VERSION "HNNBNNNYNNNNNNNNNNNNNNNNNNNNNNNNNNNNNNNNNN/4/%%%/4/'%**4NNN///"

NS_ :

BS_:

BU_: Airbag BAP_Tester ICAS1_Gateway ICAS1_KommunikationsServer LE1 LE2 Motor_BEV Schaltbetaetigung

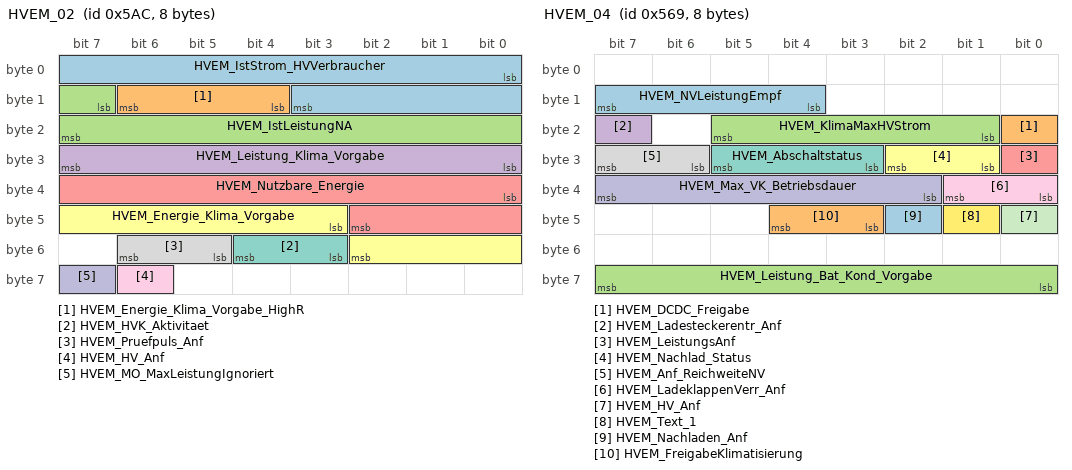
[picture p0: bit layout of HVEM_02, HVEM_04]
BO_ 1452 HVEM_02: 8 ICAS1_Gateway
 SG_ HVEM_IstStrom_HVVerbraucher : 0|12@1+ (0.1,-204.7) [-204.7|204.6] "Unit_Amper"  Vector__XXX
 SG_ HVEM_Energie_Klima_Vorgabe_HighR : 12|3@1+ (10,0) [0|50] "Unit_WattHour"  Vector__XXX
 SG_ HVEM_IstLeistungNA : 15|9@1+ (50,0) [0|25450] "Unit_Watt"  Motor_BEV
 SG_ HVEM_Leistung_Klima_Vorgabe : 24|8@1+ (50,0) [0|12650] "Unit_Watt"  Vector__XXX
 SG_ HVEM_Nutzbare_Energie : 32|11@1+ (50,0) [0|102200] "Unit_WattHour"  Vector__XXX
 SG_ HVEM_Energie_Klima_Vorgabe : 43|8@1+ (50,0) [0|12650] "Unit_WattHour"  Vector__XXX
 SG_ HVEM_HVK_Aktivitaet : 51|2@1+ (1.0,0.0) [0.0|3] ""  Motor_BEV
 SG_ HVEM_Pruefpuls_Anf : 53|2@1+ (1.0,0.0) [0.0|3] ""  Motor_BEV
 SG_ HVEM_HV_Anf : 62|1@1+ (1.0,0.0) [0.0|1] ""  Motor_BEV
 SG_ HVEM_MO_MaxLeistungIgnoriert : 63|1@1+ (1.0,0.0) [0.0|1] ""  Vector__XXX

BO_ 1385 HVEM_04: 8 ICAS1_Gateway
 SG_ HVEM_NVLeistungEmpf : 12|4@1+ (100,0) [0|1500] "Unit_Watt"  Vector__XXX
 SG_ HVEM_DCDC_Freigabe : 16|1@1+ (1.0,0.0) [0.0|1] ""  Motor_BEV
 SG_ HVEM_KlimaMaxHVStrom : 17|5@1+ (1,0) [0|31] "Unit_Amper"  Vector__XXX
 SG_ HVEM_Ladesteckerentr_Anf : 23|1@1+ (1.0,0.0) [0.0|1] ""  Vector__XXX
 SG_ HVEM_LeistungsAnf : 24|1@1+ (1.0,0.0) [0.0|1] ""  Vector__XXX
 SG_ HVEM_Nachlad_Status : 25|2@1+ (1.0,0.0) [0.0|3] ""  Vector__XXX
 SG_ HVEM_Abschaltstatus : 27|3@1+ (1.0,0.0) [0.0|7] ""  Vector__XXX
 SG_ HVEM_Anf_ReichweiteNV : 30|2@1+ (1.0,0.0) [0.0|3] ""  Vector__XXX
 SG_ HVEM_LadeklappenVerr_Anf : 32|2@1+ (1.0,0.0) [0.0|3] ""  Vector__XXX
 SG_ HVEM_Max_VK_Betriebsdauer : 34|6@1+ (1,0) [0|60] "Unit_Minut"  Vector__XXX
 SG_ HVEM_HV_Anf : 40|1@1+ (1.0,0.0) [0.0|1] ""  Vector__XXX
 SG_ HVEM_Text_1 : 41|1@1+ (1.0,0.0) [0.0|1] ""  Vector__XXX
 SG_ HVEM_Nachladen_Anf : 42|1@1+ (1.0,0.0) [0.0|1] ""  Vector__XXX
 SG_ HVEM_FreigabeKlimatisierung : 43|2@1+ (1.0,0.0) [0.0|3] ""  Vector__XXX
 SG_ HVEM_Leistung_Bat_Kond_Vorgabe : 56|8@1+ (50,0) [0|12650] "Unit_Watt"  Vector__XXX

BO_ 1283 HVK_01: 8 Motor_BEV
 SG_ HVK_01_CRC : 0|8@1+ (1,0) [0|255] ""  ICAS1_Gateway,LE1,LE2
 SG_ HVK_01_BZ : 8|4@1+ (1,0) [0|15] ""  ICAS1_Gateway,LE1,LE2
 SG_ HVK_Istmodus_Anf : 12|1@1+ (1.0,0.0) [0.0|1] ""  ICAS1_Gateway
 SG_ HVK_TN1_Sollmodus : 13|2@1+ (1.0,0.0) [0.0|3] ""  ICAS1_Gateway
 SG_ HVK_Vorladung_aktiv : 15|1@1+ (1.0,0.0) [0.0|1] ""  ICAS1_Gateway
 SG_ HVK_BMS_Sollmodus : 24|3@1+ (1.0,0.0) [0.0|7] ""  ICAS1_Gateway
 SG_ HVK_DCDC_Sollmodus : 27|3@1+ (1.0,0.0) [0.0|7] ""  ICAS1_Gateway
 SG_ HVK_EKK_Sollmodus : 30|3@1+ (1.0,0.0) [0.0|7] ""  ICAS1_Gateway
 SG_ HVK_HVPTC_Sollmodus : 33|3@1+ (1.0,0.0) [0.0|7] ""  ICAS1_Gateway
 SG_ HVK_HVLM_Sollmodus : 36|3@1+ (1.0,0.0) [0.0|7] ""  ICAS1_Gateway
 SG_ HVK_HV_Netz_Warnungen : 39|2@1+ (1.0,0.0) [0.0|3] ""  ICAS1_Gateway,ICAS1_KommunikationsServer
 SG_ HV_Bordnetz_aktiv : 41|1@1+ (1.0,0.0) [0.0|1] ""  ICAS1_Gateway,LE1,LE2
 SG_ HV_Bordnetz_Fehler : 42|1@1+ (1.0,0.0) [0.0|1] ""  ICAS1_Gateway
 SG_ HVK_Gesamtst_Spgfreiheit : 43|2@1+ (1.0,0.0) [0.0|3] ""  ICAS1_Gateway,ICAS1_KommunikationsServer
 SG_ HVK_AktiveEntladung_Anf : 45|1@1+ (1.0,0.0) [0.0|1] ""  ICAS1_Gateway,LE1,LE2
 SG_ HVK_HVEM_Freigabe : 46|2@1+ (1.0,0.0) [0.0|3] ""  ICAS1_Gateway
 SG_ HVK_Notentladung_Anf : 48|2@1+ (1.0,0.0) [0.0|3] ""  ICAS1_Gateway,LE1,LE2
 SG_ HVK_Iso_Messung_Start : 50|3@1+ (1.0,0.0) [0.0|7] ""  ICAS1_Gateway
 SG_ HVK_Ladebereit : 53|3@1+ (1.0,0.0) [0.0|7] ""  ICAS1_Gateway
 SG_ HVK_PPulsFreigabe : 56|2@1+ (1.0,0.0) [0.0|3] ""  ICAS1_Gateway

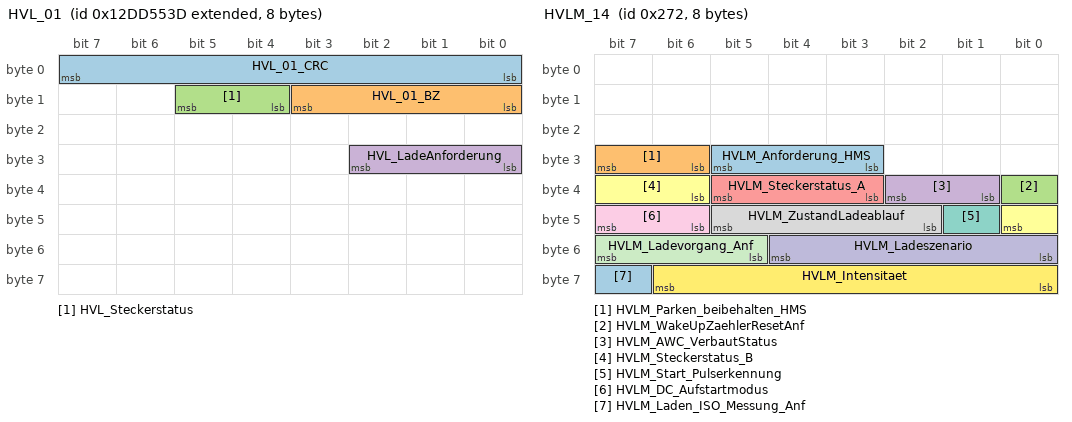
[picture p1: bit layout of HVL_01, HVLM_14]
BO_ 2463978813 HVL_01: 8 ICAS1_Gateway
 SG_ HVL_01_CRC : 0|8@1+ (1,0) [0|255] ""  Motor_BEV
 SG_ HVL_01_BZ : 8|4@1+ (1,0) [0|15] ""  Motor_BEV
 SG_ HVL_Steckerstatus : 12|2@1+ (1.0,0.0) [0.0|3] ""  Motor_BEV
 SG_ HVL_LadeAnforderung : 24|3@1+ (1.0,0.0) [0.0|7] ""  Motor_BEV

BO_ 626 HVLM_14: 8 ICAS1_Gateway
 SG_ HVLM_Anforderung_HMS : 27|3@1+ (1.0,0.0) [0.0|7] ""  Vector__XXX
 SG_ HVLM_Parken_beibehalten_HMS : 30|2@1+ (1.0,0.0) [0.0|3] ""  Vector__XXX
 SG_ HVLM_WakeUpZaehlerResetAnf : 32|1@1+ (1.0,0.0) [0.0|1] ""  Vector__XXX
 SG_ HVLM_AWC_VerbautStatus : 33|2@1+ (1.0,0.0) [0.0|3] ""  Motor_BEV
 SG_ HVLM_Steckerstatus_A : 35|3@1+ (1.0,0.0) [0.0|7] ""  Motor_BEV
 SG_ HVLM_Steckerstatus_B : 38|3@1+ (1.0,0.0) [0.0|7] ""  Vector__XXX
 SG_ HVLM_Start_Pulserkennung : 41|1@1+ (1.0,0.0) [0.0|1] ""  Vector__XXX
 SG_ HVLM_ZustandLadeablauf : 42|4@1+ (1.0,0.0) [0.0|15] ""  Motor_BEV
 SG_ HVLM_DC_Aufstartmodus : 46|2@1+ (1.0,0.0) [0.0|3] ""  Motor_BEV
 SG_ HVLM_Ladeszenario : 48|5@1+ (1.0,0.0) [0.0|31] ""  Vector__XXX
 SG_ HVLM_Ladevorgang_Anf : 53|3@1+ (1.0,0.0) [0.0|7] ""  Motor_BEV
 SG_ HVLM_Intensitaet : 56|7@1+ (1,0) [0|100] "Unit_PerCent"  Vector__XXX
 SG_ HVLM_Laden_ISO_Messung_Anf : 63|1@1+ (1.0,0.0) [0.0|1] ""  Motor_BEV

BO_ 268 IMMO_CORD_01: 8 Motor_BEV
 SG_ ImoCord_Auth_Aufforderung_WFS : 63|1@1+ (1.0,0.0) [0.0|1] ""  LE1,LE2

BO_ 23 IMMO_MSG3_Antwort: 8 ICAS1_Gateway
 SG_ WFS_IMMO_MSG3_CRC : 0|32@1+ (1.0,0.0) [0.0|4294967295] ""  LE2
 SG_ WFS_IMMO_MSG3_Status : 56|8@1+ (1,0) [0|255] ""  LE2

BO_ 25 IMMO_MSG4_Antwort: 8 ICAS1_Gateway
 SG_ WFS_IMMO_MSG4_CRC : 0|32@1+ (1.0,0.0) [0.0|4294967295] ""  LE1
 SG_ WFS_IMMO_MSG4_Status : 56|8@1+ (1,0) [0|255] ""  LE1

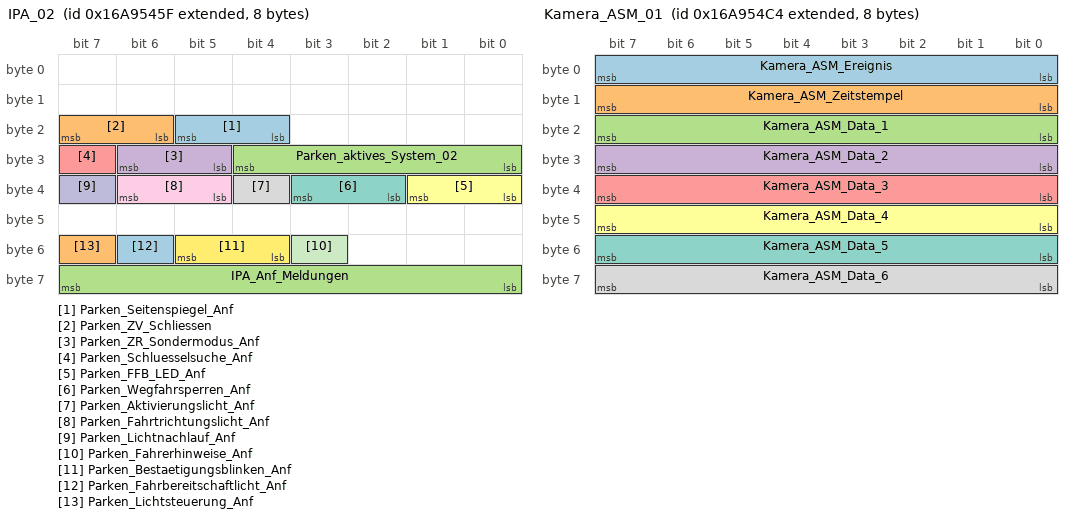
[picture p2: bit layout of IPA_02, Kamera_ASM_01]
BO_ 2527679583 IPA_02: 8 ICAS1_Gateway
 SG_ Parken_Seitenspiegel_Anf : 20|2@1+ (1.0,0.0) [0.0|3] ""  Vector__XXX
 SG_ Parken_ZV_Schliessen : 22|2@1+ (1.0,0.0) [0.0|3] ""  Vector__XXX
 SG_ Parken_aktives_System_02 : 24|5@1+ (1.0,0.0) [0.0|31] ""  Vector__XXX
 SG_ Parken_ZR_Sondermodus_Anf : 29|2@1+ (1.0,0.0) [0.0|3] ""  Vector__XXX
 SG_ Parken_Schluesselsuche_Anf : 31|1@1+ (1.0,0.0) [0.0|1] ""  Vector__XXX
 SG_ Parken_FFB_LED_Anf : 32|2@1+ (1.0,0.0) [0.0|3] ""  Vector__XXX
 SG_ Parken_Wegfahrsperren_Anf : 34|2@1+ (1.0,0.0) [0.0|3] ""  LE1,LE2
 SG_ Parken_Aktivierungslicht_Anf : 36|1@1+ (1.0,0.0) [0.0|1] ""  Vector__XXX
 SG_ Parken_Fahrtrichtungslicht_Anf : 37|2@1+ (1.0,0.0) [0.0|3] ""  Vector__XXX
 SG_ Parken_Lichtnachlauf_Anf : 39|1@1+ (1.0,0.0) [0.0|1] ""  Vector__XXX
 SG_ Parken_Fahrerhinweise_Anf : 51|1@1+ (1.0,0.0) [0.0|1] ""  Vector__XXX
 SG_ Parken_Bestaetigungsblinken_Anf : 52|2@1+ (1.0,0.0) [0.0|3] ""  Vector__XXX
 SG_ Parken_Fahrbereitschaftlicht_Anf : 54|1@1+ (1.0,0.0) [0.0|1] ""  Vector__XXX
 SG_ Parken_Lichtsteuerung_Anf : 55|1@1+ (1.0,0.0) [0.0|1] ""  Vector__XXX
 SG_ IPA_Anf_Meldungen : 56|8@1+ (1.0,0.0) [0.0|255] ""  Vector__XXX

BO_ 1813 ISO_Airbag_01_Req: 8 ICAS1_Gateway
 SG_ ISO_Airbag_01_Req_Data : 0|64@1+ (1.0,0.0) [0.0|18446744073709551615] ""  Airbag

BO_ 1919 ISO_Airbag_01_Resp: 8 Airbag
 SG_ ISO_Airbag_01_Resp_Data : 0|64@1+ (1.0,0.0) [0.0|18446744073709551615] ""  ICAS1_Gateway

BO_ 1792 ISO_Funktionaler_Req_All: 8 ICAS1_Gateway
 SG_ ISO_ALL_01_Req_Data : 0|64@1+ (1.0,0.0) [0.0|18446744073709551615] ""  Airbag,LE1,LE2,Motor_BEV

BO_ 2621440021 ISOx_Airbag_01_Req_FD: 64 ICAS1_Gateway
 SG_ ISOx_Airbag_01_Req_FD_Data : 0|512@1+ (1.0,0.0) [0.0|13407807929942597099574024998205846127479365820592393377723561443721764030073546976801874298166903427690031858186486050853753882811946569946433649006084095] ""  Airbag

BO_ 2621571093 ISOx_Airbag_01_Resp_FD: 64 Airbag
 SG_ ISOx_Airbag_01_Resp_FD_Data : 0|512@1+ (1.0,0.0) [0.0|13407807929942597099574024998205846127479365820592393377723561443721764030073546976801874298166903427690031858186486050853753882811946569946433649006084095] ""  ICAS1_Gateway

BO_ 2549874812 ISOx_EMotor_01_Req: 8 ICAS1_Gateway
 SG_ ISO_EMotor_01_Req_Data : 0|64@1+ (1.0,0.0) [0.0|18446744073709551615] ""  LE1

BO_ 2621440124 ISOx_EMotor_01_Req_FD: 64 ICAS1_Gateway
 SG_ ISOx_EMotor_01_Req_FD_Data : 0|512@1+ (1.0,0.0) [0.0|13407807929942597099574024998205846127479365820592393377723561443721764030073546976801874298166903427690031858186486050853753882811946569946433649006084095] ""  LE1

BO_ 2550005884 ISOx_EMotor_01_Resp: 8 LE1
 SG_ ISO_EMotor_01_Resp_Data : 0|64@1+ (1.0,0.0) [0.0|18446744073709551615] ""  ICAS1_Gateway

BO_ 2621571196 ISOx_EMotor_01_Resp_FD: 64 LE1
 SG_ ISOx_EMotor_01_Resp_FD_Data : 0|512@1+ (1.0,0.0) [0.0|13407807929942597099574024998205846127479365820592393377723561443721764030073546976801874298166903427690031858186486050853753882811946569946433649006084095] ""  ICAS1_Gateway

BO_ 2549874872 ISOx_EMotor_02_Req: 8 ICAS1_Gateway
 SG_ ISO_EMotor_02_Req_Data : 0|64@1+ (1.0,0.0) [0.0|18446744073709551615] ""  LE2

BO_ 2621440184 ISOx_EMotor_02_Req_FD: 64 ICAS1_Gateway
 SG_ ISOx_EMotor_02_Req_FD_Data : 0|512@1+ (1.0,0.0) [0.0|13407807929942597099574024998205846127479365820592393377723561443721764030073546976801874298166903427690031858186486050853753882811946569946433649006084095] ""  LE2

BO_ 2550005944 ISOx_EMotor_02_Resp: 8 LE2
 SG_ ISO_EMotor_02_Resp_Data : 0|64@1+ (1.0,0.0) [0.0|18446744073709551615] ""  ICAS1_Gateway

BO_ 2621571256 ISOx_EMotor_02_Resp_FD: 64 LE2
 SG_ ISOx_EMotor_02_Resp_FD_Data : 0|512@1+ (1.0,0.0) [0.0|13407807929942597099574024998205846127479365820592393377723561443721764030073546976801874298166903427690031858186486050853753882811946569946433649006084095] ""  ICAS1_Gateway

BO_ 2621505536 ISOx_Funkt_Req_All_FD: 64 ICAS1_Gateway
 SG_ ISOx_Funkt_Req_All_FD_Data : 0|512@1+ (1.0,0.0) [0.0|13407807929942597099574024998205846127479365820592393377723561443721764030073546976801874298166903427690031858186486050853753882811946569946433649006084095] ""  Airbag,LE1,LE2,Motor_BEV

BO_ 2549874806 ISOx_MO_01_Req: 8 ICAS1_Gateway
 SG_ ISOx_MO_01_Req_Data : 0|64@1+ (1.0,0.0) [0.0|18446744073709551615] ""  Motor_BEV

BO_ 2621440118 ISOx_MO_01_Req_FD: 64 ICAS1_Gateway
 SG_ ISOx_MO_01_Req_FD_Data : 0|512@1+ (1.0,0.0) [0.0|13407807929942597099574024998205846127479365820592393377723561443721764030073546976801874298166903427690031858186486050853753882811946569946433649006084095] ""  Motor_BEV

BO_ 2550005878 ISOx_MO_01_Resp: 8 Motor_BEV
 SG_ ISOx_MO_01_Resp_Data : 0|64@1+ (1.0,0.0) [0.0|18446744073709551615] ""  ICAS1_Gateway

BO_ 2621571190 ISOx_MO_01_Resp_FD: 64 Motor_BEV
 SG_ ISOx_MO_01_Resp_FD_Data : 0|512@1+ (1.0,0.0) [0.0|13407807929942597099574024998205846127479365820592393377723561443721764030073546976801874298166903427690031858186486050853753882811946569946433649006084095] ""  ICAS1_Gateway

BO_ 2527679684 Kamera_ASM_01: 8 ICAS1_Gateway
 SG_ Kamera_ASM_Ereignis : 0|8@1+ (1,0) [1|254] ""  Airbag
 SG_ Kamera_ASM_Zeitstempel : 8|8@1+ (0.08,0) [0.00|20.32] "Unit_Secon"  Airbag
 SG_ Kamera_ASM_Data_1 : 16|8@1+ (1,0) [0|255] ""  Airbag
 SG_ Kamera_ASM_Data_2 : 24|8@1+ (1,0) [0|255] ""  Airbag
 SG_ Kamera_ASM_Data_3 : 32|8@1+ (1,0) [0|255] ""  Airbag
 SG_ Kamera_ASM_Data_4 : 40|8@1+ (1,0) [0|255] ""  Airbag
 SG_ Kamera_ASM_Data_5 : 48|8@1+ (1,0) [0|255] ""  Airbag
 SG_ Kamera_ASM_Data_6 : 56|8@1+ (1,0) [0|255] ""  Airbag

BO_ 960 Klemmen_Status_01: 4 ICAS1_Gateway
 SG_ Klemmen_Status_01_CRC : 0|8@1+ (1,0) [0|255] ""  Motor_BEV
 SG_ Klemmen_Status_01_BZ : 8|4@1+ (1,0) [0|15] ""  Motor_BEV
 SG_ RSt_Fahrerhinweise : 12|4@1+ (1.0,0.0) [0.0|15] ""  Vector__XXX
 SG_ ZAS_Kl_S : 16|1@1+ (1.0,0.0) [0.0|1] ""  Vector__XXX
 SG_ ZAS_Kl_15 : 17|1@1+ (1.0,0.0) [0.0|1] ""  Airbag,LE1,LE2,Motor_BEV,Schaltbetaetigung
 SG_ ZAS_Kl_X : 18|1@1+ (1.0,0.0) [0.0|1] ""  Vector__XXX
 SG_ ZAS_Kl_50_Startanforderung : 19|1@1+ (1.0,0.0) [0.0|1] ""  Motor_BEV
 SG_ BCM_Remotestart_Betrieb : 20|1@1+ (1.0,0.0) [0.0|1] ""  Vector__XXX
 SG_ ZAS_Kl_Infotainment : 21|1@1+ (1.0,0.0) [0.0|1] ""  Vector__XXX
 SG_ BCM_Remotestart_KL15_Anf : 22|1@1+ (1.0,0.0) [0.0|1] ""  Vector__XXX
 SG_ BCM_Remotestart_MO_Start : 23|1@1+ (1.0,0.0) [0.0|1] ""  Vector__XXX
 SG_ KST_Warn_P1_ZST_def : 24|1@1+ (1.0,0.0) [0.0|1] ""  Vector__XXX
 SG_ KST_Warn_P2_ZST_def : 25|1@1+ (1.0,0.0) [0.0|1] ""  Vector__XXX
 SG_ KST_Fahrerhinweis_1 : 26|1@1+ (1.0,0.0) [0.0|1] ""  Vector__XXX
 SG_ KST_Fahrerhinweis_2 : 27|1@1+ (1.0,0.0) [0.0|1] ""  Vector__XXX
 SG_ BCM_Ausparken_Betrieb : 28|1@1+ (1.0,0.0) [0.0|1] ""  Vector__XXX
 SG_ KST_Fahrerhinweis_4 : 29|1@1+ (1.0,0.0) [0.0|1] ""  Vector__XXX
 SG_ KST_Fahrerhinweis_5 : 30|1@1+ (1.0,0.0) [0.0|1] ""  Vector__XXX
 SG_ KST_Fahrerhinweis_6 : 31|1@1+ (1.0,0.0) [0.0|1] ""  Vector__XXX

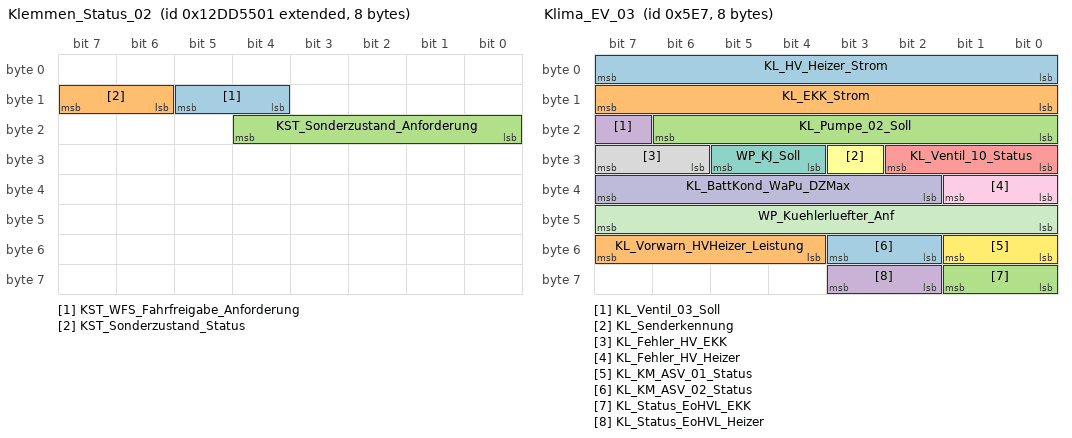
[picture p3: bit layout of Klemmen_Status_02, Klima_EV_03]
BO_ 2463978753 Klemmen_Status_02: 8 ICAS1_Gateway
 SG_ KST_WFS_Fahrfreigabe_Anforderung : 12|2@1+ (1.0,0.0) [0.0|3] ""  LE1,LE2
 SG_ KST_Sonderzustand_Status : 14|2@1+ (1.0,0.0) [0.0|3] ""  LE1,LE2
 SG_ KST_Sonderzustand_Anforderung : 16|5@1+ (1.0,0.0) [0.0|31] ""  LE1,LE2

BO_ 1420 Klemmen_Steuerung_01: 8 ICAS1_Gateway
 SG_ Klemmen_Steuerung_01_CRC : 0|8@1+ (1,0) [0|255] ""  Vector__XXX
 SG_ Klemmen_Steuerung_01_BZ : 8|4@1+ (1,0) [0|15] ""  Vector__XXX
 SG_ KST_Anf_Klemme_15 : 12|1@1+ (1.0,0.0) [0.0|1] ""  Vector__XXX
 SG_ KST_Anf_Klemme_50 : 13|1@1+ (1.0,0.0) [0.0|1] ""  Motor_BEV
 SG_ KST_Anf_Klemme_S : 14|1@1+ (1.0,0.0) [0.0|1] ""  Vector__XXX
 SG_ KST_Txt_Werkstatt : 15|1@1+ (1.0,0.0) [0.0|1] ""  Vector__XXX
 SG_ KST_Txt_P_Gang : 16|1@1+ (1.0,0.0) [0.0|1] ""  Vector__XXX
 SG_ KST_Txt_Panikabschaltung : 17|1@1+ (1.0,0.0) [0.0|1] ""  Vector__XXX
 SG_ KST_Anf_Klemmenfreigabe_ELV : 18|1@1+ (1.0,0.0) [0.0|1] ""  Vector__XXX
 SG_ KST_Txt_Komfortabschaltung : 19|1@1+ (1.0,0.0) [0.0|1] ""  Vector__XXX
 SG_ KST_ZAT_betaetigt : 20|1@1+ (1.0,0.0) [0.0|1] ""  Vector__XXX
 SG_ KST_Unterdr_Zuendungsmeldung : 21|1@1+ (1.0,0.0) [0.0|1] ""  Vector__XXX
 SG_ KST_aut_Abschaltung_Zuendung : 22|1@1+ (1.0,0.0) [0.0|1] ""  Vector__XXX
 SG_ KST_Anf_Klemmenfreigabe_WFS : 23|1@1+ (1.0,0.0) [0.0|1] ""  Vector__XXX
 SG_ KST_Anf_ZV_Verriegelung : 24|1@1+ (1.0,0.0) [0.0|1] ""  Vector__XXX
 SG_ Relais_VoKo_angesteuert : 25|1@1+ (1.0,0.0) [0.0|1] ""  Vector__XXX
 SG_ RSt_Anforderung_HMS : 26|3@1+ (1.0,0.0) [0.0|7] ""  Vector__XXX
 SG_ KST_Zuendungswarnung : 29|2@1+ (1.0,0.0) [0.0|3] ""  Vector__XXX
 SG_ KST_Fahrer_Info_Text : 31|3@1+ (1.0,0.0) [0.0|7] ""  Vector__XXX

BO_ 949 Klima_11: 8 ICAS1_Gateway
 SG_ KL_Drehz_Anh : 0|1@1+ (1.0,0.0) [0.0|1] ""  Vector__XXX
 SG_ KL_Vorwarn_Komp_ein : 1|1@1+ (1.0,0.0) [0.0|1] ""  Vector__XXX
 SG_ KL_AC_Schalter : 2|1@1+ (1.0,0.0) [0.0|1] ""  Vector__XXX
 SG_ KL_Komp_Moment_alt : 3|1@1+ (1.0,0.0) [0.0|1] ""  Vector__XXX
 SG_ KL_Vorwarn_Zuheizer_ein : 6|1@1+ (1.0,0.0) [0.0|1] ""  Vector__XXX
 SG_ KL_Zustand : 7|1@1+ (1.0,0.0) [0.0|1] ""  Vector__XXX
 SG_ KL_Kompressorkupplung_linear : 8|8@1+ (20,0) [0|4000] "Unit_MilliAmper"  Vector__XXX
 SG_ KL_Charisma_FahrPr : 16|4@1+ (1.0,0.0) [0.0|15] ""  Vector__XXX
 SG_ KL_Charisma_Status : 20|2@1+ (1.0,0.0) [0.0|3] ""  Vector__XXX
 SG_ KL_nachtr_Stopp_Anf : 22|1@1+ (1.0,0.0) [0.0|1] ""  Vector__XXX
 SG_ KL_T_Charge : 23|1@1+ (1.0,0.0) [0.0|1] ""  Vector__XXX
 SG_ KL_Last_Kompr : 24|8@1+ (0.25,0) [0.00|63.50] "Unit_NewtoMeter"  Vector__XXX
 SG_ KL_Spannungs_Anf : 32|2@1+ (1.0,0.0) [0.0|3] ""  Vector__XXX
 SG_ KL_Thermomanagement : 34|2@1+ (1.0,0.0) [0.0|3] ""  Motor_BEV
 SG_ KL_StartStopp_Info : 36|2@1+ (1.0,0.0) [0.0|3] ""  Vector__XXX
 SG_ KL_Freilauf_Info : 38|2@1+ (1.0,0.0) [0.0|3] ""  Vector__XXX
 SG_ KL_Anf_KL : 40|8@1+ (0.4,0) [0.0|101.6] "Unit_PerCent"  Motor_BEV
 SG_ KL_el_Zuheizer_Stufe : 48|3@1+ (1.0,0.0) [0.0|7] ""  Vector__XXX
 SG_ KL_Ausstattung_Klima : 51|3@1+ (1.0,0.0) [0.0|7] ""  Vector__XXX
 SG_ KL_Variante_Standheizung : 54|2@1+ (1.0,0.0) [0.0|3] ""  Vector__XXX
 SG_ KL_Anf_KV : 57|7@1+ (1,0) [0|100] "Unit_PerCent"  Motor_BEV

BO_ 1511 Klima_EV_03: 8 ICAS1_Gateway
 SG_ KL_HV_Heizer_Strom : 0|8@1+ (0.25,0) [0.00|63.50] "Unit_Amper"  Motor_BEV
 SG_ KL_EKK_Strom : 8|8@1+ (0.25,0) [0.00|63.50] "Unit_Amper"  Motor_BEV
 SG_ KL_Pumpe_02_Soll : 16|7@1+ (1,0) [0|100] "Unit_PerCent"  Motor_BEV
 SG_ KL_Ventil_03_Soll : 23|1@1+ (1.0,0.0) [0.0|1] ""  Vector__XXX
 SG_ KL_Ventil_10_Status : 24|3@1+ (1.0,0.0) [0.0|7] ""  Vector__XXX
 SG_ KL_Senderkennung : 27|1@1+ (1.0,0.0) [0.0|1] ""  Vector__XXX
 SG_ WP_KJ_Soll : 28|2@1+ (1.0,0.0) [0.0|3] ""  Vector__XXX
 SG_ KL_Fehler_HV_EKK : 30|2@1+ (1.0,0.0) [0.0|3] ""  Vector__XXX
 SG_ KL_Fehler_HV_Heizer : 32|2@1+ (1.0,0.0) [0.0|3] ""  Vector__XXX
 SG_ KL_BattKond_WaPu_DZMax : 34|6@1+ (2,0) [0|100] "Unit_PerCent"  Vector__XXX
 SG_ WP_Kuehlerluefter_Anf : 40|8@1+ (0.4,0) [0.0|101.6] "Unit_PerCent"  Vector__XXX
 SG_ KL_KM_ASV_01_Status : 48|2@1+ (1.0,0.0) [0.0|3] ""  Vector__XXX
 SG_ KL_KM_ASV_02_Status : 50|2@1+ (1.0,0.0) [0.0|3] ""  Vector__XXX
 SG_ KL_Vorwarn_HVHeizer_Leistung : 52|4@1+ (1.0,0.0) [0.0|15] ""  Vector__XXX
 SG_ KL_Status_EoHVL_EKK : 56|2@1+ (1.0,0.0) [0.0|3] ""  Motor_BEV
 SG_ KL_Status_EoHVL_Heizer : 58|2@1+ (1.0,0.0) [0.0|3] ""  Motor_BEV

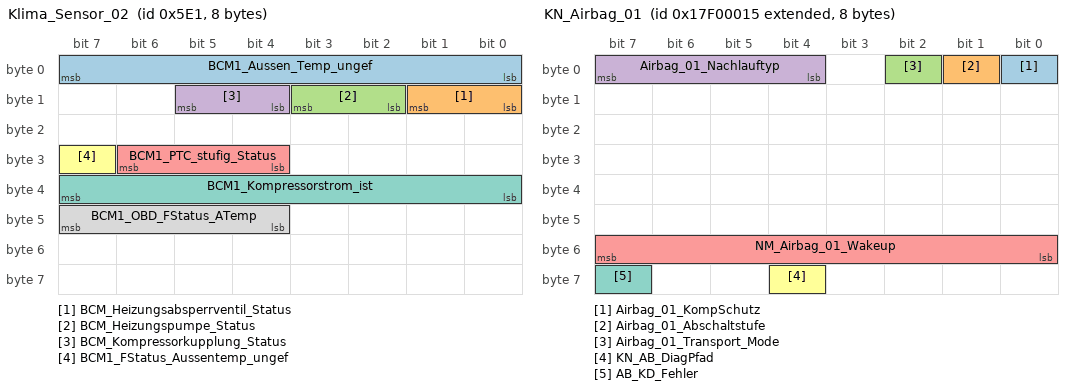
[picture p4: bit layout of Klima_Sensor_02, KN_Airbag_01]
BO_ 1505 Klima_Sensor_02: 8 ICAS1_Gateway
 SG_ BCM1_Aussen_Temp_ungef : 0|8@1+ (0.5,-50) [-50.0|76.0] "Unit_DegreCelsi"  LE1,LE2,Motor_BEV
 SG_ BCM_Heizungsabsperrventil_Status : 8|2@1+ (1.0,0.0) [0.0|3] ""  Vector__XXX
 SG_ BCM_Heizungspumpe_Status : 10|2@1+ (1.0,0.0) [0.0|3] ""  Vector__XXX
 SG_ BCM_Kompressorkupplung_Status : 12|2@1+ (1.0,0.0) [0.0|3] ""  Vector__XXX
 SG_ BCM1_PTC_stufig_Status : 28|3@1+ (1.0,0.0) [0.0|7] ""  Vector__XXX
 SG_ BCM1_FStatus_Aussentemp_ungef : 31|1@1+ (1.0,0.0) [0.0|1] ""  Vector__XXX
 SG_ BCM1_Kompressorstrom_ist : 32|8@1+ (4,0) [0|1000] "Unit_MilliAmper"  Vector__XXX
 SG_ BCM1_OBD_FStatus_ATemp : 44|4@1+ (1.0,0.0) [0.0|15] ""  Vector__XXX

BO_ 2549088277 KN_Airbag_01: 8 Airbag
 SG_ Airbag_01_KompSchutz : 0|1@1+ (1.0,0.0) [0.0|1] ""  Vector__XXX
 SG_ Airbag_01_Abschaltstufe : 1|1@1+ (1.0,0.0) [0.0|1] ""  Vector__XXX
 SG_ Airbag_01_Transport_Mode : 2|1@1+ (1.0,0.0) [0.0|1] ""  Vector__XXX
 SG_ Airbag_01_Nachlauftyp : 4|4@1+ (1.0,0.0) [0.0|15] ""  ICAS1_Gateway
 SG_ NM_Airbag_01_Wakeup : 48|8@1+ (1.0,0.0) [0.0|255] ""  Vector__XXX
 SG_ KN_AB_DiagPfad : 60|1@1+ (1.0,0.0) [0.0|1] ""  ICAS1_Gateway
 SG_ AB_KD_Fehler : 63|1@1+ (1.0,0.0) [0.0|1] ""  ICAS1_Gateway

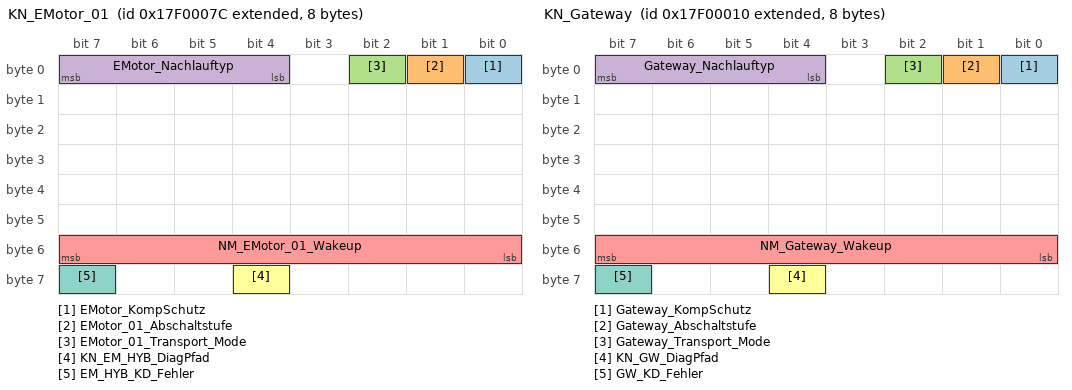
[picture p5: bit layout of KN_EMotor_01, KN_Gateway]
BO_ 2549088380 KN_EMotor_01: 8 LE1
 SG_ EMotor_KompSchutz : 0|1@1+ (1.0,0.0) [0.0|1] ""  Vector__XXX
 SG_ EMotor_01_Abschaltstufe : 1|1@1+ (1.0,0.0) [0.0|1] ""  Vector__XXX
 SG_ EMotor_01_Transport_Mode : 2|1@1+ (1.0,0.0) [0.0|1] ""  Vector__XXX
 SG_ EMotor_Nachlauftyp : 4|4@1+ (1.0,0.0) [0.0|15] ""  ICAS1_Gateway
 SG_ NM_EMotor_01_Wakeup : 48|8@1+ (1.0,0.0) [0.0|255] ""  Vector__XXX
 SG_ KN_EM_HYB_DiagPfad : 60|1@1+ (1.0,0.0) [0.0|1] ""  ICAS1_Gateway
 SG_ EM_HYB_KD_Fehler : 63|1@1+ (1.0,0.0) [0.0|1] ""  ICAS1_Gateway

BO_ 2549088272 KN_Gateway: 8 ICAS1_Gateway
 SG_ Gateway_KompSchutz : 0|1@1+ (1.0,0.0) [0.0|1] ""  Vector__XXX
 SG_ Gateway_Abschaltstufe : 1|1@1+ (1.0,0.0) [0.0|1] ""  Vector__XXX
 SG_ Gateway_Transport_Mode : 2|1@1+ (1.0,0.0) [0.0|1] ""  Vector__XXX
 SG_ Gateway_Nachlauftyp : 4|4@1+ (1.0,0.0) [0.0|15] ""  Vector__XXX
 SG_ NM_Gateway_Wakeup : 48|8@1+ (1.0,0.0) [0.0|255] ""  Vector__XXX
 SG_ KN_GW_DiagPfad : 60|1@1+ (1.0,0.0) [0.0|1] ""  Vector__XXX
 SG_ GW_KD_Fehler : 63|1@1+ (1.0,0.0) [0.0|1] ""  Vector__XXX

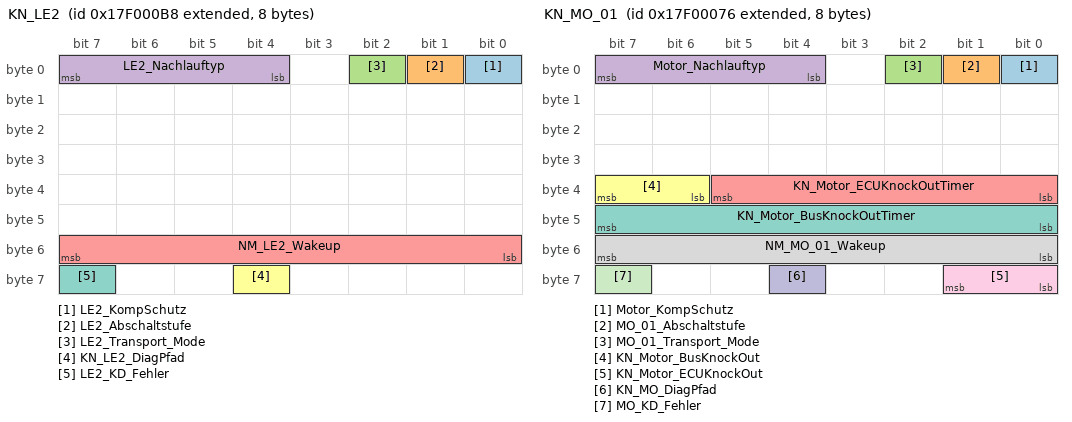
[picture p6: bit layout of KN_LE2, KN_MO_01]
BO_ 2549088440 KN_LE2: 8 LE2
 SG_ LE2_KompSchutz : 0|1@1+ (1.0,0.0) [0.0|1] ""  Vector__XXX
 SG_ LE2_Abschaltstufe : 1|1@1+ (1.0,0.0) [0.0|1] ""  Vector__XXX
 SG_ LE2_Transport_Mode : 2|1@1+ (1.0,0.0) [0.0|1] ""  Vector__XXX
 SG_ LE2_Nachlauftyp : 4|4@1+ (1.0,0.0) [0.0|15] ""  ICAS1_Gateway
 SG_ NM_LE2_Wakeup : 48|8@1+ (1.0,0.0) [0.0|255] ""  Vector__XXX
 SG_ KN_LE2_DiagPfad : 60|1@1+ (1.0,0.0) [0.0|1] ""  ICAS1_Gateway
 SG_ LE2_KD_Fehler : 63|1@1+ (1.0,0.0) [0.0|1] ""  ICAS1_Gateway

BO_ 2549088374 KN_MO_01: 8 Motor_BEV
 SG_ Motor_KompSchutz : 0|1@1+ (1.0,0.0) [0.0|1] ""  Vector__XXX
 SG_ MO_01_Abschaltstufe : 1|1@1+ (1.0,0.0) [0.0|1] ""  Vector__XXX
 SG_ MO_01_Transport_Mode : 2|1@1+ (1.0,0.0) [0.0|1] ""  Vector__XXX
 SG_ Motor_Nachlauftyp : 4|4@1+ (1.0,0.0) [0.0|15] ""  ICAS1_Gateway
 SG_ KN_Motor_ECUKnockOutTimer : 32|6@1+ (1,0) [0|62] "Unit_Minut"  Vector__XXX
 SG_ KN_Motor_BusKnockOut : 38|2@1+ (1.0,0.0) [0.0|3] ""  Vector__XXX
 SG_ KN_Motor_BusKnockOutTimer : 40|8@1+ (1,0) [0|254] ""  Vector__XXX
 SG_ NM_MO_01_Wakeup : 48|8@1+ (1.0,0.0) [0.0|255] ""  Vector__XXX
 SG_ KN_Motor_ECUKnockOut : 56|2@1+ (1.0,0.0) [0.0|3] ""  Vector__XXX
 SG_ KN_MO_DiagPfad : 60|1@1+ (1.0,0.0) [0.0|1] ""  ICAS1_Gateway
 SG_ MO_KD_Fehler : 63|1@1+ (1.0,0.0) [0.0|1] ""  ICAS1_Gateway

BO_ 2621440277 KS_Airbag_01_Req_FD: 16 ICAS1_Gateway
 SG_ KS_Airbag_01_Req_FD_Data : 0|128@1+ (1.0,0.0) [0.0|340282366920938463463374607431768211455] ""  Airbag

BO_ 2621571349 KS_Airbag_01_Resp_FD: 16 Airbag
 SG_ KS_Airbag_01_Resp_FD_Data : 0|128@1+ (1.0,0.0) [0.0|340282366920938463463374607431768211455] ""  ICAS1_Gateway

BO_ 982 Licht_hinten_01: 8 ICAS1_Gateway
 SG_ Licht_hinten_01_BZ : 0|4@1+ (1,0) [0|15] ""  Vector__XXX
 SG_ LH_Aussenlicht_def : 7|1@1+ (1.0,0.0) [0.0|1] ""  Vector__XXX
 SG_ LH_Standlicht_H_aktiv : 8|1@1+ (1.0,0.0) [0.0|1] ""  Vector__XXX
 SG_ LH_Parklicht_HL_aktiv : 9|1@1+ (1.0,0.0) [0.0|1] ""  Vector__XXX
 SG_ LH_Parklicht_HR_aktiv : 10|1@1+ (1.0,0.0) [0.0|1] ""  Vector__XXX
 SG_ LH_Bremslicht_H_aktiv : 11|1@1+ (1.0,0.0) [0.0|1] ""  Vector__XXX
 SG_ LH_Nebelschluss_aktiv : 12|1@1+ (1.0,0.0) [0.0|1] ""  Vector__XXX
 SG_ LH_Rueckfahrlicht_aktiv : 13|1@1+ (1.0,0.0) [0.0|1] ""  Vector__XXX
 SG_ LH_Blinker_HL_akt : 14|1@1+ (1.0,0.0) [0.0|1] ""  Vector__XXX
 SG_ LH_Blinker_HR_akt : 15|1@1+ (1.0,0.0) [0.0|1] ""  Vector__XXX
 SG_ LH_Blinker_li_def : 16|1@1+ (1.0,0.0) [0.0|1] ""  Vector__XXX
 SG_ LH_Bremsl_li_def : 17|1@1+ (1.0,0.0) [0.0|1] ""  Vector__XXX
 SG_ LH_Schlusslicht_li_def : 18|1@1+ (1.0,0.0) [0.0|1] ""  Vector__XXX
 SG_ LH_Rueckf_li_def : 19|1@1+ (1.0,0.0) [0.0|1] ""  Vector__XXX
 SG_ LH_Nebel_li_def : 20|1@1+ (1.0,0.0) [0.0|1] ""  Vector__XXX
 SG_ LH_Schluss_Brems_Nebel_li_def : 21|1@1+ (1.0,0.0) [0.0|1] ""  Vector__XXX
 SG_ LH_Schluss_Brems_Nebel_re_def : 22|1@1+ (1.0,0.0) [0.0|1] ""  Vector__XXX
 SG_ LH_Zusatzschlussl_def : 23|1@1+ (1.0,0.0) [0.0|1] ""  Vector__XXX
 SG_ LH_Schluss_Brems_li_def : 24|1@1+ (1.0,0.0) [0.0|1] ""  Vector__XXX
 SG_ LH_Schluss_Nebel_li_def : 25|1@1+ (1.0,0.0) [0.0|1] ""  Vector__XXX
 SG_ LH_SL_BRL_BLK_li_def : 26|1@1+ (1.0,0.0) [0.0|1] ""  Vector__XXX
 SG_ LH_Brems_Blk_li_def : 27|1@1+ (1.0,0.0) [0.0|1] ""  Vector__XXX
 SG_ LH_Diag_Status_re_def : 28|1@1+ (1.0,0.0) [0.0|1] ""  Vector__XXX
 SG_ LH_Diag_Status_li_def : 29|1@1+ (1.0,0.0) [0.0|1] ""  Vector__XXX
 SG_ LH_Diag_LED_li_def : 30|1@1+ (1.0,0.0) [0.0|1] ""  Vector__XXX
 SG_ LH_Diag_LED_re_def : 31|1@1+ (1.0,0.0) [0.0|1] ""  Vector__XXX
 SG_ LH_Blinker_re_def : 32|1@1+ (1.0,0.0) [0.0|1] ""  Vector__XXX
 SG_ LH_Bremsl_re_def : 33|1@1+ (1.0,0.0) [0.0|1] ""  Vector__XXX
 SG_ LH_Schlusslicht_re_def : 34|1@1+ (1.0,0.0) [0.0|1] ""  Vector__XXX
 SG_ LH_Rueckf_re_def : 35|1@1+ (1.0,0.0) [0.0|1] ""  Vector__XXX
 SG_ LH_Nebel_re_def : 36|1@1+ (1.0,0.0) [0.0|1] ""  Vector__XXX
 SG_ LH_Schluss_Brems_mi_def : 37|1@1+ (1.0,0.0) [0.0|1] ""  Vector__XXX
 SG_ LH_Schluss_Brems_re_def : 40|1@1+ (1.0,0.0) [0.0|1] ""  Vector__XXX
 SG_ LH_Schluss_Nebel_re_def : 41|1@1+ (1.0,0.0) [0.0|1] ""  Vector__XXX
 SG_ LH_SL_BRL_BLK_re_def : 42|1@1+ (1.0,0.0) [0.0|1] ""  Vector__XXX
 SG_ LH_Brems_Blk_re_def : 43|1@1+ (1.0,0.0) [0.0|1] ""  Vector__XXX
 SG_ LH_Kennzl_def : 48|1@1+ (1.0,0.0) [0.0|1] ""  Vector__XXX
 SG_ LH_3_Bremsl_def : 49|1@1+ (1.0,0.0) [0.0|1] ""  Motor_BEV
 SG_ LH_Nebel_mi_def : 50|1@1+ (1.0,0.0) [0.0|1] ""  Vector__XXX
 SG_ LH_Rueckf_mi_def : 51|1@1+ (1.0,0.0) [0.0|1] ""  Vector__XXX
 SG_ LH_Schlusslicht_mi_def : 52|1@1+ (1.0,0.0) [0.0|1] ""  Vector__XXX
 SG_ LH_Bremsl_li_ges_def : 54|1@1+ (1.0,0.0) [0.0|1] ""  Motor_BEV
 SG_ LH_Bremsl_re_ges_def : 55|1@1+ (1.0,0.0) [0.0|1] ""  Motor_BEV
 SG_ LH_Bremsl_mi_def : 61|1@1+ (1.0,0.0) [0.0|1] ""  Vector__XXX
 SG_ BRL_als_SHL : 62|1@1+ (1.0,0.0) [0.0|1] ""  Vector__XXX

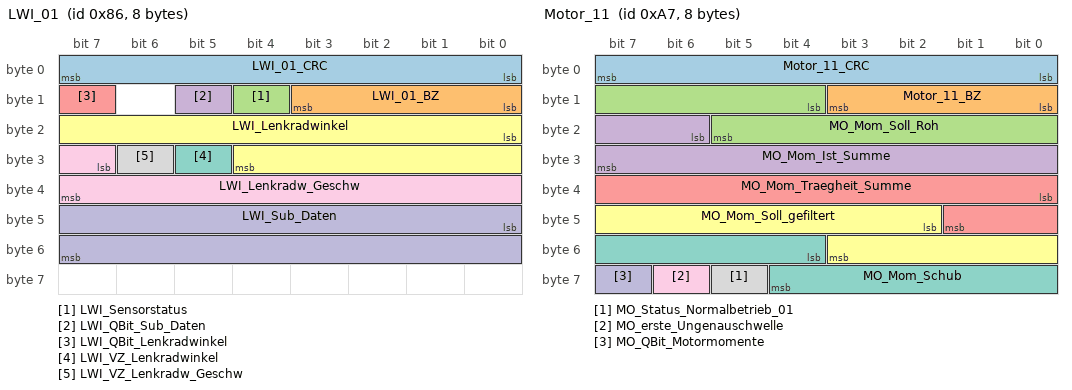
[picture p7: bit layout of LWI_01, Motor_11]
BO_ 134 LWI_01: 8 ICAS1_Gateway
 SG_ LWI_01_CRC : 0|8@1+ (1,0) [0|255] ""  Airbag,Motor_BEV
 SG_ LWI_01_BZ : 8|4@1+ (1,0) [0|15] ""  Airbag,Motor_BEV
 SG_ LWI_Sensorstatus : 12|1@1+ (1.0,0.0) [0.0|1] ""  Airbag,Motor_BEV
 SG_ LWI_QBit_Sub_Daten : 13|1@1+ (1.0,0.0) [0.0|1] ""  Vector__XXX
 SG_ LWI_QBit_Lenkradwinkel : 15|1@1+ (1.0,0.0) [0.0|1] ""  Airbag,Motor_BEV
 SG_ LWI_Lenkradwinkel : 16|13@1+ (0.1,0) [0.0|800.0] "Unit_DegreOfArc"  Airbag,Motor_BEV
 SG_ LWI_VZ_Lenkradwinkel : 29|1@1+ (1.0,0.0) [0.0|1] ""  Airbag,Motor_BEV
 SG_ LWI_VZ_Lenkradw_Geschw : 30|1@1+ (1.0,0.0) [0.0|1] ""  Vector__XXX
 SG_ LWI_Lenkradw_Geschw : 31|9@1+ (5,0) [0|2500] "Unit_DegreOfArcPerSecon"  Airbag
 SG_ LWI_Sub_Daten : 40|16@1+ (1,0) [0|65535] ""  Vector__XXX

BO_ 817 MFL_01: 8 ICAS1_Gateway
 SG_ MFL_Zaehler : 0|4@1+ (1,0) [0|15] ""  Vector__XXX
 SG_ MFL_Toggle : 4|1@1+ (1,0) [0|1] ""  Vector__XXX
 SG_ MFL_Lokalaktiv : 5|1@1+ (1.0,0.0) [0.0|1] ""  Vector__XXX
 SG_ MFL_M_Taste : 6|1@1+ (1.0,0.0) [0.0|1] ""  Vector__XXX
 SG_ MFL_Paddle_Verbau : 7|1@1+ (1.0,0.0) [0.0|1] ""  Vector__XXX
 SG_ MFL_Tastencode_1 : 8|8@1+ (1.0,0.0) [0.0|255] ""  Vector__XXX
 SG_ MFL_Tastencode_2 : 16|8@1+ (1.0,0.0) [0.0|255] ""  Vector__XXX
 SG_ MFL_Eventcode_1 : 24|4@1+ (1.0,0.0) [0.0|15] ""  Vector__XXX
 SG_ MFL_Eventcode_2 : 28|4@1+ (1.0,0.0) [0.0|15] ""  Vector__XXX
 SG_ MFL_Marke : 32|4@1+ (1.0,0.0) [0.0|15] ""  Vector__XXX
 SG_ MFL_Variante : 36|4@1+ (1,0) [0|15] ""  Vector__XXX
 SG_ MFL_Dummy_0_Signal_1 : 40|8@1+ (1.0,0.0) [0.0|255] ""  Vector__XXX
 SG_ MFL_Tip_Down : 48|1@1+ (1.0,0.0) [0.0|1] ""  Motor_BEV
 SG_ MFL_Tip_Up : 49|1@1+ (1.0,0.0) [0.0|1] ""  Motor_BEV
 SG_ MFL_SatModul_links_Err : 50|1@1+ (1.0,0.0) [0.0|1] ""  Vector__XXX
 SG_ MFL_SatModul_rechts_Err : 51|1@1+ (1.0,0.0) [0.0|1] ""  Vector__XXX
 SG_ MFL_Dummy_0_Signal_2 : 52|1@1+ (1.0,0.0) [0.0|1] ""  Vector__XXX
 SG_ MFL_Dummy_0_Signal_3 : 53|1@1+ (1.0,0.0) [0.0|1] ""  Vector__XXX
 SG_ MFL_LR_HZG_Status : 54|1@1+ (1.0,0.0) [0.0|1] ""  Vector__XXX
 SG_ MFL_LR_HZG_Err : 55|1@1+ (1.0,0.0) [0.0|1] ""  Vector__XXX
 SG_ MFL_Signalhorn : 56|1@1+ (1.0,0.0) [0.0|1] ""  Vector__XXX
 SG_ MFL_Signalhorn_Err : 57|1@1+ (1.0,0.0) [0.0|1] ""  Vector__XXX
 SG_ MFL_Tip_links_Err : 58|1@1+ (1.0,0.0) [0.0|1] ""  Vector__XXX
 SG_ MFL_Tip_rechts_Err : 59|1@1+ (1.0,0.0) [0.0|1] ""  Vector__XXX
 SG_ MFL_Taste_links_Err : 60|1@1+ (1.0,0.0) [0.0|1] ""  Vector__XXX
 SG_ MFL_Taste_rechts_Err : 61|1@1+ (1.0,0.0) [0.0|1] ""  Vector__XXX
 SG_ MFL_ECU_Err : 62|1@1+ (1.0,0.0) [0.0|1] ""  Vector__XXX
 SG_ MFL_Response_Err : 63|1@1+ (1.0,0.0) [0.0|1] ""  Vector__XXX

BO_ 15 MO_SOPC: 1 Motor_BEV
 SG_ MO_SOPC : 0|1@1+ (1.0,0.0) [0.0|1] ""  Vector__XXX

BO_ 1600 Motor_07: 8 Motor_BEV
 SG_ MO_QBit_Ansaugluft_Temp : 0|1@1+ (1.0,0.0) [0.0|1] ""  Vector__XXX
 SG_ MO_QBit_Oel_Temp : 1|1@1+ (1.0,0.0) [0.0|1] ""  Vector__XXX
 SG_ MO_QBit_Kuehlmittel_Temp : 2|1@1+ (1.0,0.0) [0.0|1] ""  Vector__XXX
 SG_ MO_KL15_Abschaltempfehlung : 3|1@1+ (1.0,0.0) [0.0|1] ""  Vector__XXX
 SG_ MO_HYB_Fehler_HV_Netz : 4|1@1+ (1.0,0.0) [0.0|1] ""  Vector__XXX
 SG_ MO_aktives_Getriebeheizen : 5|1@1+ (1.0,0.0) [0.0|1] ""  Vector__XXX
 SG_ MO_Absperrventil_oeffnen : 6|2@1+ (1.0,0.0) [0.0|3] ""  Vector__XXX
 SG_ MO_Ansaugluft_Temp : 8|8@1+ (0.75,-48) [-48.00|141.75] "Unit_DegreCelsi"  Vector__XXX
 SG_ MO_Oel_Temp : 16|8@1+ (1,-60) [-60|192] "Unit_DegreCelsi"  Vector__XXX
 SG_ MO_Kuehlmittel_Temp : 24|8@1+ (0.75,-48) [-48.00|141.75] "Unit_DegreCelsi"  Vector__XXX
 SG_ MO_Hoeheninfo : 32|8@1+ (0.00781,0) [0.00000|1.98374] ""  Vector__XXX
 SG_ MO_Kennfeldk : 40|1@1+ (1.0,0.0) [0.0|1] ""  Vector__XXX
 SG_ MO_Versionsinfo_02 : 41|5@1+ (1.0,0.0) [0.0|31] ""  Vector__XXX
 SG_ MO_QBit_Hoeheninfo : 46|1@1+ (1.0,0.0) [0.0|1] ""  Vector__XXX
 SG_ MO_Getriebe_kuehlen : 47|1@1+ (1.0,0.0) [0.0|1] ""  Vector__XXX
 SG_ MO_Mom_Traegheit_02 : 48|5@1+ (0.01,0) [0.00|0.31] "Unit_KiloGramMeterSquar"  Vector__XXX
 SG_ MO_Heizungspumpenansteuerung : 53|4@1+ (10,0) [0|100] "Unit_PerCent"  Vector__XXX
 SG_ MO_SpannungsAnf : 57|1@1+ (1.0,0.0) [0.0|1] ""  Vector__XXX
 SG_ MO_Nachlaufzeit_Heizungspumpe : 58|6@1+ (15,0) [0|945] "Unit_Secon"  Vector__XXX

BO_ 167 Motor_11: 8 Motor_BEV
 SG_ Motor_11_CRC : 0|8@1+ (1,0) [0|255] ""  ICAS1_Gateway
 SG_ Motor_11_BZ : 8|4@1+ (1,0) [0|15] ""  ICAS1_Gateway
 SG_ MO_Mom_Soll_Roh : 12|10@1+ (1,-509) [-509|509] ""  ICAS1_Gateway
 SG_ MO_Mom_Ist_Summe : 22|10@1+ (1,-509) [-509|509] ""  ICAS1_Gateway
 SG_ MO_Mom_Traegheit_Summe : 32|10@1+ (1,-509) [-509|509] ""  ICAS1_Gateway
 SG_ MO_Mom_Soll_gefiltert : 42|10@1+ (1,-509) [-509|509] ""  ICAS1_Gateway
 SG_ MO_Mom_Schub : 52|9@1+ (1,-509) [-509|0] ""  ICAS1_Gateway
 SG_ MO_Status_Normalbetrieb_01 : 61|1@1+ (1.0,0.0) [0.0|1] ""  ICAS1_Gateway
 SG_ MO_erste_Ungenauschwelle : 62|1@1+ (1.0,0.0) [0.0|1] ""  ICAS1_Gateway
 SG_ MO_QBit_Motormomente : 63|1@1+ (1.0,0.0) [0.0|1] ""  ICAS1_Gateway

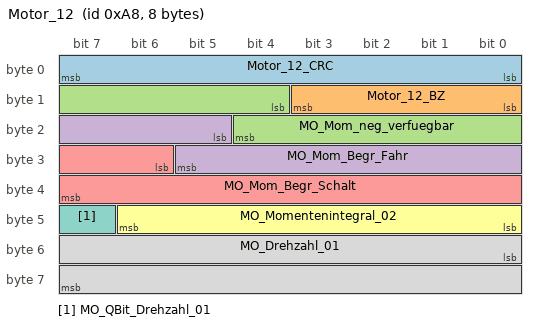
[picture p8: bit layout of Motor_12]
BO_ 168 Motor_12: 8 Motor_BEV
 SG_ Motor_12_CRC : 0|8@1+ (1,0) [0|255] ""  ICAS1_Gateway
 SG_ Motor_12_BZ : 8|4@1+ (1,0) [0|15] ""  ICAS1_Gateway
 SG_ MO_Mom_neg_verfuegbar : 12|9@1+ (1,-509) [-509|0] ""  ICAS1_Gateway
 SG_ MO_Mom_Begr_Fahr : 21|9@1+ (1,0) [0|509] ""  ICAS1_Gateway
 SG_ MO_Mom_Begr_Schalt : 30|10@1+ (1,-509) [-509|509] ""  ICAS1_Gateway
 SG_ MO_Momentenintegral_02 : 40|7@1+ (1,0) [0|100] "Unit_PerCent"  ICAS1_Gateway
 SG_ MO_QBit_Drehzahl_01 : 47|1@1+ (1.0,0.0) [0.0|1] ""  Airbag,ICAS1_Gateway,LE2
 SG_ MO_Drehzahl_01 : 48|16@1+ (0.25,0) [0.00|16383.00] "Unit_MinutInver"  ICAS1_Gateway

CM_ BO_ 2527679583 "ehemals ZFAS_01";
CM_ BO_ 2621505536 "VWAG Diagnose funktionaler Request auf CANFD";
CM_ BO_ 960 "MQB";
CM_ BO_ 949 "ab MQB 7.4";
CM_ BO_ 1505 "ab MQB 7.3";
CM_ BO_ 982 "MQB";
CM_ BO_ 134 "ab MQB mit CRC in Byte 1";
CM_ BO_ 1600 "ab MQB mit QBit Höheneinfo und MO_Versionsinfo_02";
CM_ BO_ 168 "Teil 2 neue Momentenschnittstelle MLB";

CM_ SG_ 1452 HVEM_Energie_Klima_Vorgabe "HVEM-Energievorgabe für Klima-Vorkonditionierung";
CM_ SG_ 1452 HVEM_Energie_Klima_Vorgabe_HighR "Erweiterte Auflösung von 10Wh für Signal HVEM_Energie_Klima_Vorgabe.
Signalwert wird zu HVEM_Energie_Klima_Vorgabe Addiert";
CM_ SG_ 1452 HVEM_HV_Anf "HV Anforderung des HV Energiemanagements an das MSG";
CM_ SG_ 1452 HVEM_HVK_Aktivitaet "Dem HVEM sind HV-Komponenten zugeordnet.  Das HVEM übermittelt an den HVK ein 
Hochvolt –Aktivitätsstatus dieser HV-Komponenten.";
CM_ SG_ 1452 HVEM_IstLeistungNA "aktuelle Leistungsaufnahme der Nebenaggregate";
CM_ SG_ 1452 HVEM_IstStrom_HVVerbraucher "Iststromaufnahme der elektrischen Nebenaggregate aus dem HV Zwischenkreis";
CM_ SG_ 1452 HVEM_Leistung_Klima_Vorgabe "Leistungsvorgabe Thermo (für Kühlen und Heizen)";
CM_ SG_ 1452 HVEM_MO_MaxLeistungIgnoriert "Rueckmeldung des HVEM ob die vorgegebene MaxLeistung vom MSG eingehalten wird.";
CM_ SG_ 1452 HVEM_Nutzbare_Energie "Nutzbare Energie welche für Komfortfunktionen vom HVEM freigegeben wird.";
CM_ SG_ 1452 HVEM_Pruefpuls_Anf "Prüfpulsanforderung an den HV-Koordinator";

CM_ SG_ 1385 HVEM_Abschaltstatus "Status der Reduzierungsstufen der Klimakomponenten beim Laden

0 = 100% (keine Reduzierung)
1 = 75%
2 = 50%
3 = 25%
7 = Init";
CM_ SG_ 1385 HVEM_Anf_ReichweiteNV "Anforderung an NV-EM zur Erhöhung der Reichweite den Energieverbrauch auf der NV-Seite zu reduzieren.";
CM_ SG_ 1385 HVEM_DCDC_Freigabe "Freigabe des DCDC wenn das Fzg nicht Fahrbereit ist.";
CM_ SG_ 1385 HVEM_FreigabeKlimatisierung "Klimatisierung freigeben";
CM_ SG_ 1385 HVEM_HV_Anf "HV Anforderung des HV Energiemanagements an das MSG";
CM_ SG_ 1385 HVEM_KlimaMaxHVStrom "Kommuniziert dem Klimasteuergerät den max. Aufnahmestrom";
CM_ SG_ 1385 HVEM_LadeklappenVerr_Anf "Anforderung eines Ver- oder Entriegelns der Ladedosenklappe über die ZV.";
CM_ SG_ 1385 HVEM_Ladesteckerentr_Anf "Anforderung Ladestecker entriegeln nach ZV Auf Befehl";
CM_ SG_ 1385 HVEM_Leistung_Bat_Kond_Vorgabe "elektr. Leistungsvorgabe Thermo Batterie";
CM_ SG_ 1385 HVEM_LeistungsAnf "Anforderung an NV-EM zur Erhöhung der Performance den Energieverbrauch auf der NV-Seite zu reduzieren.";
CM_ SG_ 1385 HVEM_Max_VK_Betriebsdauer "Betriebslaufzeit der Standklimatisierung";
CM_ SG_ 1385 HVEM_Nachlad_Status "Status der Umsetzung der Nachladeanforderung der NV-Seite.";
CM_ SG_ 1385 HVEM_Nachladen_Anf "Anforderung für HV Laden bei gestecktem Stecker und deaktivierter Ladeanforderung";
CM_ SG_ 1385 HVEM_NVLeistungEmpf "Maximaler Sollwert der aktuellen Leistung der NV-Seite des DCDC-Wandlers.";
CM_ SG_ 1385 HVEM_Text_1 "Meldung bei einem Anzeige SOC<10% ('Achtung Batterie laden. Funktionen eingeschränkt')";

CM_ SG_ 1283 HV_Bordnetz_aktiv "Signalisiert ein aktives Hochvoltbordnetz. Für die Belastbarkeit des HV-Netzes müssen Strom- bzw. Leistungsgrenzen eingehalten werden";
CM_ SG_ 1283 HV_Bordnetz_Fehler "Status ob im  HV-Netz ein Fehler detektiert wurde.";
CM_ SG_ 1283 HVK_01_CRC "Für MLB:
'Berechnung siehe Lastenheft 'Kommunikationsabsicherung für FlexRay und CAN''

Ab MQB und MLBevo:
'Berechnung siehe Lastenheft 'End-to-End Kommunikationsabsicherung''

Endwerte siehe Begleitdokument 'S-PDU Kennungsfolgen'";
CM_ SG_ 1283 HVK_AktiveEntladung_Anf "Anforderung zum aktiven Entladen des HV-Netzes, während der Abschaltung des HV-Netz.";
CM_ SG_ 1283 HVK_BMS_Sollmodus "Angeforderter Sollmodus der HV-Batterie:
0 : HV_Off                                
1 : HV_On (HS geschlossen)                
2 : nicht belegbar                        
3 : AC-Laden_erw (HS +AC_2-Schütze geschlossen)                         
4 : AC-";
CM_ SG_ 1283 HVK_DCDC_Sollmodus "angeforderte Soll-Betriebsart des DC/DC-Wandlers: 
0: Standby; Kommunikation aktiv
1: Zwischenkreis des HV-Netzes wird vorgeladen; HV-Netz wird aktiviert und darf nicht  
    belastet werden.
2: Tiefsetzen (HV --> BN 14,4V)
    Sollwertvorgabe projek";
CM_ SG_ 1283 HVK_EKK_Sollmodus "Sollmodus elektrischer Klimakompressor";
CM_ SG_ 1283 HVK_Gesamtst_Spgfreiheit "Status des HV-Systems";
CM_ SG_ 1283 HVK_HV_Netz_Warnungen "Anforderung Warnung/Fehler HV-System im Kombi
0: Keine Warnung/Init
1:Anforderung_Anzeige_Warnung_HV-Netz (gelbes Symbol)
2:Anforderung_Anzeige_Fehler_HV-Netz (rotes Symbol)
3:Anforderung_Anzeige_Warnung_Kein_Wiederstart_möglich";
CM_ SG_ 1283 HVK_HVEM_Freigabe "Der HVK gibt das HVEM frei, um das HV-Netz unter Einhaltung von Leistungsgrenzen in Anspruch zu nehmen.";
CM_ SG_ 1283 HVK_HVLM_Sollmodus "Angeforderter Sollmodus des Lademanagers.";
CM_ SG_ 1283 HVK_HVPTC_Sollmodus "Sollmodus HV-PTC
0 : keine Freigabe
1 : Freigabe
2 : Freigabe_ausgesetzt
3 : nicht belegbar
4 : nicht belegbar
5 : nicht belegbar
6 : nicht belegbar
7 : Init   (CAN-Initialisierung)   

Info: 'nicht belegbar' d.h. Sollmodus nicht relevant für HV";
CM_ SG_ 1283 HVK_Iso_Messung_Start "Anforderung an die isolationswiderstandsüberwachenden HV-Komponenten zur Durchführung der Isolations-Widerstandsmessung.";
CM_ SG_ 1283 HVK_Istmodus_Anf "HVK-Anforderung an alle HV-Komponenten deren Istmodus im schnellen Zyklus (Inhibitzeit) zu senden.";
CM_ SG_ 1283 HVK_Ladebereit "Information an das Lademanagement, dass das HV-System aus Sicht des HVKs bereitgestellt werden kann.";
CM_ SG_ 1283 HVK_Notentladung_Anf "Aufforderung zur schnellstmöglichen Entladung des HV-Netzes aufgrund HV-Sicherheit (Crash-Erkennung / Abriss Pilotlinie / …).";
CM_ SG_ 1283 HVK_PPulsFreigabe "Prüfpuls-Freigabe seitens Hochvoltkoordinator";
CM_ SG_ 1283 HVK_TN1_Sollmodus "Angeforderter Sollmodus der Steuereinheit für das Schütze des Teilnetz1 'Ladepfad':
0 : HV_Off                                
1 : HV_On (Schütz geschlossen)                
2 : reserviert
3 : Init   (CAN-Initialisierung)";
CM_ SG_ 1283 HVK_Vorladung_aktiv "Systeminformation, dass aktiv vorgeladen wird";

CM_ SG_ 2463978813 HVL_01_BZ "4bit Botschaftszähler, wird mit jeder Sendebotschaft inkrementiert";
CM_ SG_ 2463978813 HVL_01_CRC "Für MLB:
Berechnung siehe Lastenheft 'Kommunikationsabsicherung für FlexRay und CAN'
Ab MQB und MLBevo:
Berechnung siehe Lastenheft 'End-to-End Kommunikationsabsicherung'

Endwerte siehe Begleitdokument 'S-PDU Kennungsfolgen'";
CM_ SG_ 2463978813 HVL_LadeAnforderung "FuSi-Abgesicherte Ladeanforderung an den HVK";
CM_ SG_ 2463978813 HVL_Steckerstatus "Stellt den Status des Ladesteckers hinsichtlich Präsenz zur Verfügung";

CM_ SG_ 626 HVLM_Anforderung_HMS "Anforderung zur Verriegelung des Triebstrangs";
CM_ SG_ 626 HVLM_AWC_VerbautStatus "Verbausignalisierung vom HVLM der optionalen Komponente AWC";
CM_ SG_ 626 HVLM_DC_Aufstartmodus "Aufstartmodus zum Aktivieren des HV-Modus für DC-Laden
0= keine_Anforderung
1= Angleich_Fahrzeug (Fahrzeug schaltet auf DC-Spannung der Ladesäule auf)
2= Angleich_LS_1 (Ladesäule schaltet auf DC-Spannung des Fahrzeuges auf Methode 1)
3= Angleich_LS_2 ";
CM_ SG_ 626 HVLM_Intensitaet "Über dieses Signal wird eine Information über die Beleuchtungsintensität gesendet.";
CM_ SG_ 626 HVLM_Laden_ISO_Messung_Anf "Messung des Isolationswiderstandes des Ladesystems (Fzg und Ladesäule) während des Ladevorganges durch das Fahrzeug
0= Anforderung
1= keine_Anforderung";
CM_ SG_ 626 HVLM_Ladeszenario "Über dieses Signal wird das einzustellende Szenario für die Visualisierung gesendet.";
CM_ SG_ 626 HVLM_Ladevorgang_Anf "Art der angeforderten Ladeart 
0 = Laden_nicht_angefordert
1 = AC_Laden_Angefordert
2 = DC_Laden_Angefordert
3 = AC_und_DC_Angefordert
4 = Induktiv_Laden_Angef
5 = AC_und_Induktiv_Angef
6 = DC_und_Induktiv_Angef
7 = AC_DC_und_Induktiv_Angef";
CM_ SG_ 626 HVLM_Parken_beibehalten_HMS "Anforderung den Triebstrang verriegelt zu halten";
CM_ SG_ 626 HVLM_Start_Pulserkennung "Startanforderung für die Pulserkennung";
CM_ SG_ 626 HVLM_Steckerstatus_A "Gibt den Steckerstatus aus der Ladedose A an";
CM_ SG_ 626 HVLM_Steckerstatus_B "Gibt den Steckerstatus aus der Ladedose B an";
CM_ SG_ 626 HVLM_WakeUpZaehlerResetAnf "0 = keine_Anforderung
1 = Reset_Zaehler";
CM_ SG_ 626 HVLM_ZustandLadeablauf "Zustand im Ablauf des Ladevorganges
0 = Init
1 = Standby_Ladevorbedingungen erfuellt
2 = Standby_Ladevorbedingungen_nicht_erfuellt
3 = Fehler
4 = Laden_starten
5 = Laden_beenden
6 = HVBatterie_Laden
7 = HVBatterie_Entladen
8 = Erhaltungsladen";

CM_ SG_ 268 ImoCord_Auth_Aufforderung_WFS "WFS-Anforderung";

CM_ SG_ 2527679583 IPA_Anf_Meldungen "Anforderung der Meldungen:
0 - Keine Meldung
1-127 IPA niederprio. Meldungen
128-191 IPA hochprio. Meldungen
192-207 TPA Meldungen
208-255 Vorhalt";
CM_ SG_ 2527679583 Parken_aktives_System_02 "zeigt an welches parkendes System aktiv ist";
CM_ SG_ 2527679583 Parken_Aktivierungslicht_Anf "Anforderung des Aktivierungslichts nach erfolgreicher Aktivierungshandlung seitens Pilotiertem Parken.";
CM_ SG_ 2527679583 Parken_Bestaetigungsblinken_Anf "Anforderung seitens Pilotiertem Parken für ein Erfolgsblinken nach dem Erreichen der Zielposition bzw. für ein Abbruchsblinken bei Eintreten einer Abbruchsbedingung.";
CM_ SG_ 2527679583 Parken_Fahrbereitschaftlicht_Anf "Anforderung des Fahrbereitschaftslichts";
CM_ SG_ 2527679583 Parken_Fahrerhinweise_Anf "Anforderung zur erneuten Lampenaufprüfung und Anzeige von Warnhinweisen nach einem pilotierten Ausparkvorgang.";
CM_ SG_ 2527679583 Parken_Fahrtrichtungslicht_Anf "Anforderung seitens Pilotiertem Parken für die Anzeige der initialen Fahrtrichtung nach Systemaktivierung.";
CM_ SG_ 2527679583 Parken_FFB_LED_Anf "Statusinformation des Pilotierten Parkens für die Ansteuerung der LED auf der Funkfernbedienung.";
CM_ SG_ 2527679583 Parken_Lichtnachlauf_Anf "Anforderung des Lichtnachlaufs beim BCM1 (analog Verlassenskonzept) für das Pilotierte Parken. ";
CM_ SG_ 2527679583 Parken_Lichtsteuerung_Anf "Anforderung zum Setzen des Lichtmodus des Fahrzeuges von der Parkfunktion";
CM_ SG_ 2527679583 Parken_Schluesselsuche_Anf "Ansteuerung der Schlüsselsuche für das pilotierte Parken.";
CM_ SG_ 2527679583 Parken_Seitenspiegel_Anf "Anforderung für Seitenspiegel an- oder abklappen beim PiloPa";
CM_ SG_ 2527679583 Parken_Wegfahrsperren_Anf "Ansteuerung der Wegfahrsperren Komponenten für das pilotierte Parken.  ";
CM_ SG_ 2527679583 Parken_ZR_Sondermodus_Anf "Anforderung Sondermodus, um beim „pilotierten Parken“ spezielle Funktionsanpassungen im Infotainment-Bereich zu ermöglichen (u.a. schnellerer Startup, Abschaltung BT)";
CM_ SG_ 2527679583 Parken_ZV_Schliessen "Anforderung für Zentralverriegelung verriegeln oder safen beim PiloPa";

CM_ SG_ 1813 ISO_Airbag_01_Req_Data "Diagnose Request Airbagsteuergeraet";

CM_ SG_ 1919 ISO_Airbag_01_Resp_Data "Diagnose Response Airbagsteuergeraet";

CM_ SG_ 1792 ISO_ALL_01_Req_Data "Funktionaler Request ALL";

CM_ SG_ 2621440021 ISOx_Airbag_01_Req_FD_Data "Diagnose Request";

CM_ SG_ 2621571093 ISOx_Airbag_01_Resp_FD_Data "Diagnose Response";

CM_ SG_ 2549874812 ISO_EMotor_01_Req_Data "Diagnose Request Leistungselektronik E-Maschine 1";

CM_ SG_ 2621440124 ISOx_EMotor_01_Req_FD_Data "Diagnose Request";

CM_ SG_ 2550005884 ISO_EMotor_01_Resp_Data "Diagnose Response Leistungselektronik E-Maschine 1";

CM_ SG_ 2621571196 ISOx_EMotor_01_Resp_FD_Data "Diagnose Response";

CM_ SG_ 2549874872 ISO_EMotor_02_Req_Data "Diagnose Request Leistungselektronik E-Maschine 2";

CM_ SG_ 2621440184 ISOx_EMotor_02_Req_FD_Data "Diagnose Request";

CM_ SG_ 2550005944 ISO_EMotor_02_Resp_Data "Diagnose Response Leistungselektronik E-Maschine 2";

CM_ SG_ 2621571256 ISOx_EMotor_02_Resp_FD_Data "Diagnose Response";

CM_ SG_ 2621505536 ISOx_Funkt_Req_All_FD_Data "VWAG Diagnose funktionaler Request auf CANFD";

CM_ SG_ 2549874806 ISOx_MO_01_Req_Data "Diagnose Request";

CM_ SG_ 2621440118 ISOx_MO_01_Req_FD_Data "Diagnose Request";

CM_ SG_ 2550005878 ISOx_MO_01_Resp_Data "Diagnose Response";

CM_ SG_ 2621571190 ISOx_MO_01_Resp_FD_Data "Diagnose Response";

CM_ SG_ 2527679684 Kamera_ASM_Data_1 "Dieses Signal wird von der Frontkamera befüllt und an den Assistenzsystemmonitor ASM gesendet.";
CM_ SG_ 2527679684 Kamera_ASM_Data_2 "Dieses Signal wird von der Frontkamera befüllt und an den Assistenzsystemmonitor ASM gesendet.";
CM_ SG_ 2527679684 Kamera_ASM_Data_3 "Dieses Signal wird von der Frontkamera befüllt und an den Assistenzsystemmonitor ASM gesendet.";
CM_ SG_ 2527679684 Kamera_ASM_Data_4 "Dieses Signal wird von der Frontkamera befüllt und an den Assistenzsystemmonitor ASM gesendet.";
CM_ SG_ 2527679684 Kamera_ASM_Data_5 "Dieses Signal wird von der Frontkamera befüllt und an den Assistenzsystemmonitor ASM gesendet.";
CM_ SG_ 2527679684 Kamera_ASM_Data_6 "Dieses Signal wird von der Frontkamera befüllt und an den Assistenzsystemmonitor ASM gesendet.";
CM_ SG_ 2527679684 Kamera_ASM_Ereignis "Dieses Signal definiert, welche Funktion und welche Art von Aktivität das Senden der Botschaft an den Assistenzsystemmonitor ASM veranlasst hat.";
CM_ SG_ 2527679684 Kamera_ASM_Zeitstempel "Dieses Signal ermöglicht die zeitliche Zuordnung der von ACC an den Assistenzsystemmonitor ASM gesendeten Statusbotschaften.";

CM_ SG_ 960 BCM_Ausparken_Betrieb "Anforderung zur erneuten Lampenaufprüfung und Anzeige von Warnhinweisen nach einem pilotierten Ausparkvorgang (Trigger: fallende Flanke)";
CM_ SG_ 960 BCM_Remotestart_Betrieb "Zeigt den Status des RemoteStarts an, d.h. KL15_RSt ist aktiviert und der Motorlauf ist im RSt-Betrieb aktiv.";
CM_ SG_ 960 BCM_Remotestart_KL15_Anf "Zeigt den Status der Aktivierung der KL15_RST durch das BCM an.";
CM_ SG_ 960 BCM_Remotestart_MO_Start "Nachdem das BCM die Remotestart MSG Freigabe sicher erkannt hat, fordert das BCM wiederum über dieses Signal vom MSG einen Motorstart durchzuführen.";
CM_ SG_ 960 Klemmen_Status_01_BZ "4bit Botschaftszaehler; wird in jeder Sendebotschaft inkrementiert";
CM_ SG_ 960 Klemmen_Status_01_CRC "Für MLB:
'Berechnung siehe Lastenheft 'Kommunikationsabsicherung für FlexRay und CAN''

Ab MQB und MLBevo:
'Berechnung siehe Lastenheft 'End-to-End Kommunikationsabsicherung''

Endwerte siehe Begleitdokument 'S-PDU Kennungsfolgen'";
CM_ SG_ 960 KST_Fahrerhinweis_1 "Signalisierung Fahrerhinweis 1 der Klemmensteuerung an das Kombi";
CM_ SG_ 960 KST_Fahrerhinweis_2 "Signalisierung Fahrerhinweis 2 der Klemmensteuerung an das Kombi";
CM_ SG_ 960 KST_Fahrerhinweis_4 "Signalisierung Fahrerhinweis 4 der Klemmensteuerung an das Kombi";
CM_ SG_ 960 KST_Fahrerhinweis_5 "Anzeigesignal für RemoteStart";
CM_ SG_ 960 KST_Fahrerhinweis_6 "Signal aktiviert die Kombi-Anzeigeinstrumente (Drehzahl, Tankinhalt, Kühlmitteltemperatur) während aktiviertem RemoteStart-Betrieb";
CM_ SG_ 960 KST_Warn_P1_ZST_def "Kombi Prio Warnung Klemmensteuerung 
Zündschloß defekt, Service aufsuchen!";
CM_ SG_ 960 KST_Warn_P2_ZST_def "Kombi Prio Warnung Klemmensteuerung
Zündschloß defekt!
";
CM_ SG_ 960 RSt_Fahrerhinweise "Über das Signal fordert das BCM Fahrerhinweise im Kombi für die Funktion RemoteStart an.";
CM_ SG_ 960 ZAS_Kl_15 "Klemme 15: Zuendung (SW-Kl.15)
";
CM_ SG_ 960 ZAS_Kl_50_Startanforderung "Klemme 50: Startwunsch Fahrer
";
CM_ SG_ 960 ZAS_Kl_Infotainment "Separate Klemmeninformation für das Infotainment. Signal entspricht im wesentlichen einer Klemme S Information, kann aber über einen Vor - bzw. Nachlauf zu Klemme S verfügen. 
Ein konkreter Anwendungsfall für einen Nachlauf ist die Abschaltung der Klemme";
CM_ SG_ 960 ZAS_Kl_S "Klemme S: S-Kontakt (Schluessel steckt)
";
CM_ SG_ 960 ZAS_Kl_X "Klemme 75
";

CM_ SG_ 2463978753 KST_Sonderzustand_Anforderung "Hiermit wird die aktive bzw. aktuell angeforderte (s. KST_Sonderzustand_Status) Sonderfunktion identifiziert";
CM_ SG_ 2463978753 KST_Sonderzustand_Status "Hiermit wird signalisiert, dass eine Sonderfunktion aktiv ist und die Klemme 15 durch diese angefordert wurde bzw. ein Übergang von Sonderfunktionen stattfindet";
CM_ SG_ 2463978753 KST_WFS_Fahrfreigabe_Anforderung "Hiermit wird den Wegfahrsperren-Teilnehmern signalisiert welche Art der Fahrfreigabe von der anfordernden Sonderfunktion benötigt wird";

CM_ SG_ 1420 Klemmen_Steuerung_01_BZ "4bit Botschaftszaehler; wird in jeder Sendebotschaft inkrementiert";
CM_ SG_ 1420 Klemmen_Steuerung_01_CRC "Ab MQB und MLBevo:
'Berechnung siehe Lastenheft 'End-to-End Kommunikationsabsicherung''

Endwerte siehe Begleitdokument 'S-PDU Kennungsfolgen'";
CM_ SG_ 1420 KST_Anf_Klemme_15 "Anforderung der Klemme 15 an das BCM. Signal wird zur Plausibilisierung parallel zum Klemmensignal auf dem CAN übertragen.";
CM_ SG_ 1420 KST_Anf_Klemme_50 "Anforderung der Klemme 50 an das MSG. Signal wird zur Plausibilisierung parallel zum Klemmensignal auf dem CAN übertragen.";
CM_ SG_ 1420 KST_Anf_Klemme_S "Anforderung der Klemme S an das BCM. Signal wird zur Plausibilisierung parallel zum Klemmensignal auf dem CAN übertragen.";
CM_ SG_ 1420 KST_Anf_Klemmenfreigabe_ELV "Klemmensteuerung fordert Klemmen-Freigabe durch die ELV an.";
CM_ SG_ 1420 KST_Anf_Klemmenfreigabe_WFS "Anforderung der Freigabe von der WFS zum Einschalten von Klemme 15 und Klemme S";
CM_ SG_ 1420 KST_Anf_ZV_Verriegelung "Neuer Verriegelungstrigger für die ZV nach der automatischen Klemmenabschaltung.

Wird bei Kessyfahrzeugen mit StartStop ein aktiver Stop-Mode und Fahrerverlassen erkannt, startet ein 30 Sekunden-Timer. Innerhalb dieser 30 Sekunden hat der Fahrer die Mö";
CM_ SG_ 1420 KST_aut_Abschaltung_Zuendung "Falls bei eingeschalteter Zündung das Abblendlicht aktiv war, muss nach der automatischen Abschaltung der Kl_15 & Kl_S, dass Standlicht aktiv bleiben. Das Signal sendet die Information, dass eine automatische Abschaltung der Kl_15 und Kl_S erfogt.";
CM_ SG_ 1420 KST_Fahrer_Info_Text "Hinweise für den Fahrer für die Fahrzeugaktivierung / -deaktivierung";
CM_ SG_ 1420 KST_Txt_Komfortabschaltung "Dieses Signal fordert im Kombi die Meldung an, die den Fahrer über die ausgeführte automatische Zündungsabschaltung informiert. Signal wird für10s gesendet.";
CM_ SG_ 1420 KST_Txt_P_Gang "Text: 'Wählhebel in Position P bringen!'";
CM_ SG_ 1420 KST_Txt_Panikabschaltung "Text: 'Notabschaltung''";
CM_ SG_ 1420 KST_Txt_Werkstatt "Text: 'Klemmensteuerung! Werkstatt!'";
CM_ SG_ 1420 KST_Unterdr_Zuendungsmeldung "Bei aktivem Signal soll die Zündungsmeldung durch das Kombi unterdrückt werden.";
CM_ SG_ 1420 KST_ZAT_betaetigt "Zündanlass-Taster (ZAT) betätigt";
CM_ SG_ 1420 KST_Zuendungswarnung "Bei aktivem Signal soll je nach gesetztem Status eine Warnung durch das Kombi ausgegeben werden";
CM_ SG_ 1420 Relais_VoKo_angesteuert "Signal zur Rückmeldung, ob das Relais für die Verbraucher von erweiterte Voko / RemoteStart angesteuert wird.";
CM_ SG_ 1420 RSt_Anforderung_HMS "Anforderung vom RSt (Remote Start) an das HMS (Haltemanagement System)";

CM_ SG_ 949 KL_AC_Schalter "AC Schalter
";
CM_ SG_ 949 KL_Anf_KL "Anforderung Kühlerlüfter der Klimaanlage in Prozent

";
CM_ SG_ 949 KL_Anf_KV "Anforderung des Kühlerrollos in %";
CM_ SG_ 949 KL_Ausstattung_Klima "Austtattungsart der Klimabedienung";
CM_ SG_ 949 KL_Charisma_FahrPr "MLBevo: Aktuelles Fahrprogramm des Charisma-Teilnehmers (siehe Systemlastenheft Drive Select)
MQB: Istwert der Kennlinie (siehe Systemlastenheft MQB FPA)";
CM_ SG_ 949 KL_Charisma_Status "Charisma Systemstatus des Charisma-Teilnehmers

Wert 0x3 ist nur für Fahrzeuge ab MQB relevant";
CM_ SG_ 949 KL_Drehz_Anh "Drehzahlanhebung vom Motor angefordert

";
CM_ SG_ 949 KL_el_Zuheizer_Stufe "Vorgabe für Motorsteuergeraet PTC-Stufe; im MLB-B8 und MQB nur Stufe 0...3

";
CM_ SG_ 949 KL_Freilauf_Info "Freilauf Informationssignal von Klima zum Freilaufkoordinator. Klima kann über dieses Signal den Freilauf freigeben, verhindern bzw. explizit anfordern.";
CM_ SG_ 949 KL_Kompressorkupplung_linear "Sollwert zur Ansteuerung der Kompressorkupplung";
CM_ SG_ 949 KL_Last_Kompr "Aktuelles Verlustmoment der Klimaanlage bezogen auf die Kurbelwelle. Wird der Klimakompressor nicht angesteuert, ist das Schleppmoment bezogen auf die Kurbelwelle zu senden.";
CM_ SG_ 949 KL_nachtr_Stopp_Anf "Dieses Signal dient dem Motor als Trigger, dass ein nachträglicher Motorstopp eingeleitet werden kann, wenn es die Bedingungen des StSt Koordinators dies zulassen. ";
CM_ SG_ 949 KL_Spannungs_Anf "Forderung des Klima-SG's zur Spannungsanhebung.";
CM_ SG_ 949 KL_StartStopp_Info "Stopp-Freigabe und Start-Anforderung an den Start-Stopp-Koordinator";
CM_ SG_ 949 KL_T_Charge "Signal für Tastenbetätigung Charge-Taste (SOC Increasing)";
CM_ SG_ 949 KL_Thermomanagement "Stufen des Thermomanagements;
Bei Klemme 15 AUS und erkannten Timeout zum Klimabedienteil (z.B. Klimabedienteil während des Motorsteuergeräte-Kommunikations-Nachlaufs bereits im NM-Zustand ¿Bus Sleep¿)
erfolgt keine Ansteuerung der Wasserpumpe durch die";
CM_ SG_ 949 KL_Variante_Standheizung "Identifikation der Variante der Standheizungen zur Berechnung der energetischen Zielzeit";
CM_ SG_ 949 KL_Vorwarn_Komp_ein "Vorwarnung Kompressor ein; 140ms vorher; Information für Motor zum Aufbau Momentenreserve";
CM_ SG_ 949 KL_Vorwarn_Zuheizer_ein "Vorwarnung Zuheizerbetrieb
";
CM_ SG_ 949 KL_Zustand "Beschreibt den Zustand des Klima-/Heizungsbedienteils. (OFF-Mode Bedienteil)

PAG (MLB): Beschreibt den Zustand des Kompressors";

CM_ SG_ 1511 KL_BattKond_WaPu_DZMax "Maximal-Drehzahl der Wasserpumpe im Batteriekühlkreislauf als Vorgabe für BMS";
CM_ SG_ 1511 KL_EKK_Strom "EKK  Stromaufnahme (Hochvolt)";
CM_ SG_ 1511 KL_Fehler_HV_EKK "Fehlersignal bei Erkennung HV Fehler am elektrischen Klimakompressor EKK
Sender: Klima MQB (evtl. Wärmepumpen SG MQB, OBD SG MQB)";
CM_ SG_ 1511 KL_Fehler_HV_Heizer "Fehlersignal bei Erkennung HV Fehler am HV Heizer
Sender: Klima MQB (evtl. Wärmepumpen SG MQB, OBD SG MQB)";
CM_ SG_ 1511 KL_HV_Heizer_Strom "Strom HV-Heizer für Reichweitenberechnung";
CM_ SG_ 1511 KL_KM_ASV_01_Status "Schaltstatus Kältemittel Absperrventil
VW370/9 PHEV = Ventil vor Verdampfer";
CM_ SG_ 1511 KL_KM_ASV_02_Status "Schaltstatus Kältemittel Absperrventil
VW370/9 PHEV = Ventil vor Chiller";
CM_ SG_ 1511 KL_Pumpe_02_Soll "Anforderung KM-Pumpe Klimakreislauf
Init (126dec)      = 0% Ansteuerung Pumpe
Fehler (127dec) = 100% Ansteuerung Pumpe";
CM_ SG_ 1511 KL_Senderkennung "Gibt an, welches SG (Klima oder WP) die Botschaft sendet";
CM_ SG_ 1511 KL_Status_EoHVL_EKK "Erkennung einer offenen HV-Leitung (EoHVL). Bewertet anhand einer Spannungsgrenze.";
CM_ SG_ 1511 KL_Status_EoHVL_Heizer "Erkennung einer offenen HV-Leitung (EoHVL). Bewertet anhand einer Spannungsgrenze.";
CM_ SG_ 1511 KL_Ventil_03_Soll "Anforderung Batteriebypass-Ventil im Klimakreislauf";
CM_ SG_ 1511 KL_Ventil_10_Status "Status Ventil_Wärmepumpe; 
nicht angesteuert: Motor- und Heizkreislauf getrennt; 
angesteuert: Motor- und Heizkreislauf verbunden.";
CM_ SG_ 1511 KL_Vorwarn_HVHeizer_Leistung "Vorwarnung der Heizerleistung für die Stromregelung. Botschaft: Klima_EV_03, da das Signal entweder vom Klimasteuergerät oder dem Wärmepumpensteuergerät gesendet werden soll.";
CM_ SG_ 1511 WP_KJ_Soll "Anforderung der Kuehlerjalousiestellung durch Waermepumpen SG";
CM_ SG_ 1511 WP_Kuehlerluefter_Anf "Anforderung Kühlerlüfter durch Wärmepumpen SG";

CM_ SG_ 1505 BCM1_Aussen_Temp_ungef "ungefilterter Wert des Aussentemperatursensors
";
CM_ SG_ 1505 BCM1_FStatus_Aussentemp_ungef "Fehlerstatus für Aussentemperatur (Kombianzeige)";
CM_ SG_ 1505 BCM1_Kompressorstrom_ist "IST-Strom vom Klima-Kompressor";
CM_ SG_ 1505 BCM1_OBD_FStatus_ATemp "Fehlerstatus Umgebungstemperatursensor (OBD relevanter Sensor)
";
CM_ SG_ 1505 BCM1_PTC_stufig_Status "Status des BCM1-Heizverbrauchers PTC (stufig)";
CM_ SG_ 1505 BCM_Heizungsabsperrventil_Status "Das Signal beschreibt den Zustand des Heizungsabsperrventils, welches als Portexpander vom BCM1 elektrisch angesteuert wird.";
CM_ SG_ 1505 BCM_Heizungspumpe_Status "Das Signal beschreibt den Zustand der Heizungspumpe, welche als Portexpander vom BCM1 elektrisch angesteuert wird.";
CM_ SG_ 1505 BCM_Kompressorkupplung_Status "Das Signal beschreibt den Zustand der Klimakompressorkupplung, welche als Portexpander vom BCM1 elektrisch angesteuert wird.";

CM_ SG_ 2549088277 AB_KD_Fehler "Bei gesetztem Bit ist mindestens ein Kundendienstfehler eingetragen
";
CM_ SG_ 2549088277 Airbag_01_Abschaltstufe "Funktionseinschränkung aufgrund aktiver Abschaltstufe";
CM_ SG_ 2549088277 Airbag_01_KompSchutz "Funktionseinschränkung aufgrund Komponentenschutz aktiv";
CM_ SG_ 2549088277 Airbag_01_Nachlauftyp "Abgebildet wird die von der Hardware vorgegebene Möglichkeit, die Kommunikation nach Klemme 15 = AUS aufrecht zu erhalten. Es wird ein Init-Wert gesendet.
0 = Kommunikation nur bei KL15=EIN (kein Nachlauf, nicht weckfähig)
1 = Kommunikation nach KL15=AU";
CM_ SG_ 2549088277 Airbag_01_Transport_Mode "Funktionseinschränkung aufgrund aktivem Transport Mode und/oder Transport Schutz";
CM_ SG_ 2549088277 KN_AB_DiagPfad "Kennzeichnung der Diagnosefähigkeit des BusInterfaces eines Steuergerätes (Knoten)
Umfang LAH 80127

Bei Nutzung des Signal explizit pro angebundenem BusInterface zu setzen:
MQB auf A-CAN = 0 (aktiv)
MQB2020 auf A-CAN = 0 (aktiv)
MLBevo auf FlexRay ";
CM_ SG_ 2549088277 NM_Airbag_01_Wakeup "enthält die Weckursache; stehen mehrere Weckursachen parallel an, dann muss der kleinste Wert übertragen werden";

CM_ SG_ 2549088380 EM_HYB_KD_Fehler "Bei gesetztem Bit ist mindestens ein Kundendienstfehler eingetragen";
CM_ SG_ 2549088380 EMotor_01_Abschaltstufe "Funktionseinschränkung aufgrund aktiver Abschaltstufe";
CM_ SG_ 2549088380 EMotor_01_Transport_Mode "Funktionseinschränkung aufgrund aktivem Transport Mode und/oder Transport Schutz";
CM_ SG_ 2549088380 EMotor_KompSchutz "Funktionseinschränkung aufgrund Komponentenschutz aktiv";
CM_ SG_ 2549088380 EMotor_Nachlauftyp "Abgebildet wird die von der Hardware vorgegebene Möglichkeit, die Kommunikation nach Klemme 15 = AUS aufrecht zu erhalten. Es wird ein Init-Wert gesendet.
0 = Kommunikation nur bei KL15=EIN (kein Nachlauf, nicht weckfähig)
1 = Kommunikation nach KL15=AU";
CM_ SG_ 2549088380 KN_EM_HYB_DiagPfad "Kennzeichnung der Diagnosefähigkeit des BusInterfaces eines Steuergerätes (Knoten)
Umfang LAH 80127

Bei Nutzung des Signal explizit pro angebundenem BusInterface zu setzen:
MQB AB auf A-CAN = 0 (aktiv)
MQB2020 auf A-CAN = 0 (aktiv)
MEB auf A-CAN = ";
CM_ SG_ 2549088380 NM_EMotor_01_Wakeup "enthält die Weckursache; stehen mehrere Weckursachen parallel an, dann muss der kleinste Wert übertragen werden";

CM_ SG_ 2549088272 Gateway_Abschaltstufe "Funktionseinschränkung aufgrund aktiver Abschaltstufe";
CM_ SG_ 2549088272 Gateway_KompSchutz "Funktionseinschränkung aufgrund Komponentenschutz aktiv";
CM_ SG_ 2549088272 Gateway_Nachlauftyp "Abgebildet wird die von der Hardware vorgegebene Möglichkeit, die Kommunikation nach Klemme 15 = AUS aufrecht zu erhalten. Es wird ein Init-Wert gesendet.
0 = Kommunikation nur bei KL15=EIN (kein Nachlauf, nicht weckfähig)
1 = Kommunikation nach KL15=AU";
CM_ SG_ 2549088272 Gateway_Transport_Mode "Funktionseinschränkung aufgrund aktivem Transport Mode und/oder Transport Schutz";
CM_ SG_ 2549088272 GW_KD_Fehler "Kundendienstfehlerbit Gateway zur Anzeige eines im Gateway abgelegten Fehlerspeichereintrages.";
CM_ SG_ 2549088272 KN_GW_DiagPfad "Kennzeichnung der Diagnosefähigkeit des BusInterfaces eines Steuergerätes (Knoten)
Umfang LAH 80127

Bei Nutzung des Signal explizit pro angebundenem BusInterface zu setzen:
MQB auf Diag-CAN = 0 (aktiv)
MLBevo auf Diag-CAN = 0 (aktiv)
alle weiteren ";
CM_ SG_ 2549088272 NM_Gateway_Wakeup "enthält die Weckursache; stehen mehrere Weckursachen parallel an, dann muss der kleinste Wert übertragen werden";

CM_ SG_ 2549088440 KN_LE2_DiagPfad "Kennzeichnung der Diagnosefähigkeit des BusInterfaces eines Steuergerätes (Knoten)
Umfang LAH 80127

Bei Nutzung des Signal explizit pro angebundenem BusInterface zu setzen:

MQB2020 auf A-CAN = 0 (aktiv)
MEB auf A-CAN = 0 (aktiv)";
CM_ SG_ 2549088440 LE2_Abschaltstufe "Funktionseinschränkung aufgrund aktiver Abschaltstufe";
CM_ SG_ 2549088440 LE2_KD_Fehler "Status Kundendienst-Fehlerspeicher";
CM_ SG_ 2549088440 LE2_KompSchutz "Funktionseinschränkung aufgrund Komponentenschutz aktiv";
CM_ SG_ 2549088440 LE2_Nachlauftyp "Abgebildet wird die von der Hardware vorgegebene Moeglichkeit, die Kommunikation nach Klemme 15 = AUS aufrecht zu erhalten. Es wird ein Init-Wert gesendet.
0 = Kommunikation nur bei KL15=EIN (kein Nachlauf, nicht weckfähig)
1 = Kommunikation nach KL15=A";
CM_ SG_ 2549088440 LE2_Transport_Mode "Funktionseinschränkung aufgrund aktivem Transport Mode und/oder Transport Schutz
";
CM_ SG_ 2549088440 NM_LE2_Wakeup "enthält die Weckursache; stehen mehrere Weckursachen parallel an, dann muss der kleinste Wert übertragen werden";

CM_ SG_ 2549088374 KN_MO_DiagPfad "Kennzeichnung der Diagnosefähigkeit des BusInterfaces eines Steuergerätes (Knoten)
Umfang LAH 80127

Bei Nutzung des Signal explizit pro angebundenem BusInterface zu setzen:

MLBevo auf FlexRay A-Kanal = 0 (aktiv)
MQB auf A-CAN = 0 (aktiv)
MQB2020 ";
CM_ SG_ 2549088374 KN_Motor_BusKnockOut "Ausgabe des BusKnockout-Status in der Knotenbotschaft";
CM_ SG_ 2549088374 KN_Motor_BusKnockOutTimer "Ausgabe des BusKnockOut-Timer in der Knotenbotschaft";
CM_ SG_ 2549088374 KN_Motor_ECUKnockOut "Ausgabe des ECUKnockout-Status in der Knotenbotschaft";
CM_ SG_ 2549088374 KN_Motor_ECUKnockOutTimer "Ausgabe des ECUKnockOut-Timer in der Knotenbotschaft";
CM_ SG_ 2549088374 MO_01_Abschaltstufe "Funktionseinschränkung aufgrund aktiver Abschaltstufe";
CM_ SG_ 2549088374 MO_01_Transport_Mode "Funktionseinschränkung aufgrund aktivem Transport Mode und/oder Transport Schutz";
CM_ SG_ 2549088374 MO_KD_Fehler "Kundendienstfehlerspeicherbit";
CM_ SG_ 2549088374 Motor_KompSchutz "Funktionseinschränkung aufgrund Komponentenschutz aktiv";
CM_ SG_ 2549088374 Motor_Nachlauftyp "Abgebildet wird die von der Hardware vorgegebene Möglichkeit, die Kommunikation nach Klemme 15 = AUS aufrecht zu erhalten. Es wird ein Init-Wert gesendet.
0 = Kommunikation nur bei KL15=EIN (kein Nachlauf, nicht weckfähig)
1 = Kommunikation nach KL15=AU";
CM_ SG_ 2549088374 NM_MO_01_Wakeup "enthält die Weckursache; stehen mehrere Weckursachen parallel an, dann muss der kleinste Wert übertragen werden";

CM_ SG_ 982 BRL_als_SHL "Zeigt an ob das Bremslicht als Schlusslicht implementiert wird (Variante NAR)";
CM_ SG_ 982 LH_3_Bremsl_def "Fehlerstatus 3. Bremsleuchte
";
CM_ SG_ 982 LH_Aussenlicht_def "Aussenlicht kann nicht mehr korrekt angesteuert werden (EEPROM Codierung kann nicht mehr ausgelesen werden)
";
CM_ SG_ 982 LH_Blinker_HL_akt "Blinker hinten links
";
CM_ SG_ 982 LH_Blinker_HR_akt "Blinker hinten rechts
";
CM_ SG_ 982 LH_Blinker_li_def "Fehlerstatus Blinker hinten links
";
CM_ SG_ 982 LH_Blinker_re_def "Fehlerstatus Blinker hinten rechts
";
CM_ SG_ 982 LH_Brems_Blk_li_def "Konfiguration BRL + BLK links 
";
CM_ SG_ 982 LH_Brems_Blk_re_def "Konfiguration BRL + BLK rechts
";
CM_ SG_ 982 LH_Bremsl_li_def "Fehlerstatus Bremslicht hinten links (Detektion Einzelausfall)
";
CM_ SG_ 982 LH_Bremsl_li_ges_def "Fehlerstatus Bremslicht hinten links (Detektion Totalausfall)
";
CM_ SG_ 982 LH_Bremsl_mi_def "Fehlerstatus Bremslicht mitte oder Gepäckraumklappe  (Detektion Einzelausfall)";
CM_ SG_ 982 LH_Bremsl_re_def "Fehlerstatus Bremslicht hinten rechts  (Detektion Einzelausfall)
";
CM_ SG_ 982 LH_Bremsl_re_ges_def "Fehlerstatus Bremslicht hinten rechts (Detektion Totalausfall)";
CM_ SG_ 982 LH_Bremslicht_H_aktiv "Bremslicht hinten
";
CM_ SG_ 982 LH_Diag_LED_li_def "Heckleuchte links defekt";
CM_ SG_ 982 LH_Diag_LED_re_def "Heckleuchte rechts defekt";
CM_ SG_ 982 LH_Diag_Status_li_def "Außenlicht Diagnose 
Systemstörung links";
CM_ SG_ 982 LH_Diag_Status_re_def "Außenlicht Diagnose Systemstörung rechts ";
CM_ SG_ 982 LH_Kennzl_def "Fehlerstatus Kennzeichenbeleuchtung hinten
";
CM_ SG_ 982 LH_Nebel_li_def "Fehlererkennung Nebelschlusslicht hinten links
";
CM_ SG_ 982 LH_Nebel_mi_def "Fehlererkennung Nebelschlusslicht hinten Mitte


";
CM_ SG_ 982 LH_Nebel_re_def "Fehlererkennung Nebelschlusslicht hinten rechts
";
CM_ SG_ 982 LH_Nebelschluss_aktiv "Nebelschlusslicht
";
CM_ SG_ 982 LH_Parklicht_HL_aktiv "Parklicht hinten links 
";
CM_ SG_ 982 LH_Parklicht_HR_aktiv "Parklicht hinten rechts 
";
CM_ SG_ 982 LH_Rueckf_li_def "Fehlererkennung Rückfahrlicht hinten links
";
CM_ SG_ 982 LH_Rueckf_mi_def "Fehlererkennung Rückfahrlicht Mitte
";
CM_ SG_ 982 LH_Rueckf_re_def "Fehlererkennung Rückfahrlicht hinten rechts
";
CM_ SG_ 982 LH_Rueckfahrlicht_aktiv "Rueckfahrlicht
";
CM_ SG_ 982 LH_Schluss_Brems_li_def "Konfiguration SL+ BRL + PL links und SL+ BRL  links
";
CM_ SG_ 982 LH_Schluss_Brems_mi_def "Fehlerstatus Schluss + Bremslicht mitte defekt (Detektion Einzelausfall)";
CM_ SG_ 982 LH_Schluss_Brems_Nebel_li_def "Signal wird gesetzt, wenn eine Unterbrechung oder  ein Kurzschluss am Lampenausgang für Schluss_Brems_Nebelschlusslicht erkannt wird.";
CM_ SG_ 982 LH_Schluss_Brems_Nebel_re_def "Signal wird gesetzt, wenn eine Unterbrechung oder  ein Kurzschluss am Lampenausgang für Schluss_Brems_Nebelschlusslicht erkannt wird.";
CM_ SG_ 982 LH_Schluss_Brems_re_def "Konfiguration SL+ BRL + PL rechts und SL+ BRL  rechts
";
CM_ SG_ 982 LH_Schluss_Nebel_li_def "Konfiguration SL + NSL links oder SL + NSL + PL links
";
CM_ SG_ 982 LH_Schluss_Nebel_re_def "Konfiguration SL + NSL rechts oder SL + NSL + PL rechts
";
CM_ SG_ 982 LH_Schlusslicht_li_def "Fehlererkennung Schlusslicht hinten links
";
CM_ SG_ 982 LH_Schlusslicht_mi_def "Fehlererkennung Schlusslicht hinten Mitte";
CM_ SG_ 982 LH_Schlusslicht_re_def "Fehlererkennung Schlusslicht hinten rechts
";
CM_ SG_ 982 LH_SL_BRL_BLK_li_def "Konfiguration SL + BRL + BLK links oder SL + BRL + BLK + PL links
";
CM_ SG_ 982 LH_SL_BRL_BLK_re_def "Konfiguration SL + BRL + BLK rechts oder SL + BRL + BLK + PL rechts
";
CM_ SG_ 982 LH_Standlicht_H_aktiv "Standlicht hinten
";
CM_ SG_ 982 LH_Zusatzschlussl_def "mindestens ein Zusatzschlusslicht in der Heckbeleuchtung defekt.";
CM_ SG_ 982 Licht_hinten_01_BZ "überlaufender 4bit Botschaftszaehler; wird in jeder Sendebotschaft inkrementiert";

CM_ SG_ 134 LWI_01_CRC "Für MLB:
'Berechnung siehe Lastenheft 'Kommunikationsabsicherung für FlexRay und CAN''

Ab MQB und MLBevo:
'Berechnung siehe Lastenheft 'End-to-End Kommunikationsabsicherung'

Endwerte siehe Begleitdokument 'S-PDU Kennungsfolgen'";
CM_ SG_ 134 LWI_Lenkradw_Geschw "Wertebereich = +/- 2500 Grad/s
Auflösung = 5 Grad/s

Hinweis: Zusätzlich gestellte Winkel bei Dynamiklenkung beachten !";
CM_ SG_ 134 LWI_Lenkradwinkel "Wertebereich = +/- 800 Grad
Auflösung = 0,1 Grad
ACHTUNG: spezifizierte Interne Auflösung des Sensors beträgt aber nur Schrittweite 0,5 Grad!

Hinweis:
MLB: Zusätzlich gestellte Winkel bei Dynamiklenkung beachten !
MQB: Nicht konstante Lenkübersetzu";
CM_ SG_ 134 LWI_QBit_Lenkradwinkel "Das QBit wird auch bei nicht abgeglichenem Lenkradwinkelsensor gesetzt";
CM_ SG_ 134 LWI_QBit_Sub_Daten "Es gilt die Signalspezifikation laut LAH";
CM_ SG_ 134 LWI_Sub_Daten "Verschlüsseltes Datenpaket vom Sub-Rechner des LWS, Verwendung nur durch SCU und ESP_ADS
Verwendung gemäß 'Sicherheitsanforderungen an Empfängersteuergeräte'

Im MLB gilt die Signalspezifikation: LAH 8K0953B
Im MLBevo gilt die Signalspezifikation LAH.";
CM_ SG_ 134 LWI_VZ_Lenkradw_Geschw "Vorzeichen Lenkradwinkelgeschwindigkeit gemäss DIN70000; 
Nullstellung = +0";
CM_ SG_ 134 LWI_VZ_Lenkradwinkel "Vorzeichen Lenkradwinkel gemäss DIN70000; 
Nullstellung = +0";

CM_ SG_ 817 MFL_ECU_Err "MFL-µC Fehler";
CM_ SG_ 817 MFL_Eventcode_1 "Siehe Q-LAH MFL-Protokoll";
CM_ SG_ 817 MFL_Eventcode_2 "Siehe Q-LAH MFL-Protokoll";
CM_ SG_ 817 MFL_Lokalaktiv "Zeigt an ob das SG nach Klemme15 AUS und nach entsprechender MAX Aktivzeit noch aktiv war";
CM_ SG_ 817 MFL_LR_HZG_Err "Lenkradheizung Fehler";
CM_ SG_ 817 MFL_LR_HZG_Status "Status Lenkradheizung";
CM_ SG_ 817 MFL_M_Taste "Taster für Umschaltung Automatik/manuelles Schalten (Tiptronic)";
CM_ SG_ 817 MFL_Paddle_Verbau "Signalisiert den Zustand des Tipp-Paddle-Verbaus";
CM_ SG_ 817 MFL_Response_Err "siehe LIN2.0-Specification
(Darf nicht über ein Fehlergueltigkeitsbit abgesichtert werden!)";
CM_ SG_ 817 MFL_SatModul_links_Err "Schalter Tastermodul links Fehler";
CM_ SG_ 817 MFL_SatModul_rechts_Err "Schalter Tastermodul rechts Fehler";
CM_ SG_ 817 MFL_Signalhorn "Signalhorn nicht betaetigt/betaetigt";
CM_ SG_ 817 MFL_Signalhorn_Err "Signalhorn Fehler";
CM_ SG_ 817 MFL_Taste_links_Err "MFL_Tastenblock links Fehler";
CM_ SG_ 817 MFL_Taste_rechts_Err "MFL_Tastenblock rechts Fehler";
CM_ SG_ 817 MFL_Tastencode_1 "Beschreibt die Funktion einer fest zugeordneten Taste/Walze auf dem MFL. Bei Betätigung ändert sich der Wert von 0x0 auf den jeweiligen Tastencode.";
CM_ SG_ 817 MFL_Tastencode_2 "Beschreibt die Funktion einer fest zugeordneten Taste/Walze auf dem MFL. Ist MFL_Tastencode_1 wegen Betätigung einer Taste/Walze bereits mit einem Wert ungleich 0x0 belegt, so ändert sich bei Betätigung einer weiteren Taste/Walze der Wert dieses Signals v";
CM_ SG_ 817 MFL_Tip_Down "MFL-Tiptronic Tasten vom MFL für Getriebe
    0x0 = kein Tip_Down
    0x1 = Tip_Down";
CM_ SG_ 817 MFL_Tip_links_Err "Tiptronic links Fehler";
CM_ SG_ 817 MFL_Tip_rechts_Err "Tiptronic rechts Fehler";
CM_ SG_ 817 MFL_Tip_Up "MFL-Tiptronic Tasten vom MFL für Getriebe
    0x0 = kein Tip_Up
    0x1 = Tip_Up";
CM_ SG_ 817 MFL_Toggle "Watchdog Toggle-Bit";
CM_ SG_ 817 MFL_Variante "Markenspezifische Variantennummer des MFL";

CM_ SG_ 15 MO_SOPC "Switch of Path Check der Motorsteuerung

Achtung, reines CAN-Signal!";

CM_ SG_ 1600 MO_Absperrventil_oeffnen "Signal an Klima-SG das Absperrrventil anzusteuern. Ab D4 auch 0x3 Ventil_schließen.

Im MQB wird hier der Soll-Status des Absperrventils ausgegeben.
Achtung: bei z. B. klemmendem Ventil entspricht das Signal nicht dem tatsächlichen Status!";
CM_ SG_ 1600 MO_aktives_Getriebeheizen "Information für Getriebe, ob ein Ventil für Getriebheizen angesteuert werden muss";
CM_ SG_ 1600 MO_Ansaugluft_Temp "In Fahrzeugen ohne Außentemperatur vom Kombi kann aus der Ansauglufttemperatur auf die Außentemperatur geschlossen werden. Beim SDI ist das mit einer gewissen Genauigkeit gegeben. Genutzt wird es vom ASG.";
CM_ SG_ 1600 MO_Getriebe_kuehlen "Anforderung Getriebekühlventilansteuerung";
CM_ SG_ 1600 MO_Heizungspumpenansteuerung "Anforderung Heizungspumpenansteuerung
MQB und Hybrid: Status der Heizungsunterstützungspumpe am MSG
";
CM_ SG_ 1600 MO_Hoeheninfo "Korrekturfaktor Höhe (1 entspricht 1013 mbar)";
CM_ SG_ 1600 MO_HYB_Fehler_HV_Netz "Im HV-Bordnetz ist fehlerbedingt kein generatorischer Betrieb möglich. Das 12V-Bordnetz wird über den DC/DC-Wandler allein aus der Traktionsbatterie gespeist. Um diesen Zustand möglichst lange aufrechterhalten zu können, sollten Komfort-Verbraucher abgesc";
CM_ SG_ 1600 MO_Kennfeldk "Die Kennfeldkühlung ist in diesem Fahrzeug verbaut und hat keinen Systemfehler";
CM_ SG_ 1600 MO_KL15_Abschaltempfehlung "Kessy Abschaltempfehlung nach Verlassen des Fahrzeugs";
CM_ SG_ 1600 MO_Kuehlmittel_Temp "Kuehlmitteltemperatur";
CM_ SG_ 1600 MO_Mom_Traegheit_02 "Massenträgheit (J) der Motors bzw. der Antriebsmaschinen in kgm².

Zur Berücksichtigung des E-Motor in Hybrid-Projekten:
in MLB-Projekten wird nur der J-Wert des Verbrennungsmotors und nicht der J-Wert des E-Motors berücksichtigt.
In MQB/MLBevo-Projek";
CM_ SG_ 1600 MO_Nachlaufzeit_Heizungspumpe "Nachlaufzeit für Heizungspumpe für Turboladerschutz";
CM_ SG_ 1600 MO_Oel_Temp "Realer Meßbereich ca. -40..150 Grad";
CM_ SG_ 1600 MO_QBit_Ansaugluft_Temp "
";
CM_ SG_ 1600 MO_QBit_Hoeheninfo "Qualifizierungsbit der Höheninfo. Gesetzt bei Ersatzwert, Init oder Fehler.";
CM_ SG_ 1600 MO_QBit_Kuehlmittel_Temp "
";
CM_ SG_ 1600 MO_SpannungsAnf "Forderung des Motor-SGs zur Spannungsanhebung";
CM_ SG_ 1600 MO_Versionsinfo_02 "Versioninformation vom Motor zur Steuerung bei inkompatiblen KMatrix-Änderung bzw. Einführung von neuen Funktionen, die in den Empfängern verriegelt werden müssen. Zu jedem Ereignis wird ein fixer Zählerstand zugeordnet, um dem Empfänger die funktionale Ä";

CM_ SG_ 167 MO_erste_Ungenauschwelle "Zusätzliche Ungenauigkeit (zur Grundungenauigkeit). Motormomente ungenau >8% (kleinste Ungenauschwelle)
";
CM_ SG_ 167 MO_Mom_Ist_Summe "Einheitenloser Wert! Faktor in MO_Faktor_Momente_02 in Motor_Code_01 beachten!

Ist-Moment als Summe aus Verbrennungsmotor und E-Motor (bei Hybrid-Konzepten) incl. allen Eingriffen und Korrekturen

In Fahrzeugen mit einer Antriebsachse bzw. mit mechan";
CM_ SG_ 167 MO_Mom_Schub "Einheitenloser Wert! Faktor in MO_Faktor_Momente_02 in Motor_Code_01 beachten!

Moment das sich einstellt, wenn der Fahrer 0% Fahrpedal gibt; bei konventionellen Projekten = alle Verluste (mechanische Reibung und sonstige Verluste) des Verbrennungsmotor";
CM_ SG_ 167 MO_Mom_Soll_gefiltert "Einheitenloser Wert! Faktor in MO_Faktor_Momente_02 in Motor_Code_01 beachten!

MO_Mom_Soll_Roh nach Fahrverhaltensfilter, begrenzt nach oben mit MO_Mom_Begr_dyn, Einrechnung der plausibilisierten Bremsen-Eingriffe; ohne Getriebe-Schalt-Eingriffe, ohne ";
CM_ SG_ 167 MO_Mom_Soll_Roh "Einheitenloser Wert! Faktor in MO_Faktor_Momente_02 in Motor_Code_01 beachten!

Momentenanforderung aus Fahrpedal bzw. von ACC/GRA bzw. aus dem Leerlaufregler (quasistatischer Anteil) bzw. aus Rekuperationsanforderung; keine Begrenzungen, keine Filterun";
CM_ SG_ 167 MO_Mom_Traegheit_Summe "Einheitenloser Wert! Faktor in MO_Faktor_Momente (CAN V6.x) bzw. MO_Faktor_Momente_02 (CAN V7.x) in Motor_Code_01 beachten!

Moment, das zur Beschleunigung der trägen Massen aufgewendet wird bzw. frei wird; Summen aus Anteilen für Verbrennungsmotor und ";
CM_ SG_ 167 MO_QBit_Motormomente "AUDI D4: Zykluszeit: 10ms (siehe Zykluszeit schnell/Cycletime Fast)

Ungenaue Momentenangaben, weil die Momente aus Ersatzwerten berechnet wurden (z.B. HFM ausgefallen). Qualifizierungsbit für die Motormomente.

Achtung:
Reduktion der Zykluszeit Moto";
CM_ SG_ 167 MO_Status_Normalbetrieb_01 "Das Motorsteuergerät sendet das Informationsbit, wenn die Initialisierungsphase des Steuergerätes abgeschlossen ist. Zusätzlich muss die Klemme 15 eingeschalten sein und eine applizierbare Mindestdrehzahlschwelle (Kennlinie in Abh. von der Kühlwassertempe";
CM_ SG_ 167 Motor_11_CRC "Für MLB:
'Berechnung siehe Lastenheft 'Kommunikationsabsicherung für FlexRay und CAN''

Ab MQB und MLBevo:
'Berechnung siehe Lastenheft 'End-to-End Kommunikationsabsicherung''

Endwerte siehe Begleitdokument 'S-PDU Kennungsfolgen'";

CM_ SG_ 168 MO_Drehzahl_01 "Im Fehlerfall wird die Motordrehzahl über die Nockenwellendrehzahl als Ersatzgrösse ausgegeben

Bei Parallelhybrid: Getriebeeingangsdrehzahl (=E-Maschinen Drehzahl)

Hinweis: 
Ehemaliger Fehlerwert 0xFFFF wird senderseitig nicht unterstützt. 
Diesen";
CM_ SG_ 168 MO_Mom_Begr_Fahr "Einheitenloser Wert! Faktor in MO_Faktor_Momente (CAN V6.x) bzw. MO_Faktor_Momente_02 (CAN V7.x und höher) in Motor_Code_01 beachten!

Bei aktueller Drehzahl quasistationär (nach ca. 3…5 s) max. mögliches Getriebeeingangsmoment (Summe aus Verbrennungsmo";
CM_ SG_ 168 MO_Mom_Begr_Schalt "Einheitenloser Wert! Faktor in MO_Faktor_Momente (CAN V6.x) bzw. MO_Faktor_Momente_02 (CAN V7.x/8.x) in Motor_Code_01 beachten!

Bei aktueller Drehzahl kurzfristig (ca. 100..200 ms) für momentenerhöhende Getriebeeingriffe max. zur Verfügung stehendes Ge";
CM_ SG_ 168 MO_Mom_neg_verfuegbar "Einheitenloser Wert! Faktor in MO_Faktor_Momente (CAN V6.x) bzw. MO_Faktor_Momente_02 (CAN V7.x) in Motor_Code_01 beachten!

Bei aktueller Drehzahl im nächsten Task (bei CAN-Übertragung z.B. 10ms) tatsächlich verfügbares negatives Moment (Summe aus Verl";
CM_ SG_ 168 MO_Momentenintegral_02 "100  %  entspricht volle Verfügbarkeit aktuell vorhanden. 0 % entspricht Integral bis Limit gefüllt, erhöhender Eingriff kann aktuell nicht berücksichtigt werden oder aufgrund eines Fehlers nicht verfügbar
";
CM_ SG_ 168 MO_QBit_Drehzahl_01 "AUDI D4: Zykluszeit: 10ms (siehe Zykluszeit schnell/Cycletime Fast)

Achtung:
Reduktion der Zykluszeit Motor_03 auf 10ms geplant.
Projektabhängig soll künftig mit 10ms gesendet werden.
Empfänger die in weiteren Konzern-Projekten eingesetzt werden müs";
CM_ SG_ 168 Motor_12_CRC "Für MLB:
'Berechnung siehe Lastenheft 'Kommunikationsabsicherung für FlexRay und CAN''

Ab MQB und MLBevo:
'Berechnung siehe Lastenheft 'End-to-End Kommunikationsabsicherung'

Endwerte siehe Begleitdokument 'S-PDU Kennungsfolgen'";
BA_DEF_REL_ BU_SG_REL_  "GenSigTimeoutTime" INT 0 65535;
BA_DEF_ BO_  "DiagRequest" ENUM "No", "Yes";
BA_DEF_ BO_  "DiagResponse" ENUM "No", "Yes";
BA_DEF_ BO_  "DiagState" ENUM "No", "Yes";
BA_DEF_ BO_  "GenMsgChkConstant" HEX 0 4095;
BA_DEF_ BO_  "GenMsgCycleTime" INT 0 65535;
BA_DEF_ BO_  "GenMsgCycleTimeFast" INT 0 65535;
BA_DEF_ BO_  "GenMsgDelayTime" INT 0 100000;
BA_DEF_ BO_  "GenMsgILSupport" ENUM "No", "Yes";
BA_DEF_ BO_  "GenMsgNrOfRepetition" INT 0 100;
BA_DEF_ BO_  "GenMsgPDUConstants" STRING;
BA_DEF_ BO_  "GenMsgSendType" ENUM "Cyclic", "not_used", "not_used", "not_used", "not_used", "not_used", "not_used", "IfActive", "NoMsgSendType";
BA_DEF_ BO_  "GenMsgStartDelayTime" INT 0 100000;
BA_DEF_ BO_  "NmMessage" ENUM "No", "Yes";
BA_DEF_ BO_  "NmhMessage" ENUM "No", "Yes";
BA_DEF_ BO_  "MsgType" ENUM "Application", "NM ", "NMH", "TP2.0", "ISO-TP ", "BAP", "EID", "KS";
BA_DEF_ BO_  "VAGTP20_API" HEX 0 255;
BA_DEF_ BO_  "VAGTP20_DynConnection" ENUM "No", "Yes";
BA_DEF_ BO_  "VAGTP20_DynSetup" ENUM "No", "Yes";
BA_DEF_ BO_  "VAGTP20_StatConnection" ENUM "No", "Yes";
BA_DEF_ BO_  "CANFD_BRS" ENUM "0", "1";
BA_DEF_ BO_  "VFrameFormat" ENUM "StandardCAN", "ExtendedCAN", "reserved", "reserved", "reserved", "reserved", "reserved", "reserved", "reserved", "reserved", "reserved", "reserved", "reserved", "reserved", "StandardCAN_FD", "ExtendedCAN_FD";
BA_DEF_ SG_  "GenSigActiveRepetitions" INT -2147483648 2147483647;
BA_DEF_ SG_  "GenSigInactiveValue" INT -2147483648 2147483647;
BA_DEF_ SG_  "GenSigSendType" ENUM "Cyclic", "OnWrite", "OnWriteWithRepetition", "OnChange", "OnChangeWithRepetition", "IfActive", "IfActiveWithRepetition", "NoSigSendType", "OnChangeAndIfActive", "OnChangeAndIfActiveWithRepetition";
BA_DEF_ SG_  "GenSigStartValue" INT -2147483648 2147483647;
BA_DEF_ SG_  "NWM-WakeupAllowed" ENUM "No", "Yes";
BA_DEF_ SG_  "GenSigFuncType" ENUM "NoFunction", "MsgCounter", "CRC-8", "XOR", "XOR-2", "DatedBit", "SW-Kl15", "CHK", "Constant", "Protocol", "CRC-8-SAE_J1850";
BA_DEF_ SG_  "GenSigSwitchedByIgnition" ENUM "No", "Yes";
BA_DEF_ SG_  "Fehlerwert" HEX 0 2147483647;
BA_DEF_ SG_  "GenSigMissingSourceValue" HEX 0 2147483647;
BA_DEF_DEF_REL_  "GenSigTimeoutTime" 0;
BA_DEF_DEF_  "DiagRequest" "No";
BA_DEF_DEF_  "DiagResponse" "No";
BA_DEF_DEF_  "DiagState" "No";
BA_DEF_DEF_  "GenMsgChkConstant" 0;
BA_DEF_DEF_  "GenMsgCycleTime" 0;
BA_DEF_DEF_  "GenMsgCycleTimeFast" 0;
BA_DEF_DEF_  "GenMsgDelayTime" 0;
BA_DEF_DEF_  "GenMsgILSupport" "No";
BA_DEF_DEF_  "GenMsgNrOfRepetition" 0;
BA_DEF_DEF_  "GenMsgPDUConstants" "";
BA_DEF_DEF_  "GenMsgSendType" "NoMsgSendType";
BA_DEF_DEF_  "GenMsgStartDelayTime" 0;
BA_DEF_DEF_  "NmMessage" "No";
BA_DEF_DEF_  "NmhMessage" "No";
BA_DEF_DEF_  "MsgType" "Application";
BA_DEF_DEF_  "VAGTP20_API" 0;
BA_DEF_DEF_  "VAGTP20_DynConnection" "No";
BA_DEF_DEF_  "VAGTP20_DynSetup" "No";
BA_DEF_DEF_  "VAGTP20_StatConnection" "No";
BA_DEF_DEF_  "CANFD_BRS" "1";
BA_DEF_DEF_  "VFrameFormat" "StandardCAN";
BA_DEF_DEF_  "GenSigActiveRepetitions" 0;
BA_DEF_DEF_  "GenSigInactiveValue" 0;
BA_DEF_DEF_  "GenSigSendType" "NoSigSendType";
BA_DEF_DEF_  "GenSigStartValue" 0;
BA_DEF_DEF_  "NWM-WakeupAllowed" "No";
BA_DEF_DEF_  "GenSigFuncType" "NoFunction";
BA_DEF_DEF_  "GenSigSwitchedByIgnition" "Yes";
BA_DEF_DEF_  "Fehlerwert" 0;
BA_DEF_DEF_  "GenSigMissingSourceValue" 0;
BA_ "GenMsgCycleTime" BO_ 1452 100;
BA_ "GenMsgILSupport" BO_ 1452 1;
BA_ "GenMsgSendType" BO_ 1452 0;
BA_ "VFrameFormat" BO_ 1452 14;
BA_ "GenMsgCycleTime" BO_ 1385 500;
BA_ "GenMsgDelayTime" BO_ 1385 50;
BA_ "GenMsgILSupport" BO_ 1385 1;
BA_ "GenMsgSendType" BO_ 1385 0;
BA_ "VFrameFormat" BO_ 1385 14;
BA_ "GenMsgCycleTime" BO_ 1283 100;
BA_ "GenMsgDelayTime" BO_ 1283 10;
BA_ "GenMsgILSupport" BO_ 1283 1;
BA_ "GenMsgPDUConstants" BO_ 1283 "0xed,0xd6,0x96,0x63,0xa5,0x12,0xd5,0x9a,0x1e,0x0d,0x24,0xcd,0x8c,0xa6,0x2f,0x41";
BA_ "GenMsgSendType" BO_ 1283 0;
BA_ "VFrameFormat" BO_ 1283 14;
BA_ "GenMsgCycleTime" BO_ 2463978813 100;
BA_ "GenMsgDelayTime" BO_ 2463978813 10;
BA_ "GenMsgILSupport" BO_ 2463978813 1;
BA_ "GenMsgPDUConstants" BO_ 2463978813 "0x1d,0x82,0x7b,0x79,0xa5,0xee,0x3a,0xb9,0xb7,0xf9,0xe4,0x67,0x7f,0x97,0x11,0xad";
BA_ "GenMsgSendType" BO_ 2463978813 0;
BA_ "VFrameFormat" BO_ 2463978813 15;
BA_ "GenMsgCycleTime" BO_ 626 100;
BA_ "GenMsgDelayTime" BO_ 626 10;
BA_ "GenMsgILSupport" BO_ 626 1;
BA_ "GenMsgSendType" BO_ 626 0;
BA_ "VFrameFormat" BO_ 626 14;
BA_ "GenMsgILSupport" BO_ 268 1;
BA_ "VFrameFormat" BO_ 268 14;
BA_ "GenMsgILSupport" BO_ 23 1;
BA_ "VFrameFormat" BO_ 23 14;
BA_ "GenMsgILSupport" BO_ 25 1;
BA_ "VFrameFormat" BO_ 25 14;
BA_ "GenMsgCycleTime" BO_ 2527679583 1000;
BA_ "GenMsgCycleTimeFast" BO_ 2527679583 100;
BA_ "GenMsgDelayTime" BO_ 2527679583 50;
BA_ "GenMsgILSupport" BO_ 2527679583 1;
BA_ "GenMsgNrOfRepetition" BO_ 2527679583 5;
BA_ "GenMsgSendType" BO_ 2527679583 0;
BA_ "VFrameFormat" BO_ 2527679583 15;
BA_ "DiagRequest" BO_ 1813 1;
BA_ "MsgType" BO_ 1813 4;
BA_ "VFrameFormat" BO_ 1813 14;
BA_ "DiagResponse" BO_ 1919 1;
BA_ "MsgType" BO_ 1919 4;
BA_ "VFrameFormat" BO_ 1919 14;
BA_ "DiagState" BO_ 1792 1;
BA_ "MsgType" BO_ 1792 4;
BA_ "VFrameFormat" BO_ 1792 14;
BA_ "DiagRequest" BO_ 2621440021 1;
BA_ "MsgType" BO_ 2621440021 4;
BA_ "VFrameFormat" BO_ 2621440021 15;
BA_ "DiagResponse" BO_ 2621571093 1;
BA_ "MsgType" BO_ 2621571093 4;
BA_ "VFrameFormat" BO_ 2621571093 15;
BA_ "DiagRequest" BO_ 2549874812 1;
BA_ "MsgType" BO_ 2549874812 4;
BA_ "VFrameFormat" BO_ 2549874812 15;
BA_ "DiagRequest" BO_ 2621440124 1;
BA_ "MsgType" BO_ 2621440124 4;
BA_ "VFrameFormat" BO_ 2621440124 15;
BA_ "DiagResponse" BO_ 2550005884 1;
BA_ "MsgType" BO_ 2550005884 4;
BA_ "VFrameFormat" BO_ 2550005884 15;
BA_ "DiagResponse" BO_ 2621571196 1;
BA_ "MsgType" BO_ 2621571196 4;
BA_ "VFrameFormat" BO_ 2621571196 15;
BA_ "DiagRequest" BO_ 2549874872 1;
BA_ "MsgType" BO_ 2549874872 4;
BA_ "VFrameFormat" BO_ 2549874872 15;
BA_ "DiagRequest" BO_ 2621440184 1;
BA_ "MsgType" BO_ 2621440184 4;
BA_ "VFrameFormat" BO_ 2621440184 15;
BA_ "DiagResponse" BO_ 2550005944 1;
BA_ "MsgType" BO_ 2550005944 4;
BA_ "VFrameFormat" BO_ 2550005944 15;
BA_ "DiagResponse" BO_ 2621571256 1;
BA_ "MsgType" BO_ 2621571256 4;
BA_ "VFrameFormat" BO_ 2621571256 15;
BA_ "DiagState" BO_ 2621505536 1;
BA_ "MsgType" BO_ 2621505536 4;
BA_ "VFrameFormat" BO_ 2621505536 15;
BA_ "DiagRequest" BO_ 2549874806 1;
BA_ "MsgType" BO_ 2549874806 4;
BA_ "VFrameFormat" BO_ 2549874806 15;
BA_ "DiagRequest" BO_ 2621440118 1;
BA_ "MsgType" BO_ 2621440118 4;
BA_ "VFrameFormat" BO_ 2621440118 15;
BA_ "DiagResponse" BO_ 2550005878 1;
BA_ "MsgType" BO_ 2550005878 4;
BA_ "VFrameFormat" BO_ 2550005878 15;
BA_ "DiagResponse" BO_ 2621571190 1;
BA_ "MsgType" BO_ 2621571190 4;
BA_ "VFrameFormat" BO_ 2621571190 15;
BA_ "GenMsgCycleTime" BO_ 2527679684 2000;
BA_ "GenMsgDelayTime" BO_ 2527679684 100;
BA_ "GenMsgILSupport" BO_ 2527679684 1;
BA_ "GenMsgSendType" BO_ 2527679684 0;
BA_ "VFrameFormat" BO_ 2527679684 15;
BA_ "GenMsgChkConstant" BO_ 960 195;
BA_ "GenMsgCycleTime" BO_ 960 100;
BA_ "GenMsgDelayTime" BO_ 960 10;
BA_ "GenMsgILSupport" BO_ 960 1;
BA_ "GenMsgPDUConstants" BO_ 960 "0xc3,0xc3,0xc3,0xc3,0xc3,0xc3,0xc3,0xc3,0xc3,0xc3,0xc3,0xc3,0xc3,0xc3,0xc3,0xc3";
BA_ "GenMsgSendType" BO_ 960 0;
BA_ "VFrameFormat" BO_ 960 14;
BA_ "GenMsgCycleTime" BO_ 2463978753 1000;
BA_ "GenMsgCycleTimeFast" BO_ 2463978753 100;
BA_ "GenMsgDelayTime" BO_ 2463978753 100;
BA_ "GenMsgILSupport" BO_ 2463978753 1;
BA_ "GenMsgNrOfRepetition" BO_ 2463978753 5;
BA_ "GenMsgSendType" BO_ 2463978753 0;
BA_ "VFrameFormat" BO_ 2463978753 15;
BA_ "GenMsgCycleTime" BO_ 1420 1000;
BA_ "GenMsgCycleTimeFast" BO_ 1420 20;
BA_ "GenMsgDelayTime" BO_ 1420 10;
BA_ "GenMsgILSupport" BO_ 1420 1;
BA_ "GenMsgNrOfRepetition" BO_ 1420 5;
BA_ "GenMsgPDUConstants" BO_ 1420 "0x9b,0xb5,0x9d,0x06,0x01,0xe7,0x8f,0xc1,0xd0,0x10,0x47,0xe9,0xd3,0xca,0x05,0xf0";
BA_ "GenMsgSendType" BO_ 1420 0;
BA_ "VFrameFormat" BO_ 1420 14;
BA_ "GenMsgCycleTime" BO_ 949 100;
BA_ "GenMsgILSupport" BO_ 949 1;
BA_ "GenMsgSendType" BO_ 949 0;
BA_ "VFrameFormat" BO_ 949 14;
BA_ "GenMsgCycleTime" BO_ 1511 200;
BA_ "GenMsgILSupport" BO_ 1511 1;
BA_ "GenMsgSendType" BO_ 1511 0;
BA_ "VFrameFormat" BO_ 1511 14;
BA_ "GenMsgCycleTime" BO_ 1505 200;
BA_ "GenMsgILSupport" BO_ 1505 1;
BA_ "GenMsgSendType" BO_ 1505 0;
BA_ "VFrameFormat" BO_ 1505 14;
BA_ "GenMsgCycleTime" BO_ 2549088277 500;
BA_ "GenMsgILSupport" BO_ 2549088277 1;
BA_ "GenMsgSendType" BO_ 2549088277 0;
BA_ "CANFD_BRS" BO_ 2549088277 0;
BA_ "VFrameFormat" BO_ 2549088277 1;
BA_ "GenMsgCycleTime" BO_ 2549088380 500;
BA_ "GenMsgILSupport" BO_ 2549088380 1;
BA_ "GenMsgSendType" BO_ 2549088380 0;
BA_ "VFrameFormat" BO_ 2549088380 15;
BA_ "GenMsgCycleTime" BO_ 2549088272 500;
BA_ "GenMsgILSupport" BO_ 2549088272 1;
BA_ "GenMsgSendType" BO_ 2549088272 0;
BA_ "VFrameFormat" BO_ 2549088272 15;
BA_ "GenMsgCycleTime" BO_ 2549088440 500;
BA_ "GenMsgILSupport" BO_ 2549088440 1;
BA_ "GenMsgSendType" BO_ 2549088440 0;
BA_ "VFrameFormat" BO_ 2549088440 15;
BA_ "GenMsgCycleTime" BO_ 2549088374 500;
BA_ "GenMsgILSupport" BO_ 2549088374 1;
BA_ "GenMsgSendType" BO_ 2549088374 0;
BA_ "VFrameFormat" BO_ 2549088374 15;
BA_ "MsgType" BO_ 2621440277 4;
BA_ "VFrameFormat" BO_ 2621440277 15;
BA_ "MsgType" BO_ 2621571349 4;
BA_ "VFrameFormat" BO_ 2621571349 15;
BA_ "GenMsgCycleTime" BO_ 982 100;
BA_ "GenMsgDelayTime" BO_ 982 20;
BA_ "GenMsgILSupport" BO_ 982 1;
BA_ "GenMsgSendType" BO_ 982 0;
BA_ "VFrameFormat" BO_ 982 14;
BA_ "GenMsgChkConstant" BO_ 134 134;
BA_ "GenMsgCycleTime" BO_ 134 5;
BA_ "GenMsgILSupport" BO_ 134 1;
BA_ "GenMsgPDUConstants" BO_ 134 "0x86,0x86,0x86,0x86,0x86,0x86,0x86,0x86,0x86,0x86,0x86,0x86,0x86,0x86,0x86,0x86";
BA_ "GenMsgSendType" BO_ 134 0;
BA_ "VFrameFormat" BO_ 134 14;
BA_ "GenMsgCycleTime" BO_ 817 500;
BA_ "GenMsgCycleTimeFast" BO_ 817 30;
BA_ "GenMsgILSupport" BO_ 817 1;
BA_ "GenMsgSendType" BO_ 817 0;
BA_ "VFrameFormat" BO_ 817 14;
BA_ "GenMsgCycleTimeFast" BO_ 15 10;
BA_ "GenMsgILSupport" BO_ 15 1;
BA_ "GenMsgSendType" BO_ 15 7;
BA_ "VFrameFormat" BO_ 15 14;
BA_ "GenMsgCycleTime" BO_ 1600 500;
BA_ "GenMsgILSupport" BO_ 1600 1;
BA_ "GenMsgSendType" BO_ 1600 0;
BA_ "VFrameFormat" BO_ 1600 14;
BA_ "GenMsgCycleTime" BO_ 167 10;
BA_ "GenMsgILSupport" BO_ 167 1;
BA_ "GenMsgPDUConstants" BO_ 167 "0xd2,0x3d,0xcd,0x28,0x4c,0x14,0x22,0x4b,0x24,0xac,0xfa,0x55,0x66,0x80,0x0d,0x6c";
BA_ "GenMsgSendType" BO_ 167 0;
BA_ "VFrameFormat" BO_ 167 14;
BA_ "GenMsgCycleTime" BO_ 168 10;
BA_ "GenMsgILSupport" BO_ 168 1;
BA_ "GenMsgPDUConstants" BO_ 168 "0x52,0x8c,0x50,0xee,0x4f,0xa6,0xcc,0xcf,0x7d,0x2f,0x98,0x6b,0x27,0x41,0x9f,0x93";
BA_ "GenMsgSendType" BO_ 168 0;
BA_ "VFrameFormat" BO_ 168 14;
BA_ "GenSigSendType" SG_ 1452 HVEM_Energie_Klima_Vorgabe 0;
BA_ "GenSigStartValue" SG_ 1452 HVEM_Energie_Klima_Vorgabe 254;
BA_ "GenSigSwitchedByIgnition" SG_ 1452 HVEM_Energie_Klima_Vorgabe 0;
BA_ "Fehlerwert" SG_ 1452 HVEM_Energie_Klima_Vorgabe 255;
BA_ "GenSigSendType" SG_ 1452 HVEM_Energie_Klima_Vorgabe_HighR 0;
BA_ "GenSigStartValue" SG_ 1452 HVEM_Energie_Klima_Vorgabe_HighR 6;
BA_ "GenSigSwitchedByIgnition" SG_ 1452 HVEM_Energie_Klima_Vorgabe_HighR 0;
BA_ "Fehlerwert" SG_ 1452 HVEM_Energie_Klima_Vorgabe_HighR 7;
BA_ "GenSigSendType" SG_ 1452 HVEM_HV_Anf 0;
BA_ "GenSigSwitchedByIgnition" SG_ 1452 HVEM_HV_Anf 0;
BA_ "GenSigSendType" SG_ 1452 HVEM_HVK_Aktivitaet 0;
BA_ "GenSigStartValue" SG_ 1452 HVEM_HVK_Aktivitaet 2;
BA_ "GenSigSwitchedByIgnition" SG_ 1452 HVEM_HVK_Aktivitaet 0;
BA_ "GenSigSendType" SG_ 1452 HVEM_IstLeistungNA 0;
BA_ "GenSigStartValue" SG_ 1452 HVEM_IstLeistungNA 510;
BA_ "GenSigSwitchedByIgnition" SG_ 1452 HVEM_IstLeistungNA 0;
BA_ "Fehlerwert" SG_ 1452 HVEM_IstLeistungNA 511;
BA_ "GenSigSendType" SG_ 1452 HVEM_IstStrom_HVVerbraucher 0;
BA_ "GenSigStartValue" SG_ 1452 HVEM_IstStrom_HVVerbraucher 4094;
BA_ "GenSigSwitchedByIgnition" SG_ 1452 HVEM_IstStrom_HVVerbraucher 0;
BA_ "Fehlerwert" SG_ 1452 HVEM_IstStrom_HVVerbraucher 4095;
BA_ "GenSigSendType" SG_ 1452 HVEM_Leistung_Klima_Vorgabe 0;
BA_ "GenSigStartValue" SG_ 1452 HVEM_Leistung_Klima_Vorgabe 254;
BA_ "GenSigSwitchedByIgnition" SG_ 1452 HVEM_Leistung_Klima_Vorgabe 0;
BA_ "Fehlerwert" SG_ 1452 HVEM_Leistung_Klima_Vorgabe 255;
BA_ "GenSigSendType" SG_ 1452 HVEM_MO_MaxLeistungIgnoriert 0;
BA_ "GenSigSwitchedByIgnition" SG_ 1452 HVEM_MO_MaxLeistungIgnoriert 0;
BA_ "GenSigSendType" SG_ 1452 HVEM_Nutzbare_Energie 0;
BA_ "GenSigStartValue" SG_ 1452 HVEM_Nutzbare_Energie 2046;
BA_ "GenSigSwitchedByIgnition" SG_ 1452 HVEM_Nutzbare_Energie 0;
BA_ "Fehlerwert" SG_ 1452 HVEM_Nutzbare_Energie 2047;
BA_ "GenSigSendType" SG_ 1452 HVEM_Pruefpuls_Anf 0;
BA_ "GenSigStartValue" SG_ 1452 HVEM_Pruefpuls_Anf 3;
BA_ "GenSigSwitchedByIgnition" SG_ 1452 HVEM_Pruefpuls_Anf 0;
BA_ "GenSigSendType" SG_ 1385 HVEM_Abschaltstatus 3;
BA_ "GenSigStartValue" SG_ 1385 HVEM_Abschaltstatus 7;
BA_ "GenSigSwitchedByIgnition" SG_ 1385 HVEM_Abschaltstatus 0;
BA_ "GenSigSendType" SG_ 1385 HVEM_Anf_ReichweiteNV 3;
BA_ "GenSigSwitchedByIgnition" SG_ 1385 HVEM_Anf_ReichweiteNV 0;
BA_ "Fehlerwert" SG_ 1385 HVEM_Anf_ReichweiteNV 3;
BA_ "GenSigSendType" SG_ 1385 HVEM_DCDC_Freigabe 0;
BA_ "GenSigSwitchedByIgnition" SG_ 1385 HVEM_DCDC_Freigabe 0;
BA_ "GenSigSendType" SG_ 1385 HVEM_FreigabeKlimatisierung 3;
BA_ "GenSigStartValue" SG_ 1385 HVEM_FreigabeKlimatisierung 2;
BA_ "GenSigSwitchedByIgnition" SG_ 1385 HVEM_FreigabeKlimatisierung 0;
BA_ "Fehlerwert" SG_ 1385 HVEM_FreigabeKlimatisierung 3;
BA_ "GenSigSendType" SG_ 1385 HVEM_HV_Anf 3;
BA_ "GenSigSwitchedByIgnition" SG_ 1385 HVEM_HV_Anf 0;
BA_ "GenSigSendType" SG_ 1385 HVEM_KlimaMaxHVStrom 3;
BA_ "GenSigSwitchedByIgnition" SG_ 1385 HVEM_KlimaMaxHVStrom 0;
BA_ "GenSigSendType" SG_ 1385 HVEM_LadeklappenVerr_Anf 3;
BA_ "GenSigSwitchedByIgnition" SG_ 1385 HVEM_LadeklappenVerr_Anf 0;
BA_ "GenSigSendType" SG_ 1385 HVEM_Ladesteckerentr_Anf 3;
BA_ "GenSigSwitchedByIgnition" SG_ 1385 HVEM_Ladesteckerentr_Anf 0;
BA_ "GenSigSendType" SG_ 1385 HVEM_Leistung_Bat_Kond_Vorgabe 0;
BA_ "GenSigStartValue" SG_ 1385 HVEM_Leistung_Bat_Kond_Vorgabe 254;
BA_ "GenSigSwitchedByIgnition" SG_ 1385 HVEM_Leistung_Bat_Kond_Vorgabe 0;
BA_ "GenSigSendType" SG_ 1385 HVEM_LeistungsAnf 3;
BA_ "GenSigSwitchedByIgnition" SG_ 1385 HVEM_LeistungsAnf 0;
BA_ "GenSigSendType" SG_ 1385 HVEM_Max_VK_Betriebsdauer 0;
BA_ "GenSigStartValue" SG_ 1385 HVEM_Max_VK_Betriebsdauer 62;
BA_ "GenSigSwitchedByIgnition" SG_ 1385 HVEM_Max_VK_Betriebsdauer 0;
BA_ "Fehlerwert" SG_ 1385 HVEM_Max_VK_Betriebsdauer 63;
BA_ "GenSigSendType" SG_ 1385 HVEM_Nachlad_Status 3;
BA_ "GenSigStartValue" SG_ 1385 HVEM_Nachlad_Status 3;
BA_ "GenSigSwitchedByIgnition" SG_ 1385 HVEM_Nachlad_Status 0;
BA_ "GenSigSendType" SG_ 1385 HVEM_Nachladen_Anf 3;
BA_ "GenSigSwitchedByIgnition" SG_ 1385 HVEM_Nachladen_Anf 0;
BA_ "GenSigSendType" SG_ 1385 HVEM_NVLeistungEmpf 3;
BA_ "GenSigSwitchedByIgnition" SG_ 1385 HVEM_NVLeistungEmpf 0;
BA_ "GenSigSendType" SG_ 1385 HVEM_Text_1 3;
BA_ "GenSigSwitchedByIgnition" SG_ 1385 HVEM_Text_1 0;
BA_ "GenSigSendType" SG_ 1283 HV_Bordnetz_aktiv 3;
BA_ "GenSigSwitchedByIgnition" SG_ 1283 HV_Bordnetz_aktiv 0;
BA_ "GenSigSendType" SG_ 1283 HV_Bordnetz_Fehler 3;
BA_ "GenSigSwitchedByIgnition" SG_ 1283 HV_Bordnetz_Fehler 0;
BA_ "Fehlerwert" SG_ 1283 HV_Bordnetz_Fehler 1;
BA_ "GenSigSendType" SG_ 1283 HVK_01_BZ 0;
BA_ "GenSigFuncType" SG_ 1283 HVK_01_BZ 1;
BA_ "GenSigSwitchedByIgnition" SG_ 1283 HVK_01_BZ 0;
BA_ "GenSigSendType" SG_ 1283 HVK_01_CRC 0;
BA_ "GenSigFuncType" SG_ 1283 HVK_01_CRC 2;
BA_ "GenSigSwitchedByIgnition" SG_ 1283 HVK_01_CRC 0;
BA_ "GenSigSendType" SG_ 1283 HVK_AktiveEntladung_Anf 3;
BA_ "GenSigSwitchedByIgnition" SG_ 1283 HVK_AktiveEntladung_Anf 0;
BA_ "GenSigSendType" SG_ 1283 HVK_BMS_Sollmodus 3;
BA_ "GenSigStartValue" SG_ 1283 HVK_BMS_Sollmodus 7;
BA_ "GenSigSwitchedByIgnition" SG_ 1283 HVK_BMS_Sollmodus 0;
BA_ "GenSigSendType" SG_ 1283 HVK_DCDC_Sollmodus 3;
BA_ "GenSigStartValue" SG_ 1283 HVK_DCDC_Sollmodus 7;
BA_ "GenSigSwitchedByIgnition" SG_ 1283 HVK_DCDC_Sollmodus 0;
BA_ "GenSigSendType" SG_ 1283 HVK_EKK_Sollmodus 3;
BA_ "GenSigStartValue" SG_ 1283 HVK_EKK_Sollmodus 7;
BA_ "GenSigSwitchedByIgnition" SG_ 1283 HVK_EKK_Sollmodus 0;
BA_ "GenSigSendType" SG_ 1283 HVK_Gesamtst_Spgfreiheit 0;
BA_ "GenSigSwitchedByIgnition" SG_ 1283 HVK_Gesamtst_Spgfreiheit 0;
BA_ "Fehlerwert" SG_ 1283 HVK_Gesamtst_Spgfreiheit 3;
BA_ "GenSigSendType" SG_ 1283 HVK_HV_Netz_Warnungen 3;
BA_ "GenSigSwitchedByIgnition" SG_ 1283 HVK_HV_Netz_Warnungen 0;
BA_ "GenSigSendType" SG_ 1283 HVK_HVEM_Freigabe 3;
BA_ "GenSigStartValue" SG_ 1283 HVK_HVEM_Freigabe 2;
BA_ "GenSigSwitchedByIgnition" SG_ 1283 HVK_HVEM_Freigabe 0;
BA_ "GenSigSendType" SG_ 1283 HVK_HVLM_Sollmodus 3;
BA_ "GenSigStartValue" SG_ 1283 HVK_HVLM_Sollmodus 7;
BA_ "GenSigSwitchedByIgnition" SG_ 1283 HVK_HVLM_Sollmodus 0;
BA_ "GenSigSendType" SG_ 1283 HVK_HVPTC_Sollmodus 3;
BA_ "GenSigStartValue" SG_ 1283 HVK_HVPTC_Sollmodus 7;
BA_ "GenSigSwitchedByIgnition" SG_ 1283 HVK_HVPTC_Sollmodus 0;
BA_ "GenSigSendType" SG_ 1283 HVK_Iso_Messung_Start 0;
BA_ "GenSigSwitchedByIgnition" SG_ 1283 HVK_Iso_Messung_Start 0;
BA_ "GenSigSendType" SG_ 1283 HVK_Istmodus_Anf 3;
BA_ "GenSigSwitchedByIgnition" SG_ 1283 HVK_Istmodus_Anf 0;
BA_ "GenSigSendType" SG_ 1283 HVK_Ladebereit 3;
BA_ "GenSigSwitchedByIgnition" SG_ 1283 HVK_Ladebereit 0;
BA_ "GenSigSendType" SG_ 1283 HVK_Notentladung_Anf 3;
BA_ "GenSigSwitchedByIgnition" SG_ 1283 HVK_Notentladung_Anf 0;
BA_ "GenSigSendType" SG_ 1283 HVK_PPulsFreigabe 0;
BA_ "GenSigStartValue" SG_ 1283 HVK_PPulsFreigabe 3;
BA_ "GenSigSwitchedByIgnition" SG_ 1283 HVK_PPulsFreigabe 0;
BA_ "GenSigSendType" SG_ 1283 HVK_TN1_Sollmodus 3;
BA_ "GenSigStartValue" SG_ 1283 HVK_TN1_Sollmodus 3;
BA_ "GenSigSwitchedByIgnition" SG_ 1283 HVK_TN1_Sollmodus 0;
BA_ "GenSigSendType" SG_ 1283 HVK_Vorladung_aktiv 3;
BA_ "GenSigSwitchedByIgnition" SG_ 1283 HVK_Vorladung_aktiv 0;
BA_ "GenSigSendType" SG_ 2463978813 HVL_01_BZ 0;
BA_ "GenSigFuncType" SG_ 2463978813 HVL_01_BZ 1;
BA_ "GenSigSwitchedByIgnition" SG_ 2463978813 HVL_01_BZ 0;
BA_ "GenSigSendType" SG_ 2463978813 HVL_01_CRC 0;
BA_ "GenSigFuncType" SG_ 2463978813 HVL_01_CRC 2;
BA_ "GenSigSwitchedByIgnition" SG_ 2463978813 HVL_01_CRC 0;
BA_ "GenSigSendType" SG_ 2463978813 HVL_LadeAnforderung 3;
BA_ "GenSigSwitchedByIgnition" SG_ 2463978813 HVL_LadeAnforderung 0;
BA_ "Fehlerwert" SG_ 2463978813 HVL_LadeAnforderung 7;
BA_ "GenSigSendType" SG_ 2463978813 HVL_Steckerstatus 0;
BA_ "GenSigSwitchedByIgnition" SG_ 2463978813 HVL_Steckerstatus 0;
BA_ "Fehlerwert" SG_ 2463978813 HVL_Steckerstatus 3;
BA_ "GenSigSendType" SG_ 626 HVLM_Anforderung_HMS 0;
BA_ "GenSigSwitchedByIgnition" SG_ 626 HVLM_Anforderung_HMS 0;
BA_ "GenSigSendType" SG_ 626 HVLM_AWC_VerbautStatus 0;
BA_ "GenSigSwitchedByIgnition" SG_ 626 HVLM_AWC_VerbautStatus 0;
BA_ "Fehlerwert" SG_ 626 HVLM_AWC_VerbautStatus 3;
BA_ "GenSigSendType" SG_ 626 HVLM_DC_Aufstartmodus 0;
BA_ "GenSigSwitchedByIgnition" SG_ 626 HVLM_DC_Aufstartmodus 0;
BA_ "GenSigSendType" SG_ 626 HVLM_Intensitaet 3;
BA_ "GenSigStartValue" SG_ 626 HVLM_Intensitaet 126;
BA_ "GenSigSwitchedByIgnition" SG_ 626 HVLM_Intensitaet 0;
BA_ "Fehlerwert" SG_ 626 HVLM_Intensitaet 127;
BA_ "GenSigSendType" SG_ 626 HVLM_Laden_ISO_Messung_Anf 0;
BA_ "GenSigStartValue" SG_ 626 HVLM_Laden_ISO_Messung_Anf 1;
BA_ "GenSigSwitchedByIgnition" SG_ 626 HVLM_Laden_ISO_Messung_Anf 0;
BA_ "GenSigSendType" SG_ 626 HVLM_Ladeszenario 3;
BA_ "GenSigStartValue" SG_ 626 HVLM_Ladeszenario 30;
BA_ "GenSigSwitchedByIgnition" SG_ 626 HVLM_Ladeszenario 0;
BA_ "Fehlerwert" SG_ 626 HVLM_Ladeszenario 31;
BA_ "GenSigSendType" SG_ 626 HVLM_Ladevorgang_Anf 0;
BA_ "GenSigSwitchedByIgnition" SG_ 626 HVLM_Ladevorgang_Anf 0;
BA_ "GenSigSendType" SG_ 626 HVLM_Parken_beibehalten_HMS 0;
BA_ "GenSigStartValue" SG_ 626 HVLM_Parken_beibehalten_HMS 2;
BA_ "GenSigSwitchedByIgnition" SG_ 626 HVLM_Parken_beibehalten_HMS 0;
BA_ "Fehlerwert" SG_ 626 HVLM_Parken_beibehalten_HMS 3;
BA_ "GenSigSendType" SG_ 626 HVLM_Start_Pulserkennung 0;
BA_ "GenSigSwitchedByIgnition" SG_ 626 HVLM_Start_Pulserkennung 0;
BA_ "GenSigSendType" SG_ 626 HVLM_Steckerstatus_A 3;
BA_ "GenSigSwitchedByIgnition" SG_ 626 HVLM_Steckerstatus_A 0;
BA_ "Fehlerwert" SG_ 626 HVLM_Steckerstatus_A 7;
BA_ "GenSigSendType" SG_ 626 HVLM_Steckerstatus_B 3;
BA_ "GenSigSwitchedByIgnition" SG_ 626 HVLM_Steckerstatus_B 0;
BA_ "Fehlerwert" SG_ 626 HVLM_Steckerstatus_B 7;
BA_ "GenSigSendType" SG_ 626 HVLM_WakeUpZaehlerResetAnf 0;
BA_ "GenSigSwitchedByIgnition" SG_ 626 HVLM_WakeUpZaehlerResetAnf 0;
BA_ "GenSigSendType" SG_ 626 HVLM_ZustandLadeablauf 0;
BA_ "GenSigSwitchedByIgnition" SG_ 626 HVLM_ZustandLadeablauf 0;
BA_ "GenSigSendType" SG_ 268 ImoCord_Auth_Aufforderung_WFS 3;
BA_ "GenSigSwitchedByIgnition" SG_ 268 ImoCord_Auth_Aufforderung_WFS 0;
BA_ "GenSigSwitchedByIgnition" SG_ 23 WFS_IMMO_MSG3_CRC 0;
BA_ "GenSigSendType" SG_ 23 WFS_IMMO_MSG3_Status 1;
BA_ "GenSigSwitchedByIgnition" SG_ 23 WFS_IMMO_MSG3_Status 0;
BA_ "GenSigSwitchedByIgnition" SG_ 25 WFS_IMMO_MSG4_CRC 0;
BA_ "GenSigSendType" SG_ 25 WFS_IMMO_MSG4_Status 1;
BA_ "GenSigSwitchedByIgnition" SG_ 25 WFS_IMMO_MSG4_Status 0;
BA_ "GenSigActiveRepetitions" SG_ 2527679583 IPA_Anf_Meldungen 5;
BA_ "GenSigSendType" SG_ 2527679583 IPA_Anf_Meldungen 4;
BA_ "GenSigSwitchedByIgnition" SG_ 2527679583 IPA_Anf_Meldungen 0;
BA_ "GenSigActiveRepetitions" SG_ 2527679583 Parken_aktives_System_02 5;
BA_ "GenSigSendType" SG_ 2527679583 Parken_aktives_System_02 4;
BA_ "GenSigSwitchedByIgnition" SG_ 2527679583 Parken_aktives_System_02 0;
BA_ "GenSigActiveRepetitions" SG_ 2527679583 Parken_Aktivierungslicht_Anf 5;
BA_ "GenSigSendType" SG_ 2527679583 Parken_Aktivierungslicht_Anf 4;
BA_ "GenSigSwitchedByIgnition" SG_ 2527679583 Parken_Aktivierungslicht_Anf 0;
BA_ "GenSigActiveRepetitions" SG_ 2527679583 Parken_Bestaetigungsblinken_Anf 5;
BA_ "GenSigSendType" SG_ 2527679583 Parken_Bestaetigungsblinken_Anf 4;
BA_ "GenSigSwitchedByIgnition" SG_ 2527679583 Parken_Bestaetigungsblinken_Anf 0;
BA_ "GenSigActiveRepetitions" SG_ 2527679583 Parken_Fahrbereitschaftlicht_Anf 5;
BA_ "GenSigSendType" SG_ 2527679583 Parken_Fahrbereitschaftlicht_Anf 4;
BA_ "GenSigActiveRepetitions" SG_ 2527679583 Parken_Fahrerhinweise_Anf 5;
BA_ "GenSigSendType" SG_ 2527679583 Parken_Fahrerhinweise_Anf 4;
BA_ "GenSigSwitchedByIgnition" SG_ 2527679583 Parken_Fahrerhinweise_Anf 0;
BA_ "GenSigActiveRepetitions" SG_ 2527679583 Parken_Fahrtrichtungslicht_Anf 5;
BA_ "GenSigSendType" SG_ 2527679583 Parken_Fahrtrichtungslicht_Anf 4;
BA_ "GenSigActiveRepetitions" SG_ 2527679583 Parken_FFB_LED_Anf 5;
BA_ "GenSigSendType" SG_ 2527679583 Parken_FFB_LED_Anf 4;
BA_ "GenSigActiveRepetitions" SG_ 2527679583 Parken_Lichtnachlauf_Anf 5;
BA_ "GenSigSendType" SG_ 2527679583 Parken_Lichtnachlauf_Anf 4;
BA_ "GenSigActiveRepetitions" SG_ 2527679583 Parken_Lichtsteuerung_Anf 5;
BA_ "GenSigSendType" SG_ 2527679583 Parken_Lichtsteuerung_Anf 4;
BA_ "GenSigSwitchedByIgnition" SG_ 2527679583 Parken_Lichtsteuerung_Anf 0;
BA_ "GenSigActiveRepetitions" SG_ 2527679583 Parken_Schluesselsuche_Anf 5;
BA_ "GenSigSendType" SG_ 2527679583 Parken_Schluesselsuche_Anf 4;
BA_ "GenSigActiveRepetitions" SG_ 2527679583 Parken_Seitenspiegel_Anf 5;
BA_ "GenSigSendType" SG_ 2527679583 Parken_Seitenspiegel_Anf 4;
BA_ "GenSigActiveRepetitions" SG_ 2527679583 Parken_Wegfahrsperren_Anf 5;
BA_ "GenSigSendType" SG_ 2527679583 Parken_Wegfahrsperren_Anf 4;
BA_ "GenSigActiveRepetitions" SG_ 2527679583 Parken_ZR_Sondermodus_Anf 5;
BA_ "GenSigSendType" SG_ 2527679583 Parken_ZR_Sondermodus_Anf 4;
BA_ "GenSigSwitchedByIgnition" SG_ 2527679583 Parken_ZR_Sondermodus_Anf 0;
BA_ "GenSigActiveRepetitions" SG_ 2527679583 Parken_ZV_Schliessen 5;
BA_ "GenSigSendType" SG_ 2527679583 Parken_ZV_Schliessen 4;
BA_ "GenSigSendType" SG_ 1813 ISO_Airbag_01_Req_Data 3;
BA_ "GenSigFuncType" SG_ 1813 ISO_Airbag_01_Req_Data 9;
BA_ "GenSigSwitchedByIgnition" SG_ 1813 ISO_Airbag_01_Req_Data 0;
BA_ "GenSigSendType" SG_ 1919 ISO_Airbag_01_Resp_Data 3;
BA_ "GenSigFuncType" SG_ 1919 ISO_Airbag_01_Resp_Data 9;
BA_ "GenSigSwitchedByIgnition" SG_ 1919 ISO_Airbag_01_Resp_Data 0;
BA_ "GenSigSendType" SG_ 1792 ISO_ALL_01_Req_Data 3;
BA_ "GenSigFuncType" SG_ 1792 ISO_ALL_01_Req_Data 9;
BA_ "GenSigSwitchedByIgnition" SG_ 1792 ISO_ALL_01_Req_Data 0;
BA_ "GenSigSendType" SG_ 2621440021 ISOx_Airbag_01_Req_FD_Data 3;
BA_ "GenSigFuncType" SG_ 2621440021 ISOx_Airbag_01_Req_FD_Data 9;
BA_ "GenSigSwitchedByIgnition" SG_ 2621440021 ISOx_Airbag_01_Req_FD_Data 0;
BA_ "GenSigSendType" SG_ 2621571093 ISOx_Airbag_01_Resp_FD_Data 3;
BA_ "GenSigFuncType" SG_ 2621571093 ISOx_Airbag_01_Resp_FD_Data 9;
BA_ "GenSigSwitchedByIgnition" SG_ 2621571093 ISOx_Airbag_01_Resp_FD_Data 0;
BA_ "GenSigSendType" SG_ 2549874812 ISO_EMotor_01_Req_Data 3;
BA_ "GenSigFuncType" SG_ 2549874812 ISO_EMotor_01_Req_Data 9;
BA_ "GenSigSwitchedByIgnition" SG_ 2549874812 ISO_EMotor_01_Req_Data 0;
BA_ "GenSigSendType" SG_ 2621440124 ISOx_EMotor_01_Req_FD_Data 3;
BA_ "GenSigFuncType" SG_ 2621440124 ISOx_EMotor_01_Req_FD_Data 9;
BA_ "GenSigSwitchedByIgnition" SG_ 2621440124 ISOx_EMotor_01_Req_FD_Data 0;
BA_ "GenSigSendType" SG_ 2550005884 ISO_EMotor_01_Resp_Data 3;
BA_ "GenSigFuncType" SG_ 2550005884 ISO_EMotor_01_Resp_Data 9;
BA_ "GenSigSwitchedByIgnition" SG_ 2550005884 ISO_EMotor_01_Resp_Data 0;
BA_ "GenSigSendType" SG_ 2621571196 ISOx_EMotor_01_Resp_FD_Data 3;
BA_ "GenSigFuncType" SG_ 2621571196 ISOx_EMotor_01_Resp_FD_Data 9;
BA_ "GenSigSwitchedByIgnition" SG_ 2621571196 ISOx_EMotor_01_Resp_FD_Data 0;
BA_ "GenSigSendType" SG_ 2549874872 ISO_EMotor_02_Req_Data 3;
BA_ "GenSigFuncType" SG_ 2549874872 ISO_EMotor_02_Req_Data 9;
BA_ "GenSigSwitchedByIgnition" SG_ 2549874872 ISO_EMotor_02_Req_Data 0;
BA_ "GenSigSendType" SG_ 2621440184 ISOx_EMotor_02_Req_FD_Data 3;
BA_ "GenSigFuncType" SG_ 2621440184 ISOx_EMotor_02_Req_FD_Data 9;
BA_ "GenSigSwitchedByIgnition" SG_ 2621440184 ISOx_EMotor_02_Req_FD_Data 0;
BA_ "GenSigSendType" SG_ 2550005944 ISO_EMotor_02_Resp_Data 3;
BA_ "GenSigFuncType" SG_ 2550005944 ISO_EMotor_02_Resp_Data 9;
BA_ "GenSigSwitchedByIgnition" SG_ 2550005944 ISO_EMotor_02_Resp_Data 0;
BA_ "GenSigSendType" SG_ 2621571256 ISOx_EMotor_02_Resp_FD_Data 3;
BA_ "GenSigFuncType" SG_ 2621571256 ISOx_EMotor_02_Resp_FD_Data 9;
BA_ "GenSigSwitchedByIgnition" SG_ 2621571256 ISOx_EMotor_02_Resp_FD_Data 0;
BA_ "GenSigSendType" SG_ 2621505536 ISOx_Funkt_Req_All_FD_Data 3;
BA_ "GenSigFuncType" SG_ 2621505536 ISOx_Funkt_Req_All_FD_Data 9;
BA_ "GenSigSwitchedByIgnition" SG_ 2621505536 ISOx_Funkt_Req_All_FD_Data 0;
BA_ "GenSigSendType" SG_ 2549874806 ISOx_MO_01_Req_Data 3;
BA_ "GenSigFuncType" SG_ 2549874806 ISOx_MO_01_Req_Data 9;
BA_ "GenSigSwitchedByIgnition" SG_ 2549874806 ISOx_MO_01_Req_Data 0;
BA_ "GenSigSendType" SG_ 2621440118 ISOx_MO_01_Req_FD_Data 3;
BA_ "GenSigFuncType" SG_ 2621440118 ISOx_MO_01_Req_FD_Data 9;
BA_ "GenSigSwitchedByIgnition" SG_ 2621440118 ISOx_MO_01_Req_FD_Data 0;
BA_ "GenSigSendType" SG_ 2550005878 ISOx_MO_01_Resp_Data 3;
BA_ "GenSigFuncType" SG_ 2550005878 ISOx_MO_01_Resp_Data 9;
BA_ "GenSigSwitchedByIgnition" SG_ 2550005878 ISOx_MO_01_Resp_Data 0;
BA_ "GenSigSendType" SG_ 2621571190 ISOx_MO_01_Resp_FD_Data 3;
BA_ "GenSigFuncType" SG_ 2621571190 ISOx_MO_01_Resp_FD_Data 9;
BA_ "GenSigSwitchedByIgnition" SG_ 2621571190 ISOx_MO_01_Resp_FD_Data 0;
BA_ "GenSigSendType" SG_ 2527679684 Kamera_ASM_Data_1 0;
BA_ "GenSigSendType" SG_ 2527679684 Kamera_ASM_Data_2 0;
BA_ "GenSigSendType" SG_ 2527679684 Kamera_ASM_Data_3 0;
BA_ "GenSigSendType" SG_ 2527679684 Kamera_ASM_Data_4 0;
BA_ "GenSigSendType" SG_ 2527679684 Kamera_ASM_Data_5 0;
BA_ "GenSigSendType" SG_ 2527679684 Kamera_ASM_Data_6 0;
BA_ "GenSigSendType" SG_ 2527679684 Kamera_ASM_Ereignis 3;
BA_ "GenSigSendType" SG_ 2527679684 Kamera_ASM_Zeitstempel 3;
BA_ "GenSigStartValue" SG_ 2527679684 Kamera_ASM_Zeitstempel 255;
BA_ "GenSigSendType" SG_ 960 BCM_Ausparken_Betrieb 3;
BA_ "GenSigSwitchedByIgnition" SG_ 960 BCM_Ausparken_Betrieb 0;
BA_ "GenSigSendType" SG_ 960 BCM_Remotestart_Betrieb 3;
BA_ "GenSigSwitchedByIgnition" SG_ 960 BCM_Remotestart_Betrieb 0;
BA_ "GenSigSendType" SG_ 960 BCM_Remotestart_KL15_Anf 3;
BA_ "GenSigSwitchedByIgnition" SG_ 960 BCM_Remotestart_KL15_Anf 0;
BA_ "GenSigSendType" SG_ 960 BCM_Remotestart_MO_Start 3;
BA_ "GenSigSwitchedByIgnition" SG_ 960 BCM_Remotestart_MO_Start 0;
BA_ "GenSigSendType" SG_ 960 Klemmen_Status_01_BZ 0;
BA_ "GenSigFuncType" SG_ 960 Klemmen_Status_01_BZ 1;
BA_ "GenSigSwitchedByIgnition" SG_ 960 Klemmen_Status_01_BZ 0;
BA_ "GenSigSendType" SG_ 960 Klemmen_Status_01_CRC 0;
BA_ "GenSigFuncType" SG_ 960 Klemmen_Status_01_CRC 2;
BA_ "GenSigSwitchedByIgnition" SG_ 960 Klemmen_Status_01_CRC 0;
BA_ "GenSigSendType" SG_ 960 KST_Fahrerhinweis_1 3;
BA_ "GenSigSwitchedByIgnition" SG_ 960 KST_Fahrerhinweis_1 0;
BA_ "GenSigSendType" SG_ 960 KST_Fahrerhinweis_2 3;
BA_ "GenSigSwitchedByIgnition" SG_ 960 KST_Fahrerhinweis_2 0;
BA_ "GenSigSendType" SG_ 960 KST_Fahrerhinweis_4 3;
BA_ "GenSigSwitchedByIgnition" SG_ 960 KST_Fahrerhinweis_4 0;
BA_ "GenSigSendType" SG_ 960 KST_Fahrerhinweis_5 3;
BA_ "GenSigSwitchedByIgnition" SG_ 960 KST_Fahrerhinweis_5 0;
BA_ "GenSigSendType" SG_ 960 KST_Fahrerhinweis_6 3;
BA_ "GenSigSwitchedByIgnition" SG_ 960 KST_Fahrerhinweis_6 0;
BA_ "GenSigSendType" SG_ 960 KST_Warn_P1_ZST_def 3;
BA_ "GenSigSwitchedByIgnition" SG_ 960 KST_Warn_P1_ZST_def 0;
BA_ "GenSigSendType" SG_ 960 KST_Warn_P2_ZST_def 3;
BA_ "GenSigSwitchedByIgnition" SG_ 960 KST_Warn_P2_ZST_def 0;
BA_ "GenSigSendType" SG_ 960 RSt_Fahrerhinweise 3;
BA_ "GenSigSwitchedByIgnition" SG_ 960 RSt_Fahrerhinweise 0;
BA_ "GenSigSendType" SG_ 960 ZAS_Kl_15 3;
BA_ "NWM-WakeupAllowed" SG_ 960 ZAS_Kl_15 1;
BA_ "GenSigFuncType" SG_ 960 ZAS_Kl_15 6;
BA_ "GenSigSwitchedByIgnition" SG_ 960 ZAS_Kl_15 0;
BA_ "GenSigSendType" SG_ 960 ZAS_Kl_50_Startanforderung 3;
BA_ "GenSigSwitchedByIgnition" SG_ 960 ZAS_Kl_50_Startanforderung 0;
BA_ "GenSigSendType" SG_ 960 ZAS_Kl_Infotainment 3;
BA_ "GenSigSwitchedByIgnition" SG_ 960 ZAS_Kl_Infotainment 0;
BA_ "GenSigSendType" SG_ 960 ZAS_Kl_S 3;
BA_ "GenSigSwitchedByIgnition" SG_ 960 ZAS_Kl_S 0;
BA_ "GenSigSendType" SG_ 960 ZAS_Kl_X 3;
BA_ "GenSigSwitchedByIgnition" SG_ 960 ZAS_Kl_X 0;
BA_ "GenSigSendType" SG_ 2463978753 KST_Sonderzustand_Anforderung 4;
BA_ "GenSigSwitchedByIgnition" SG_ 2463978753 KST_Sonderzustand_Anforderung 0;
BA_ "Fehlerwert" SG_ 2463978753 KST_Sonderzustand_Anforderung 31;
BA_ "GenSigSendType" SG_ 2463978753 KST_Sonderzustand_Status 4;
BA_ "GenSigSwitchedByIgnition" SG_ 2463978753 KST_Sonderzustand_Status 0;
BA_ "Fehlerwert" SG_ 2463978753 KST_Sonderzustand_Status 3;
BA_ "GenSigSendType" SG_ 2463978753 KST_WFS_Fahrfreigabe_Anforderung 4;
BA_ "GenSigSwitchedByIgnition" SG_ 2463978753 KST_WFS_Fahrfreigabe_Anforderung 0;
BA_ "GenSigSendType" SG_ 1420 Klemmen_Steuerung_01_BZ 0;
BA_ "GenSigFuncType" SG_ 1420 Klemmen_Steuerung_01_BZ 1;
BA_ "GenSigSwitchedByIgnition" SG_ 1420 Klemmen_Steuerung_01_BZ 0;
BA_ "GenSigSendType" SG_ 1420 Klemmen_Steuerung_01_CRC 0;
BA_ "GenSigFuncType" SG_ 1420 Klemmen_Steuerung_01_CRC 2;
BA_ "GenSigSwitchedByIgnition" SG_ 1420 Klemmen_Steuerung_01_CRC 0;
BA_ "GenSigSendType" SG_ 1420 KST_Anf_Klemme_15 4;
BA_ "GenSigSwitchedByIgnition" SG_ 1420 KST_Anf_Klemme_15 0;
BA_ "GenSigSendType" SG_ 1420 KST_Anf_Klemme_50 4;
BA_ "GenSigSwitchedByIgnition" SG_ 1420 KST_Anf_Klemme_50 0;
BA_ "GenSigSendType" SG_ 1420 KST_Anf_Klemme_S 3;
BA_ "GenSigSwitchedByIgnition" SG_ 1420 KST_Anf_Klemme_S 0;
BA_ "GenSigSendType" SG_ 1420 KST_Anf_Klemmenfreigabe_ELV 3;
BA_ "GenSigSwitchedByIgnition" SG_ 1420 KST_Anf_Klemmenfreigabe_ELV 0;
BA_ "GenSigSendType" SG_ 1420 KST_Anf_Klemmenfreigabe_WFS 3;
BA_ "GenSigSwitchedByIgnition" SG_ 1420 KST_Anf_Klemmenfreigabe_WFS 0;
BA_ "GenSigSendType" SG_ 1420 KST_Anf_ZV_Verriegelung 3;
BA_ "GenSigSwitchedByIgnition" SG_ 1420 KST_Anf_ZV_Verriegelung 0;
BA_ "GenSigSendType" SG_ 1420 KST_aut_Abschaltung_Zuendung 4;
BA_ "GenSigSwitchedByIgnition" SG_ 1420 KST_aut_Abschaltung_Zuendung 0;
BA_ "GenSigSendType" SG_ 1420 KST_Fahrer_Info_Text 3;
BA_ "GenSigSwitchedByIgnition" SG_ 1420 KST_Fahrer_Info_Text 0;
BA_ "GenSigSendType" SG_ 1420 KST_Txt_Komfortabschaltung 3;
BA_ "GenSigSwitchedByIgnition" SG_ 1420 KST_Txt_Komfortabschaltung 0;
BA_ "GenSigSendType" SG_ 1420 KST_Txt_P_Gang 3;
BA_ "GenSigSwitchedByIgnition" SG_ 1420 KST_Txt_P_Gang 0;
BA_ "GenSigSendType" SG_ 1420 KST_Txt_Panikabschaltung 3;
BA_ "GenSigSwitchedByIgnition" SG_ 1420 KST_Txt_Panikabschaltung 0;
BA_ "GenSigSendType" SG_ 1420 KST_Txt_Werkstatt 3;
BA_ "GenSigSwitchedByIgnition" SG_ 1420 KST_Txt_Werkstatt 0;
BA_ "GenSigSendType" SG_ 1420 KST_Unterdr_Zuendungsmeldung 3;
BA_ "GenSigSwitchedByIgnition" SG_ 1420 KST_Unterdr_Zuendungsmeldung 0;
BA_ "GenSigSendType" SG_ 1420 KST_ZAT_betaetigt 3;
BA_ "GenSigSwitchedByIgnition" SG_ 1420 KST_ZAT_betaetigt 0;
BA_ "GenSigSendType" SG_ 1420 KST_Zuendungswarnung 4;
BA_ "GenSigSwitchedByIgnition" SG_ 1420 KST_Zuendungswarnung 0;
BA_ "GenSigSendType" SG_ 1420 Relais_VoKo_angesteuert 3;
BA_ "GenSigSwitchedByIgnition" SG_ 1420 Relais_VoKo_angesteuert 0;
BA_ "GenSigSendType" SG_ 1420 RSt_Anforderung_HMS 3;
BA_ "GenSigSwitchedByIgnition" SG_ 1420 RSt_Anforderung_HMS 0;
BA_ "GenSigSendType" SG_ 949 KL_AC_Schalter 0;
BA_ "GenSigSwitchedByIgnition" SG_ 949 KL_AC_Schalter 0;
BA_ "GenSigSendType" SG_ 949 KL_Anf_KL 0;
BA_ "GenSigSwitchedByIgnition" SG_ 949 KL_Anf_KL 0;
BA_ "Fehlerwert" SG_ 949 KL_Anf_KL 255;
BA_ "GenSigSendType" SG_ 949 KL_Anf_KV 0;
BA_ "GenSigStartValue" SG_ 949 KL_Anf_KV 126;
BA_ "GenSigSwitchedByIgnition" SG_ 949 KL_Anf_KV 0;
BA_ "GenSigSendType" SG_ 949 KL_Ausstattung_Klima 0;
BA_ "GenSigSwitchedByIgnition" SG_ 949 KL_Ausstattung_Klima 0;
BA_ "GenSigSendType" SG_ 949 KL_Charisma_FahrPr 0;
BA_ "GenSigSwitchedByIgnition" SG_ 949 KL_Charisma_FahrPr 0;
BA_ "GenSigSendType" SG_ 949 KL_Charisma_Status 0;
BA_ "GenSigSwitchedByIgnition" SG_ 949 KL_Charisma_Status 0;
BA_ "GenSigSendType" SG_ 949 KL_Drehz_Anh 0;
BA_ "GenSigSwitchedByIgnition" SG_ 949 KL_Drehz_Anh 0;
BA_ "GenSigSendType" SG_ 949 KL_el_Zuheizer_Stufe 0;
BA_ "GenSigSwitchedByIgnition" SG_ 949 KL_el_Zuheizer_Stufe 0;
BA_ "GenSigSendType" SG_ 949 KL_Freilauf_Info 0;
BA_ "GenSigSwitchedByIgnition" SG_ 949 KL_Freilauf_Info 0;
BA_ "GenSigSendType" SG_ 949 KL_Komp_Moment_alt 0;
BA_ "GenSigFuncType" SG_ 949 KL_Komp_Moment_alt 5;
BA_ "GenSigSwitchedByIgnition" SG_ 949 KL_Komp_Moment_alt 0;
BA_ "GenSigSendType" SG_ 949 KL_Kompressorkupplung_linear 0;
BA_ "GenSigStartValue" SG_ 949 KL_Kompressorkupplung_linear 254;
BA_ "GenSigSwitchedByIgnition" SG_ 949 KL_Kompressorkupplung_linear 0;
BA_ "GenSigSendType" SG_ 949 KL_Last_Kompr 0;
BA_ "GenSigSwitchedByIgnition" SG_ 949 KL_Last_Kompr 0;
BA_ "Fehlerwert" SG_ 949 KL_Last_Kompr 255;
BA_ "GenSigSendType" SG_ 949 KL_nachtr_Stopp_Anf 0;
BA_ "GenSigSwitchedByIgnition" SG_ 949 KL_nachtr_Stopp_Anf 0;
BA_ "GenSigSendType" SG_ 949 KL_Spannungs_Anf 0;
BA_ "GenSigSwitchedByIgnition" SG_ 949 KL_Spannungs_Anf 0;
BA_ "GenSigSendType" SG_ 949 KL_StartStopp_Info 0;
BA_ "GenSigSwitchedByIgnition" SG_ 949 KL_StartStopp_Info 0;
BA_ "GenSigSendType" SG_ 949 KL_T_Charge 0;
BA_ "GenSigSwitchedByIgnition" SG_ 949 KL_T_Charge 0;
BA_ "GenSigSendType" SG_ 949 KL_Thermomanagement 0;
BA_ "GenSigSwitchedByIgnition" SG_ 949 KL_Thermomanagement 0;
BA_ "GenSigSendType" SG_ 949 KL_Variante_Standheizung 0;
BA_ "GenSigSwitchedByIgnition" SG_ 949 KL_Variante_Standheizung 0;
BA_ "GenSigSendType" SG_ 949 KL_Vorwarn_Komp_ein 0;
BA_ "GenSigSwitchedByIgnition" SG_ 949 KL_Vorwarn_Komp_ein 0;
BA_ "GenSigSendType" SG_ 949 KL_Vorwarn_Zuheizer_ein 0;
BA_ "GenSigSwitchedByIgnition" SG_ 949 KL_Vorwarn_Zuheizer_ein 0;
BA_ "GenSigSendType" SG_ 949 KL_Zustand 0;
BA_ "GenSigSwitchedByIgnition" SG_ 949 KL_Zustand 0;
BA_ "GenSigSendType" SG_ 1511 KL_BattKond_WaPu_DZMax 0;
BA_ "GenSigStartValue" SG_ 1511 KL_BattKond_WaPu_DZMax 62;
BA_ "GenSigSwitchedByIgnition" SG_ 1511 KL_BattKond_WaPu_DZMax 0;
BA_ "Fehlerwert" SG_ 1511 KL_BattKond_WaPu_DZMax 63;
BA_ "GenSigSendType" SG_ 1511 KL_EKK_Strom 0;
BA_ "GenSigStartValue" SG_ 1511 KL_EKK_Strom 255;
BA_ "GenSigSwitchedByIgnition" SG_ 1511 KL_EKK_Strom 0;
BA_ "GenSigSendType" SG_ 1511 KL_Fehler_HV_EKK 0;
BA_ "GenSigSwitchedByIgnition" SG_ 1511 KL_Fehler_HV_EKK 0;
BA_ "Fehlerwert" SG_ 1511 KL_Fehler_HV_EKK 3;
BA_ "GenSigSendType" SG_ 1511 KL_Fehler_HV_Heizer 0;
BA_ "GenSigSwitchedByIgnition" SG_ 1511 KL_Fehler_HV_Heizer 0;
BA_ "Fehlerwert" SG_ 1511 KL_Fehler_HV_Heizer 3;
BA_ "GenSigSendType" SG_ 1511 KL_HV_Heizer_Strom 0;
BA_ "GenSigStartValue" SG_ 1511 KL_HV_Heizer_Strom 255;
BA_ "GenSigSwitchedByIgnition" SG_ 1511 KL_HV_Heizer_Strom 0;
BA_ "GenSigSendType" SG_ 1511 KL_KM_ASV_01_Status 0;
BA_ "GenSigSwitchedByIgnition" SG_ 1511 KL_KM_ASV_01_Status 0;
BA_ "Fehlerwert" SG_ 1511 KL_KM_ASV_01_Status 3;
BA_ "GenSigSendType" SG_ 1511 KL_KM_ASV_02_Status 0;
BA_ "GenSigSwitchedByIgnition" SG_ 1511 KL_KM_ASV_02_Status 0;
BA_ "Fehlerwert" SG_ 1511 KL_KM_ASV_02_Status 3;
BA_ "GenSigSendType" SG_ 1511 KL_Pumpe_02_Soll 0;
BA_ "GenSigStartValue" SG_ 1511 KL_Pumpe_02_Soll 126;
BA_ "GenSigSwitchedByIgnition" SG_ 1511 KL_Pumpe_02_Soll 0;
BA_ "Fehlerwert" SG_ 1511 KL_Pumpe_02_Soll 127;
BA_ "GenSigSendType" SG_ 1511 KL_Senderkennung 0;
BA_ "GenSigSwitchedByIgnition" SG_ 1511 KL_Senderkennung 0;
BA_ "GenSigSendType" SG_ 1511 KL_Status_EoHVL_EKK 0;
BA_ "GenSigSwitchedByIgnition" SG_ 1511 KL_Status_EoHVL_EKK 0;
BA_ "Fehlerwert" SG_ 1511 KL_Status_EoHVL_EKK 3;
BA_ "GenSigSendType" SG_ 1511 KL_Status_EoHVL_Heizer 0;
BA_ "GenSigSwitchedByIgnition" SG_ 1511 KL_Status_EoHVL_Heizer 0;
BA_ "Fehlerwert" SG_ 1511 KL_Status_EoHVL_Heizer 3;
BA_ "GenSigSendType" SG_ 1511 KL_Ventil_03_Soll 0;
BA_ "GenSigSwitchedByIgnition" SG_ 1511 KL_Ventil_03_Soll 0;
BA_ "GenSigSendType" SG_ 1511 KL_Ventil_10_Status 0;
BA_ "GenSigStartValue" SG_ 1511 KL_Ventil_10_Status 6;
BA_ "GenSigSwitchedByIgnition" SG_ 1511 KL_Ventil_10_Status 0;
BA_ "Fehlerwert" SG_ 1511 KL_Ventil_10_Status 7;
BA_ "GenSigSendType" SG_ 1511 KL_Vorwarn_HVHeizer_Leistung 0;
BA_ "GenSigSwitchedByIgnition" SG_ 1511 KL_Vorwarn_HVHeizer_Leistung 0;
BA_ "Fehlerwert" SG_ 1511 KL_Vorwarn_HVHeizer_Leistung 15;
BA_ "GenSigSendType" SG_ 1511 WP_KJ_Soll 0;
BA_ "GenSigSwitchedByIgnition" SG_ 1511 WP_KJ_Soll 0;
BA_ "Fehlerwert" SG_ 1511 WP_KJ_Soll 3;
BA_ "GenSigSendType" SG_ 1511 WP_Kuehlerluefter_Anf 0;
BA_ "GenSigSwitchedByIgnition" SG_ 1511 WP_Kuehlerluefter_Anf 0;
BA_ "Fehlerwert" SG_ 1511 WP_Kuehlerluefter_Anf 255;
BA_ "GenSigSendType" SG_ 1505 BCM1_Aussen_Temp_ungef 0;
BA_ "GenSigStartValue" SG_ 1505 BCM1_Aussen_Temp_ungef 254;
BA_ "GenSigSwitchedByIgnition" SG_ 1505 BCM1_Aussen_Temp_ungef 0;
BA_ "Fehlerwert" SG_ 1505 BCM1_Aussen_Temp_ungef 255;
BA_ "GenSigSendType" SG_ 1505 BCM1_FStatus_Aussentemp_ungef 0;
BA_ "GenSigStartValue" SG_ 1505 BCM1_FStatus_Aussentemp_ungef 1;
BA_ "GenSigSwitchedByIgnition" SG_ 1505 BCM1_FStatus_Aussentemp_ungef 0;
BA_ "GenSigSendType" SG_ 1505 BCM1_Kompressorstrom_ist 0;
BA_ "GenSigStartValue" SG_ 1505 BCM1_Kompressorstrom_ist 254;
BA_ "GenSigSwitchedByIgnition" SG_ 1505 BCM1_Kompressorstrom_ist 0;
BA_ "Fehlerwert" SG_ 1505 BCM1_Kompressorstrom_ist 255;
BA_ "GenSigSendType" SG_ 1505 BCM1_OBD_FStatus_ATemp 0;
BA_ "GenSigSwitchedByIgnition" SG_ 1505 BCM1_OBD_FStatus_ATemp 0;
BA_ "GenSigSendType" SG_ 1505 BCM1_PTC_stufig_Status 0;
BA_ "GenSigStartValue" SG_ 1505 BCM1_PTC_stufig_Status 6;
BA_ "GenSigSwitchedByIgnition" SG_ 1505 BCM1_PTC_stufig_Status 0;
BA_ "Fehlerwert" SG_ 1505 BCM1_PTC_stufig_Status 7;
BA_ "GenSigSendType" SG_ 1505 BCM_Heizungsabsperrventil_Status 0;
BA_ "GenSigStartValue" SG_ 1505 BCM_Heizungsabsperrventil_Status 2;
BA_ "GenSigSwitchedByIgnition" SG_ 1505 BCM_Heizungsabsperrventil_Status 0;
BA_ "Fehlerwert" SG_ 1505 BCM_Heizungsabsperrventil_Status 3;
BA_ "GenSigSendType" SG_ 1505 BCM_Heizungspumpe_Status 0;
BA_ "GenSigStartValue" SG_ 1505 BCM_Heizungspumpe_Status 2;
BA_ "GenSigSwitchedByIgnition" SG_ 1505 BCM_Heizungspumpe_Status 0;
BA_ "Fehlerwert" SG_ 1505 BCM_Heizungspumpe_Status 3;
BA_ "GenSigSendType" SG_ 1505 BCM_Kompressorkupplung_Status 0;
BA_ "GenSigStartValue" SG_ 1505 BCM_Kompressorkupplung_Status 2;
BA_ "GenSigSwitchedByIgnition" SG_ 1505 BCM_Kompressorkupplung_Status 0;
BA_ "Fehlerwert" SG_ 1505 BCM_Kompressorkupplung_Status 3;
BA_ "GenSigSendType" SG_ 2549088277 AB_KD_Fehler 0;
BA_ "GenSigSwitchedByIgnition" SG_ 2549088277 AB_KD_Fehler 0;
BA_ "GenSigSendType" SG_ 2549088277 Airbag_01_Abschaltstufe 0;
BA_ "GenSigSwitchedByIgnition" SG_ 2549088277 Airbag_01_Abschaltstufe 0;
BA_ "GenSigSendType" SG_ 2549088277 Airbag_01_KompSchutz 0;
BA_ "GenSigSwitchedByIgnition" SG_ 2549088277 Airbag_01_KompSchutz 0;
BA_ "GenSigSendType" SG_ 2549088277 Airbag_01_Nachlauftyp 0;
BA_ "GenSigStartValue" SG_ 2549088277 Airbag_01_Nachlauftyp 2;
BA_ "GenSigSwitchedByIgnition" SG_ 2549088277 Airbag_01_Nachlauftyp 0;
BA_ "GenSigSendType" SG_ 2549088277 Airbag_01_Transport_Mode 0;
BA_ "GenSigSwitchedByIgnition" SG_ 2549088277 Airbag_01_Transport_Mode 0;
BA_ "GenSigSendType" SG_ 2549088277 KN_AB_DiagPfad 0;
BA_ "GenSigSwitchedByIgnition" SG_ 2549088277 KN_AB_DiagPfad 0;
BA_ "GenSigSendType" SG_ 2549088277 NM_Airbag_01_Wakeup 0;
BA_ "NWM-WakeupAllowed" SG_ 2549088277 NM_Airbag_01_Wakeup 1;
BA_ "GenSigSwitchedByIgnition" SG_ 2549088277 NM_Airbag_01_Wakeup 0;
BA_ "GenSigSendType" SG_ 2549088380 EM_HYB_KD_Fehler 0;
BA_ "GenSigSwitchedByIgnition" SG_ 2549088380 EM_HYB_KD_Fehler 0;
BA_ "GenSigSendType" SG_ 2549088380 EMotor_01_Abschaltstufe 0;
BA_ "GenSigSwitchedByIgnition" SG_ 2549088380 EMotor_01_Abschaltstufe 0;
BA_ "GenSigSendType" SG_ 2549088380 EMotor_01_Transport_Mode 0;
BA_ "GenSigSwitchedByIgnition" SG_ 2549088380 EMotor_01_Transport_Mode 0;
BA_ "GenSigSendType" SG_ 2549088380 EMotor_KompSchutz 0;
BA_ "GenSigSwitchedByIgnition" SG_ 2549088380 EMotor_KompSchutz 0;
BA_ "GenSigSendType" SG_ 2549088380 EMotor_Nachlauftyp 0;
BA_ "GenSigStartValue" SG_ 2549088380 EMotor_Nachlauftyp 2;
BA_ "GenSigSwitchedByIgnition" SG_ 2549088380 EMotor_Nachlauftyp 0;
BA_ "GenSigSendType" SG_ 2549088380 KN_EM_HYB_DiagPfad 0;
BA_ "GenSigSwitchedByIgnition" SG_ 2549088380 KN_EM_HYB_DiagPfad 0;
BA_ "GenSigSendType" SG_ 2549088380 NM_EMotor_01_Wakeup 0;
BA_ "NWM-WakeupAllowed" SG_ 2549088380 NM_EMotor_01_Wakeup 1;
BA_ "GenSigSwitchedByIgnition" SG_ 2549088380 NM_EMotor_01_Wakeup 0;
BA_ "GenSigSendType" SG_ 2549088272 Gateway_Abschaltstufe 0;
BA_ "GenSigSwitchedByIgnition" SG_ 2549088272 Gateway_Abschaltstufe 0;
BA_ "GenSigSendType" SG_ 2549088272 Gateway_KompSchutz 0;
BA_ "GenSigSwitchedByIgnition" SG_ 2549088272 Gateway_KompSchutz 0;
BA_ "GenSigSendType" SG_ 2549088272 Gateway_Nachlauftyp 0;
BA_ "GenSigStartValue" SG_ 2549088272 Gateway_Nachlauftyp 2;
BA_ "GenSigSwitchedByIgnition" SG_ 2549088272 Gateway_Nachlauftyp 0;
BA_ "GenSigSendType" SG_ 2549088272 Gateway_Transport_Mode 0;
BA_ "GenSigSwitchedByIgnition" SG_ 2549088272 Gateway_Transport_Mode 0;
BA_ "GenSigSendType" SG_ 2549088272 GW_KD_Fehler 0;
BA_ "GenSigSendType" SG_ 2549088272 KN_GW_DiagPfad 0;
BA_ "GenSigSwitchedByIgnition" SG_ 2549088272 KN_GW_DiagPfad 0;
BA_ "GenSigSendType" SG_ 2549088272 NM_Gateway_Wakeup 0;
BA_ "NWM-WakeupAllowed" SG_ 2549088272 NM_Gateway_Wakeup 1;
BA_ "GenSigSwitchedByIgnition" SG_ 2549088272 NM_Gateway_Wakeup 0;
BA_ "GenSigSendType" SG_ 2549088440 KN_LE2_DiagPfad 0;
BA_ "GenSigSwitchedByIgnition" SG_ 2549088440 KN_LE2_DiagPfad 0;
BA_ "GenSigSendType" SG_ 2549088440 LE2_Abschaltstufe 0;
BA_ "GenSigSwitchedByIgnition" SG_ 2549088440 LE2_Abschaltstufe 0;
BA_ "GenSigSendType" SG_ 2549088440 LE2_KD_Fehler 0;
BA_ "GenSigSwitchedByIgnition" SG_ 2549088440 LE2_KD_Fehler 0;
BA_ "GenSigSendType" SG_ 2549088440 LE2_KompSchutz 0;
BA_ "GenSigSwitchedByIgnition" SG_ 2549088440 LE2_KompSchutz 0;
BA_ "GenSigSendType" SG_ 2549088440 LE2_Nachlauftyp 0;
BA_ "GenSigStartValue" SG_ 2549088440 LE2_Nachlauftyp 2;
BA_ "GenSigSwitchedByIgnition" SG_ 2549088440 LE2_Nachlauftyp 0;
BA_ "GenSigSendType" SG_ 2549088440 LE2_Transport_Mode 0;
BA_ "GenSigSwitchedByIgnition" SG_ 2549088440 LE2_Transport_Mode 0;
BA_ "GenSigSendType" SG_ 2549088440 NM_LE2_Wakeup 0;
BA_ "NWM-WakeupAllowed" SG_ 2549088440 NM_LE2_Wakeup 1;
BA_ "GenSigSwitchedByIgnition" SG_ 2549088440 NM_LE2_Wakeup 0;
BA_ "GenSigSendType" SG_ 2549088374 KN_MO_DiagPfad 0;
BA_ "GenSigSwitchedByIgnition" SG_ 2549088374 KN_MO_DiagPfad 0;
BA_ "GenSigSendType" SG_ 2549088374 KN_Motor_BusKnockOut 0;
BA_ "GenSigSwitchedByIgnition" SG_ 2549088374 KN_Motor_BusKnockOut 0;
BA_ "GenSigSendType" SG_ 2549088374 KN_Motor_BusKnockOutTimer 0;
BA_ "GenSigSwitchedByIgnition" SG_ 2549088374 KN_Motor_BusKnockOutTimer 0;
BA_ "GenSigSendType" SG_ 2549088374 KN_Motor_ECUKnockOut 0;
BA_ "GenSigSwitchedByIgnition" SG_ 2549088374 KN_Motor_ECUKnockOut 0;
BA_ "GenSigSendType" SG_ 2549088374 KN_Motor_ECUKnockOutTimer 0;
BA_ "GenSigSwitchedByIgnition" SG_ 2549088374 KN_Motor_ECUKnockOutTimer 0;
BA_ "GenSigSendType" SG_ 2549088374 MO_01_Abschaltstufe 0;
BA_ "GenSigSwitchedByIgnition" SG_ 2549088374 MO_01_Abschaltstufe 0;
BA_ "GenSigSendType" SG_ 2549088374 MO_01_Transport_Mode 0;
BA_ "GenSigSwitchedByIgnition" SG_ 2549088374 MO_01_Transport_Mode 0;
BA_ "GenSigSendType" SG_ 2549088374 MO_KD_Fehler 0;
BA_ "GenSigSwitchedByIgnition" SG_ 2549088374 MO_KD_Fehler 0;
BA_ "GenSigSendType" SG_ 2549088374 Motor_KompSchutz 0;
BA_ "GenSigSwitchedByIgnition" SG_ 2549088374 Motor_KompSchutz 0;
BA_ "GenSigSendType" SG_ 2549088374 Motor_Nachlauftyp 0;
BA_ "GenSigStartValue" SG_ 2549088374 Motor_Nachlauftyp 2;
BA_ "GenSigSwitchedByIgnition" SG_ 2549088374 Motor_Nachlauftyp 0;
BA_ "GenSigSendType" SG_ 2549088374 NM_MO_01_Wakeup 0;
BA_ "NWM-WakeupAllowed" SG_ 2549088374 NM_MO_01_Wakeup 1;
BA_ "GenSigSwitchedByIgnition" SG_ 2549088374 NM_MO_01_Wakeup 0;
BA_ "GenSigFuncType" SG_ 2621440277 KS_Airbag_01_Req_FD_Data 9;
BA_ "GenSigSwitchedByIgnition" SG_ 2621440277 KS_Airbag_01_Req_FD_Data 0;
BA_ "GenSigFuncType" SG_ 2621571349 KS_Airbag_01_Resp_FD_Data 9;
BA_ "GenSigSwitchedByIgnition" SG_ 2621571349 KS_Airbag_01_Resp_FD_Data 0;
BA_ "GenSigSendType" SG_ 982 BRL_als_SHL 3;
BA_ "GenSigSwitchedByIgnition" SG_ 982 BRL_als_SHL 0;
BA_ "GenSigSendType" SG_ 982 LH_3_Bremsl_def 0;
BA_ "GenSigSwitchedByIgnition" SG_ 982 LH_3_Bremsl_def 0;
BA_ "GenSigSendType" SG_ 982 LH_Aussenlicht_def 0;
BA_ "GenSigSwitchedByIgnition" SG_ 982 LH_Aussenlicht_def 0;
BA_ "GenSigSendType" SG_ 982 LH_Blinker_HL_akt 0;
BA_ "GenSigSwitchedByIgnition" SG_ 982 LH_Blinker_HL_akt 0;
BA_ "GenSigSendType" SG_ 982 LH_Blinker_HR_akt 0;
BA_ "GenSigSwitchedByIgnition" SG_ 982 LH_Blinker_HR_akt 0;
BA_ "GenSigSendType" SG_ 982 LH_Blinker_li_def 0;
BA_ "GenSigSwitchedByIgnition" SG_ 982 LH_Blinker_li_def 0;
BA_ "GenSigSendType" SG_ 982 LH_Blinker_re_def 0;
BA_ "GenSigSwitchedByIgnition" SG_ 982 LH_Blinker_re_def 0;
BA_ "GenSigSendType" SG_ 982 LH_Brems_Blk_li_def 0;
BA_ "GenSigSwitchedByIgnition" SG_ 982 LH_Brems_Blk_li_def 0;
BA_ "GenSigSendType" SG_ 982 LH_Brems_Blk_re_def 0;
BA_ "GenSigSwitchedByIgnition" SG_ 982 LH_Brems_Blk_re_def 0;
BA_ "GenSigSendType" SG_ 982 LH_Bremsl_li_def 0;
BA_ "GenSigSwitchedByIgnition" SG_ 982 LH_Bremsl_li_def 0;
BA_ "GenSigSendType" SG_ 982 LH_Bremsl_li_ges_def 0;
BA_ "GenSigSwitchedByIgnition" SG_ 982 LH_Bremsl_li_ges_def 0;
BA_ "GenSigSendType" SG_ 982 LH_Bremsl_mi_def 0;
BA_ "GenSigSwitchedByIgnition" SG_ 982 LH_Bremsl_mi_def 0;
BA_ "GenSigSendType" SG_ 982 LH_Bremsl_re_def 0;
BA_ "GenSigSwitchedByIgnition" SG_ 982 LH_Bremsl_re_def 0;
BA_ "GenSigSendType" SG_ 982 LH_Bremsl_re_ges_def 0;
BA_ "GenSigSwitchedByIgnition" SG_ 982 LH_Bremsl_re_ges_def 0;
BA_ "GenSigSendType" SG_ 982 LH_Bremslicht_H_aktiv 0;
BA_ "GenSigSwitchedByIgnition" SG_ 982 LH_Bremslicht_H_aktiv 0;
BA_ "GenSigSendType" SG_ 982 LH_Diag_LED_li_def 0;
BA_ "GenSigSwitchedByIgnition" SG_ 982 LH_Diag_LED_li_def 0;
BA_ "GenSigSendType" SG_ 982 LH_Diag_LED_re_def 0;
BA_ "GenSigSwitchedByIgnition" SG_ 982 LH_Diag_LED_re_def 0;
BA_ "GenSigSendType" SG_ 982 LH_Diag_Status_li_def 0;
BA_ "GenSigSwitchedByIgnition" SG_ 982 LH_Diag_Status_li_def 0;
BA_ "GenSigSendType" SG_ 982 LH_Diag_Status_re_def 0;
BA_ "GenSigSwitchedByIgnition" SG_ 982 LH_Diag_Status_re_def 0;
BA_ "GenSigSendType" SG_ 982 LH_Kennzl_def 0;
BA_ "GenSigSwitchedByIgnition" SG_ 982 LH_Kennzl_def 0;
BA_ "GenSigSendType" SG_ 982 LH_Nebel_li_def 0;
BA_ "GenSigSwitchedByIgnition" SG_ 982 LH_Nebel_li_def 0;
BA_ "GenSigSendType" SG_ 982 LH_Nebel_mi_def 0;
BA_ "GenSigSwitchedByIgnition" SG_ 982 LH_Nebel_mi_def 0;
BA_ "GenSigSendType" SG_ 982 LH_Nebel_re_def 0;
BA_ "GenSigSwitchedByIgnition" SG_ 982 LH_Nebel_re_def 0;
BA_ "GenSigSendType" SG_ 982 LH_Nebelschluss_aktiv 0;
BA_ "GenSigSwitchedByIgnition" SG_ 982 LH_Nebelschluss_aktiv 0;
BA_ "GenSigSendType" SG_ 982 LH_Parklicht_HL_aktiv 0;
BA_ "GenSigSwitchedByIgnition" SG_ 982 LH_Parklicht_HL_aktiv 0;
BA_ "GenSigSendType" SG_ 982 LH_Parklicht_HR_aktiv 0;
BA_ "GenSigSwitchedByIgnition" SG_ 982 LH_Parklicht_HR_aktiv 0;
BA_ "GenSigSendType" SG_ 982 LH_Rueckf_li_def 0;
BA_ "GenSigSwitchedByIgnition" SG_ 982 LH_Rueckf_li_def 0;
BA_ "GenSigSendType" SG_ 982 LH_Rueckf_mi_def 0;
BA_ "GenSigSwitchedByIgnition" SG_ 982 LH_Rueckf_mi_def 0;
BA_ "GenSigSendType" SG_ 982 LH_Rueckf_re_def 0;
BA_ "GenSigSwitchedByIgnition" SG_ 982 LH_Rueckf_re_def 0;
BA_ "GenSigSendType" SG_ 982 LH_Rueckfahrlicht_aktiv 0;
BA_ "GenSigSwitchedByIgnition" SG_ 982 LH_Rueckfahrlicht_aktiv 0;
BA_ "GenSigSendType" SG_ 982 LH_Schluss_Brems_li_def 0;
BA_ "GenSigSwitchedByIgnition" SG_ 982 LH_Schluss_Brems_li_def 0;
BA_ "GenSigSendType" SG_ 982 LH_Schluss_Brems_mi_def 0;
BA_ "GenSigSwitchedByIgnition" SG_ 982 LH_Schluss_Brems_mi_def 0;
BA_ "GenSigSendType" SG_ 982 LH_Schluss_Brems_Nebel_li_def 0;
BA_ "GenSigSwitchedByIgnition" SG_ 982 LH_Schluss_Brems_Nebel_li_def 0;
BA_ "GenSigSendType" SG_ 982 LH_Schluss_Brems_Nebel_re_def 0;
BA_ "GenSigSwitchedByIgnition" SG_ 982 LH_Schluss_Brems_Nebel_re_def 0;
BA_ "GenSigSendType" SG_ 982 LH_Schluss_Brems_re_def 0;
BA_ "GenSigSwitchedByIgnition" SG_ 982 LH_Schluss_Brems_re_def 0;
BA_ "GenSigSendType" SG_ 982 LH_Schluss_Nebel_li_def 0;
BA_ "GenSigSwitchedByIgnition" SG_ 982 LH_Schluss_Nebel_li_def 0;
BA_ "GenSigSendType" SG_ 982 LH_Schluss_Nebel_re_def 0;
BA_ "GenSigSwitchedByIgnition" SG_ 982 LH_Schluss_Nebel_re_def 0;
BA_ "GenSigSendType" SG_ 982 LH_Schlusslicht_li_def 0;
BA_ "GenSigSwitchedByIgnition" SG_ 982 LH_Schlusslicht_li_def 0;
BA_ "GenSigSendType" SG_ 982 LH_Schlusslicht_mi_def 0;
BA_ "GenSigSwitchedByIgnition" SG_ 982 LH_Schlusslicht_mi_def 0;
BA_ "GenSigSendType" SG_ 982 LH_Schlusslicht_re_def 0;
BA_ "GenSigSwitchedByIgnition" SG_ 982 LH_Schlusslicht_re_def 0;
BA_ "GenSigSendType" SG_ 982 LH_SL_BRL_BLK_li_def 0;
BA_ "GenSigSwitchedByIgnition" SG_ 982 LH_SL_BRL_BLK_li_def 0;
BA_ "GenSigSendType" SG_ 982 LH_SL_BRL_BLK_re_def 0;
BA_ "GenSigSwitchedByIgnition" SG_ 982 LH_SL_BRL_BLK_re_def 0;
BA_ "GenSigSendType" SG_ 982 LH_Standlicht_H_aktiv 0;
BA_ "GenSigSwitchedByIgnition" SG_ 982 LH_Standlicht_H_aktiv 0;
BA_ "GenSigSendType" SG_ 982 LH_Zusatzschlussl_def 0;
BA_ "GenSigSwitchedByIgnition" SG_ 982 LH_Zusatzschlussl_def 0;
BA_ "GenSigSendType" SG_ 982 Licht_hinten_01_BZ 0;
BA_ "GenSigFuncType" SG_ 982 Licht_hinten_01_BZ 1;
BA_ "GenSigSwitchedByIgnition" SG_ 982 Licht_hinten_01_BZ 0;
BA_ "GenSigSendType" SG_ 134 LWI_01_BZ 0;
BA_ "GenSigFuncType" SG_ 134 LWI_01_BZ 1;
BA_ "GenSigSendType" SG_ 134 LWI_01_CRC 0;
BA_ "GenSigFuncType" SG_ 134 LWI_01_CRC 2;
BA_ "GenSigSwitchedByIgnition" SG_ 134 LWI_01_CRC 0;
BA_ "GenSigSendType" SG_ 134 LWI_Lenkradw_Geschw 0;
BA_ "GenSigStartValue" SG_ 134 LWI_Lenkradw_Geschw 510;
BA_ "Fehlerwert" SG_ 134 LWI_Lenkradw_Geschw 511;
BA_ "GenSigSendType" SG_ 134 LWI_Lenkradwinkel 0;
BA_ "GenSigStartValue" SG_ 134 LWI_Lenkradwinkel 8190;
BA_ "Fehlerwert" SG_ 134 LWI_Lenkradwinkel 8191;
BA_ "GenSigSendType" SG_ 134 LWI_QBit_Lenkradwinkel 0;
BA_ "GenSigStartValue" SG_ 134 LWI_QBit_Lenkradwinkel 1;
BA_ "GenSigSendType" SG_ 134 LWI_QBit_Sub_Daten 0;
BA_ "GenSigSendType" SG_ 134 LWI_Sensorstatus 0;
BA_ "GenSigSendType" SG_ 134 LWI_Sub_Daten 0;
BA_ "GenSigSendType" SG_ 134 LWI_VZ_Lenkradw_Geschw 0;
BA_ "GenSigSendType" SG_ 134 LWI_VZ_Lenkradwinkel 0;
BA_ "GenSigSendType" SG_ 817 MFL_Dummy_0_Signal_1 0;
BA_ "GenSigSwitchedByIgnition" SG_ 817 MFL_Dummy_0_Signal_1 0;
BA_ "GenSigSendType" SG_ 817 MFL_Dummy_0_Signal_2 0;
BA_ "GenSigSwitchedByIgnition" SG_ 817 MFL_Dummy_0_Signal_2 0;
BA_ "GenSigSendType" SG_ 817 MFL_Dummy_0_Signal_3 0;
BA_ "GenSigSwitchedByIgnition" SG_ 817 MFL_Dummy_0_Signal_3 0;
BA_ "GenSigSendType" SG_ 817 MFL_ECU_Err 0;
BA_ "GenSigSwitchedByIgnition" SG_ 817 MFL_ECU_Err 0;
BA_ "Fehlerwert" SG_ 817 MFL_ECU_Err 1;
BA_ "GenSigSendType" SG_ 817 MFL_Eventcode_1 0;
BA_ "GenSigSwitchedByIgnition" SG_ 817 MFL_Eventcode_1 0;
BA_ "GenSigSendType" SG_ 817 MFL_Eventcode_2 0;
BA_ "GenSigSwitchedByIgnition" SG_ 817 MFL_Eventcode_2 0;
BA_ "GenSigSendType" SG_ 817 MFL_Lokalaktiv 0;
BA_ "GenSigSwitchedByIgnition" SG_ 817 MFL_Lokalaktiv 0;
BA_ "GenSigSendType" SG_ 817 MFL_LR_HZG_Err 0;
BA_ "GenSigSwitchedByIgnition" SG_ 817 MFL_LR_HZG_Err 0;
BA_ "Fehlerwert" SG_ 817 MFL_LR_HZG_Err 1;
BA_ "GenSigSendType" SG_ 817 MFL_LR_HZG_Status 0;
BA_ "GenSigSwitchedByIgnition" SG_ 817 MFL_LR_HZG_Status 0;
BA_ "GenSigSendType" SG_ 817 MFL_M_Taste 0;
BA_ "GenSigSendType" SG_ 817 MFL_Marke 0;
BA_ "GenSigFuncType" SG_ 817 MFL_Marke 8;
BA_ "GenSigSwitchedByIgnition" SG_ 817 MFL_Marke 0;
BA_ "GenSigSendType" SG_ 817 MFL_Paddle_Verbau 0;
BA_ "GenSigSwitchedByIgnition" SG_ 817 MFL_Paddle_Verbau 0;
BA_ "GenSigSendType" SG_ 817 MFL_Response_Err 0;
BA_ "GenSigSwitchedByIgnition" SG_ 817 MFL_Response_Err 0;
BA_ "Fehlerwert" SG_ 817 MFL_Response_Err 1;
BA_ "GenSigSendType" SG_ 817 MFL_SatModul_links_Err 0;
BA_ "GenSigFuncType" SG_ 817 MFL_SatModul_links_Err 5;
BA_ "GenSigSwitchedByIgnition" SG_ 817 MFL_SatModul_links_Err 0;
BA_ "Fehlerwert" SG_ 817 MFL_SatModul_links_Err 1;
BA_ "GenSigSendType" SG_ 817 MFL_SatModul_rechts_Err 0;
BA_ "GenSigFuncType" SG_ 817 MFL_SatModul_rechts_Err 5;
BA_ "GenSigSwitchedByIgnition" SG_ 817 MFL_SatModul_rechts_Err 0;
BA_ "Fehlerwert" SG_ 817 MFL_SatModul_rechts_Err 1;
BA_ "GenSigSendType" SG_ 817 MFL_Signalhorn 5;
BA_ "GenSigSwitchedByIgnition" SG_ 817 MFL_Signalhorn 0;
BA_ "GenSigSendType" SG_ 817 MFL_Signalhorn_Err 0;
BA_ "GenSigSwitchedByIgnition" SG_ 817 MFL_Signalhorn_Err 0;
BA_ "Fehlerwert" SG_ 817 MFL_Signalhorn_Err 1;
BA_ "GenSigSendType" SG_ 817 MFL_Taste_links_Err 0;
BA_ "GenSigSwitchedByIgnition" SG_ 817 MFL_Taste_links_Err 0;
BA_ "Fehlerwert" SG_ 817 MFL_Taste_links_Err 1;
BA_ "GenSigSendType" SG_ 817 MFL_Taste_rechts_Err 0;
BA_ "GenSigSwitchedByIgnition" SG_ 817 MFL_Taste_rechts_Err 0;
BA_ "Fehlerwert" SG_ 817 MFL_Taste_rechts_Err 1;
BA_ "GenSigSendType" SG_ 817 MFL_Tastencode_1 0;
BA_ "GenSigSwitchedByIgnition" SG_ 817 MFL_Tastencode_1 0;
BA_ "GenSigSendType" SG_ 817 MFL_Tastencode_2 0;
BA_ "GenSigSwitchedByIgnition" SG_ 817 MFL_Tastencode_2 0;
BA_ "GenSigSendType" SG_ 817 MFL_Tip_Down 5;
BA_ "GenSigSendType" SG_ 817 MFL_Tip_links_Err 0;
BA_ "GenSigSwitchedByIgnition" SG_ 817 MFL_Tip_links_Err 0;
BA_ "Fehlerwert" SG_ 817 MFL_Tip_links_Err 1;
BA_ "GenSigSendType" SG_ 817 MFL_Tip_rechts_Err 0;
BA_ "GenSigSwitchedByIgnition" SG_ 817 MFL_Tip_rechts_Err 0;
BA_ "Fehlerwert" SG_ 817 MFL_Tip_rechts_Err 1;
BA_ "GenSigSendType" SG_ 817 MFL_Tip_Up 5;
BA_ "GenSigSendType" SG_ 817 MFL_Toggle 0;
BA_ "GenSigSwitchedByIgnition" SG_ 817 MFL_Toggle 0;
BA_ "GenSigSendType" SG_ 817 MFL_Variante 0;
BA_ "GenSigFuncType" SG_ 817 MFL_Variante 8;
BA_ "GenSigSwitchedByIgnition" SG_ 817 MFL_Variante 0;
BA_ "GenSigSendType" SG_ 817 MFL_Zaehler 0;
BA_ "GenSigSwitchedByIgnition" SG_ 817 MFL_Zaehler 0;
BA_ "GenSigSendType" SG_ 15 MO_SOPC 5;
BA_ "GenSigSwitchedByIgnition" SG_ 15 MO_SOPC 0;
BA_ "GenSigSendType" SG_ 1600 MO_Absperrventil_oeffnen 0;
BA_ "GenSigSwitchedByIgnition" SG_ 1600 MO_Absperrventil_oeffnen 0;
BA_ "GenSigSendType" SG_ 1600 MO_aktives_Getriebeheizen 0;
BA_ "GenSigSwitchedByIgnition" SG_ 1600 MO_aktives_Getriebeheizen 0;
BA_ "GenSigSendType" SG_ 1600 MO_Ansaugluft_Temp 0;
BA_ "GenSigStartValue" SG_ 1600 MO_Ansaugluft_Temp 254;
BA_ "GenSigSwitchedByIgnition" SG_ 1600 MO_Ansaugluft_Temp 0;
BA_ "Fehlerwert" SG_ 1600 MO_Ansaugluft_Temp 255;
BA_ "GenSigSendType" SG_ 1600 MO_Getriebe_kuehlen 0;
BA_ "GenSigSwitchedByIgnition" SG_ 1600 MO_Getriebe_kuehlen 0;
BA_ "GenSigSendType" SG_ 1600 MO_Heizungspumpenansteuerung 0;
BA_ "GenSigStartValue" SG_ 1600 MO_Heizungspumpenansteuerung 14;
BA_ "GenSigSwitchedByIgnition" SG_ 1600 MO_Heizungspumpenansteuerung 0;
BA_ "Fehlerwert" SG_ 1600 MO_Heizungspumpenansteuerung 13;
BA_ "GenSigSendType" SG_ 1600 MO_Hoeheninfo 0;
BA_ "GenSigSwitchedByIgnition" SG_ 1600 MO_Hoeheninfo 0;
BA_ "Fehlerwert" SG_ 1600 MO_Hoeheninfo 255;
BA_ "GenSigSendType" SG_ 1600 MO_HYB_Fehler_HV_Netz 0;
BA_ "GenSigSwitchedByIgnition" SG_ 1600 MO_HYB_Fehler_HV_Netz 0;
BA_ "GenSigSendType" SG_ 1600 MO_Kennfeldk 0;
BA_ "GenSigSwitchedByIgnition" SG_ 1600 MO_Kennfeldk 0;
BA_ "GenSigSendType" SG_ 1600 MO_KL15_Abschaltempfehlung 0;
BA_ "GenSigSwitchedByIgnition" SG_ 1600 MO_KL15_Abschaltempfehlung 0;
BA_ "GenSigSendType" SG_ 1600 MO_Kuehlmittel_Temp 0;
BA_ "GenSigStartValue" SG_ 1600 MO_Kuehlmittel_Temp 254;
BA_ "GenSigSwitchedByIgnition" SG_ 1600 MO_Kuehlmittel_Temp 0;
BA_ "Fehlerwert" SG_ 1600 MO_Kuehlmittel_Temp 255;
BA_ "GenSigSendType" SG_ 1600 MO_Mom_Traegheit_02 0;
BA_ "GenSigSwitchedByIgnition" SG_ 1600 MO_Mom_Traegheit_02 0;
BA_ "GenSigSendType" SG_ 1600 MO_Nachlaufzeit_Heizungspumpe 0;
BA_ "GenSigSwitchedByIgnition" SG_ 1600 MO_Nachlaufzeit_Heizungspumpe 0;
BA_ "GenSigSendType" SG_ 1600 MO_Oel_Temp 0;
BA_ "GenSigStartValue" SG_ 1600 MO_Oel_Temp 254;
BA_ "GenSigSwitchedByIgnition" SG_ 1600 MO_Oel_Temp 0;
BA_ "Fehlerwert" SG_ 1600 MO_Oel_Temp 255;
BA_ "GenSigSendType" SG_ 1600 MO_QBit_Ansaugluft_Temp 0;
BA_ "GenSigStartValue" SG_ 1600 MO_QBit_Ansaugluft_Temp 1;
BA_ "GenSigSwitchedByIgnition" SG_ 1600 MO_QBit_Ansaugluft_Temp 0;
BA_ "GenSigSendType" SG_ 1600 MO_QBit_Hoeheninfo 0;
BA_ "GenSigStartValue" SG_ 1600 MO_QBit_Hoeheninfo 1;
BA_ "GenSigSwitchedByIgnition" SG_ 1600 MO_QBit_Hoeheninfo 0;
BA_ "GenSigSendType" SG_ 1600 MO_QBit_Kuehlmittel_Temp 0;
BA_ "GenSigStartValue" SG_ 1600 MO_QBit_Kuehlmittel_Temp 1;
BA_ "GenSigSwitchedByIgnition" SG_ 1600 MO_QBit_Kuehlmittel_Temp 0;
BA_ "GenSigSendType" SG_ 1600 MO_QBit_Oel_Temp 0;
BA_ "GenSigStartValue" SG_ 1600 MO_QBit_Oel_Temp 1;
BA_ "GenSigSwitchedByIgnition" SG_ 1600 MO_QBit_Oel_Temp 0;
BA_ "GenSigSendType" SG_ 1600 MO_SpannungsAnf 0;
BA_ "GenSigSwitchedByIgnition" SG_ 1600 MO_SpannungsAnf 0;
BA_ "GenSigSendType" SG_ 1600 MO_Versionsinfo_02 0;
BA_ "GenSigSwitchedByIgnition" SG_ 1600 MO_Versionsinfo_02 0;
BA_ "GenSigSendType" SG_ 167 MO_erste_Ungenauschwelle 0;
BA_ "GenSigSwitchedByIgnition" SG_ 167 MO_erste_Ungenauschwelle 0;
BA_ "GenSigSendType" SG_ 167 MO_Mom_Ist_Summe 0;
BA_ "GenSigStartValue" SG_ 167 MO_Mom_Ist_Summe 1022;
BA_ "GenSigSwitchedByIgnition" SG_ 167 MO_Mom_Ist_Summe 0;
BA_ "GenSigSendType" SG_ 167 MO_Mom_Schub 0;
BA_ "GenSigStartValue" SG_ 167 MO_Mom_Schub 510;
BA_ "GenSigSwitchedByIgnition" SG_ 167 MO_Mom_Schub 0;
BA_ "GenSigSendType" SG_ 167 MO_Mom_Soll_gefiltert 0;
BA_ "GenSigStartValue" SG_ 167 MO_Mom_Soll_gefiltert 1022;
BA_ "GenSigSwitchedByIgnition" SG_ 167 MO_Mom_Soll_gefiltert 0;
BA_ "GenSigSendType" SG_ 167 MO_Mom_Soll_Roh 0;
BA_ "GenSigStartValue" SG_ 167 MO_Mom_Soll_Roh 1022;
BA_ "GenSigSwitchedByIgnition" SG_ 167 MO_Mom_Soll_Roh 0;
BA_ "GenSigSendType" SG_ 167 MO_Mom_Traegheit_Summe 0;
BA_ "GenSigStartValue" SG_ 167 MO_Mom_Traegheit_Summe 1022;
BA_ "GenSigSwitchedByIgnition" SG_ 167 MO_Mom_Traegheit_Summe 0;
BA_ "GenSigSendType" SG_ 167 MO_QBit_Motormomente 0;
BA_ "GenSigStartValue" SG_ 167 MO_QBit_Motormomente 1;
BA_ "GenSigSwitchedByIgnition" SG_ 167 MO_QBit_Motormomente 0;
BA_ "GenSigSendType" SG_ 167 MO_Status_Normalbetrieb_01 0;
BA_ "GenSigSwitchedByIgnition" SG_ 167 MO_Status_Normalbetrieb_01 0;
BA_ "GenSigSendType" SG_ 167 Motor_11_BZ 0;
BA_ "GenSigFuncType" SG_ 167 Motor_11_BZ 1;
BA_ "GenSigSwitchedByIgnition" SG_ 167 Motor_11_BZ 0;
BA_ "GenSigSendType" SG_ 167 Motor_11_CRC 0;
BA_ "GenSigFuncType" SG_ 167 Motor_11_CRC 2;
BA_ "GenSigSwitchedByIgnition" SG_ 167 Motor_11_CRC 0;
BA_ "GenSigSendType" SG_ 168 MO_Drehzahl_01 0;
BA_ "GenSigSwitchedByIgnition" SG_ 168 MO_Drehzahl_01 0;
BA_ "GenSigSendType" SG_ 168 MO_Mom_Begr_Fahr 0;
BA_ "GenSigStartValue" SG_ 168 MO_Mom_Begr_Fahr 510;
BA_ "GenSigSwitchedByIgnition" SG_ 168 MO_Mom_Begr_Fahr 0;
BA_ "Fehlerwert" SG_ 168 MO_Mom_Begr_Fahr 511;
BA_ "GenSigSendType" SG_ 168 MO_Mom_Begr_Schalt 0;
BA_ "GenSigStartValue" SG_ 168 MO_Mom_Begr_Schalt 1022;
BA_ "GenSigSwitchedByIgnition" SG_ 168 MO_Mom_Begr_Schalt 0;
BA_ "GenSigSendType" SG_ 168 MO_Mom_neg_verfuegbar 0;
BA_ "GenSigStartValue" SG_ 168 MO_Mom_neg_verfuegbar 510;
BA_ "GenSigSwitchedByIgnition" SG_ 168 MO_Mom_neg_verfuegbar 0;
BA_ "Fehlerwert" SG_ 168 MO_Mom_neg_verfuegbar 511;
BA_ "GenSigSendType" SG_ 168 MO_Momentenintegral_02 0;
BA_ "GenSigSwitchedByIgnition" SG_ 168 MO_Momentenintegral_02 0;
BA_ "GenSigSendType" SG_ 168 MO_QBit_Drehzahl_01 0;
BA_ "GenSigStartValue" SG_ 168 MO_QBit_Drehzahl_01 1;
BA_ "GenSigSwitchedByIgnition" SG_ 168 MO_QBit_Drehzahl_01 0;
BA_ "GenSigSendType" SG_ 168 Motor_12_BZ 0;
BA_ "GenSigFuncType" SG_ 168 Motor_12_BZ 1;
BA_ "GenSigSwitchedByIgnition" SG_ 168 Motor_12_BZ 0;
BA_ "GenSigSendType" SG_ 168 Motor_12_CRC 0;
BA_ "GenSigFuncType" SG_ 168 Motor_12_CRC 2;
BA_ "GenSigSwitchedByIgnition" SG_ 168 Motor_12_CRC 0;
BA_REL_ "GenSigTimeoutTime" BU_SG_REL_ Airbag SG_ 2527679684 Kamera_ASM_Ereignis 5000;
BA_REL_ "GenSigTimeoutTime" BU_SG_REL_ Airbag SG_ 2527679684 Kamera_ASM_Zeitstempel 5000;
BA_REL_ "GenSigTimeoutTime" BU_SG_REL_ Airbag SG_ 2527679684 Kamera_ASM_Data_1 5000;
BA_REL_ "GenSigTimeoutTime" BU_SG_REL_ Airbag SG_ 2527679684 Kamera_ASM_Data_2 5000;
BA_REL_ "GenSigTimeoutTime" BU_SG_REL_ Airbag SG_ 2527679684 Kamera_ASM_Data_3 5000;
BA_REL_ "GenSigTimeoutTime" BU_SG_REL_ Airbag SG_ 2527679684 Kamera_ASM_Data_4 5000;
BA_REL_ "GenSigTimeoutTime" BU_SG_REL_ Airbag SG_ 2527679684 Kamera_ASM_Data_5 5000;
BA_REL_ "GenSigTimeoutTime" BU_SG_REL_ Airbag SG_ 2527679684 Kamera_ASM_Data_6 5000;
BA_REL_ "GenSigTimeoutTime" BU_SG_REL_ Airbag SG_ 960 ZAS_Kl_15 1000;
BA_REL_ "GenSigTimeoutTime" BU_SG_REL_ Airbag SG_ 134 LWI_01_CRC 500;
BA_REL_ "GenSigTimeoutTime" BU_SG_REL_ Airbag SG_ 134 LWI_01_BZ 500;
BA_REL_ "GenSigTimeoutTime" BU_SG_REL_ Airbag SG_ 134 LWI_Sensorstatus 500;
BA_REL_ "GenSigTimeoutTime" BU_SG_REL_ Airbag SG_ 134 LWI_QBit_Lenkradwinkel 500;
BA_REL_ "GenSigTimeoutTime" BU_SG_REL_ Airbag SG_ 134 LWI_Lenkradwinkel 500;
BA_REL_ "GenSigTimeoutTime" BU_SG_REL_ Airbag SG_ 134 LWI_VZ_Lenkradwinkel 500;
BA_REL_ "GenSigTimeoutTime" BU_SG_REL_ Airbag SG_ 134 LWI_Lenkradw_Geschw 500;
BA_REL_ "GenSigTimeoutTime" BU_SG_REL_ Airbag SG_ 168 MO_QBit_Drehzahl_01 500;
BA_REL_ "GenSigTimeoutTime" BU_SG_REL_ ICAS1_Gateway SG_ 1283 HVK_BMS_Sollmodus 1000;
BA_REL_ "GenSigTimeoutTime" BU_SG_REL_ ICAS1_Gateway SG_ 1283 HVK_DCDC_Sollmodus 1000;
BA_REL_ "GenSigTimeoutTime" BU_SG_REL_ ICAS1_Gateway SG_ 1283 HVK_HVLM_Sollmodus 1000;
BA_REL_ "GenSigTimeoutTime" BU_SG_REL_ ICAS1_Gateway SG_ 1283 HV_Bordnetz_aktiv 1000;
BA_REL_ "GenSigTimeoutTime" BU_SG_REL_ ICAS1_Gateway SG_ 1283 HV_Bordnetz_Fehler 1000;
BA_REL_ "GenSigTimeoutTime" BU_SG_REL_ ICAS1_Gateway SG_ 1283 HVK_HVEM_Freigabe 1000;
BA_REL_ "GenSigTimeoutTime" BU_SG_REL_ ICAS1_Gateway SG_ 1283 HVK_Notentladung_Anf 1000;
BA_REL_ "GenSigTimeoutTime" BU_SG_REL_ ICAS1_Gateway SG_ 1283 HVK_Ladebereit 1000;
BA_REL_ "GenSigTimeoutTime" BU_SG_REL_ ICAS1_Gateway SG_ 1283 HVK_PPulsFreigabe 1000;
BA_REL_ "GenSigTimeoutTime" BU_SG_REL_ ICAS1_Gateway SG_ 2549088277 Airbag_01_Nachlauftyp 5000;
BA_REL_ "GenSigTimeoutTime" BU_SG_REL_ ICAS1_Gateway SG_ 2549088277 KN_AB_DiagPfad 5000;
BA_REL_ "GenSigTimeoutTime" BU_SG_REL_ ICAS1_Gateway SG_ 2549088277 AB_KD_Fehler 2500;
BA_REL_ "GenSigTimeoutTime" BU_SG_REL_ ICAS1_Gateway SG_ 2549088380 EMotor_Nachlauftyp 5000;
BA_REL_ "GenSigTimeoutTime" BU_SG_REL_ ICAS1_Gateway SG_ 2549088380 KN_EM_HYB_DiagPfad 5000;
BA_REL_ "GenSigTimeoutTime" BU_SG_REL_ ICAS1_Gateway SG_ 2549088380 EM_HYB_KD_Fehler 2500;
BA_REL_ "GenSigTimeoutTime" BU_SG_REL_ ICAS1_Gateway SG_ 2549088440 LE2_Nachlauftyp 5000;
BA_REL_ "GenSigTimeoutTime" BU_SG_REL_ ICAS1_Gateway SG_ 2549088440 KN_LE2_DiagPfad 5000;
BA_REL_ "GenSigTimeoutTime" BU_SG_REL_ ICAS1_Gateway SG_ 2549088440 LE2_KD_Fehler 2500;
BA_REL_ "GenSigTimeoutTime" BU_SG_REL_ ICAS1_Gateway SG_ 2549088374 Motor_Nachlauftyp 5000;
BA_REL_ "GenSigTimeoutTime" BU_SG_REL_ ICAS1_Gateway SG_ 2549088374 KN_MO_DiagPfad 5000;
BA_REL_ "GenSigTimeoutTime" BU_SG_REL_ ICAS1_Gateway SG_ 2549088374 MO_KD_Fehler 2500;
BA_REL_ "GenSigTimeoutTime" BU_SG_REL_ ICAS1_Gateway SG_ 167 MO_Mom_Ist_Summe 500;
BA_REL_ "GenSigTimeoutTime" BU_SG_REL_ ICAS1_Gateway SG_ 168 MO_QBit_Drehzahl_01 500;
BA_REL_ "GenSigTimeoutTime" BU_SG_REL_ ICAS1_KommunikationsServer SG_ 1283 HVK_HV_Netz_Warnungen 1000;
BA_REL_ "GenSigTimeoutTime" BU_SG_REL_ ICAS1_KommunikationsServer SG_ 1283 HVK_Gesamtst_Spgfreiheit 1000;
BA_REL_ "GenSigTimeoutTime" BU_SG_REL_ LE1 SG_ 1283 HVK_01_CRC 1000;
BA_REL_ "GenSigTimeoutTime" BU_SG_REL_ LE1 SG_ 1283 HVK_01_BZ 1000;
BA_REL_ "GenSigTimeoutTime" BU_SG_REL_ LE1 SG_ 1283 HV_Bordnetz_aktiv 1000;
BA_REL_ "GenSigTimeoutTime" BU_SG_REL_ LE1 SG_ 1283 HVK_AktiveEntladung_Anf 1000;
BA_REL_ "GenSigTimeoutTime" BU_SG_REL_ LE1 SG_ 1283 HVK_Notentladung_Anf 1000;
BA_REL_ "GenSigTimeoutTime" BU_SG_REL_ LE1 SG_ 2527679583 Parken_Wegfahrsperren_Anf 5000;
BA_REL_ "GenSigTimeoutTime" BU_SG_REL_ LE1 SG_ 2463978753 KST_WFS_Fahrfreigabe_Anforderung 5000;
BA_REL_ "GenSigTimeoutTime" BU_SG_REL_ LE1 SG_ 2463978753 KST_Sonderzustand_Status 5000;
BA_REL_ "GenSigTimeoutTime" BU_SG_REL_ LE1 SG_ 2463978753 KST_Sonderzustand_Anforderung 5000;
BA_REL_ "GenSigTimeoutTime" BU_SG_REL_ LE1 SG_ 960 ZAS_Kl_15 1000;
BA_REL_ "GenSigTimeoutTime" BU_SG_REL_ LE1 SG_ 1505 BCM1_Aussen_Temp_ungef 2000;
BA_REL_ "GenSigTimeoutTime" BU_SG_REL_ LE2 SG_ 1283 HVK_01_CRC 1000;
BA_REL_ "GenSigTimeoutTime" BU_SG_REL_ LE2 SG_ 1283 HVK_01_BZ 1000;
BA_REL_ "GenSigTimeoutTime" BU_SG_REL_ LE2 SG_ 1283 HV_Bordnetz_aktiv 1000;
BA_REL_ "GenSigTimeoutTime" BU_SG_REL_ LE2 SG_ 1283 HVK_AktiveEntladung_Anf 1000;
BA_REL_ "GenSigTimeoutTime" BU_SG_REL_ LE2 SG_ 1283 HVK_Notentladung_Anf 1000;
BA_REL_ "GenSigTimeoutTime" BU_SG_REL_ LE2 SG_ 2527679583 Parken_Wegfahrsperren_Anf 5000;
BA_REL_ "GenSigTimeoutTime" BU_SG_REL_ LE2 SG_ 2463978753 KST_WFS_Fahrfreigabe_Anforderung 5000;
BA_REL_ "GenSigTimeoutTime" BU_SG_REL_ LE2 SG_ 2463978753 KST_Sonderzustand_Status 5000;
BA_REL_ "GenSigTimeoutTime" BU_SG_REL_ LE2 SG_ 2463978753 KST_Sonderzustand_Anforderung 5000;
BA_REL_ "GenSigTimeoutTime" BU_SG_REL_ LE2 SG_ 960 ZAS_Kl_15 1000;
BA_REL_ "GenSigTimeoutTime" BU_SG_REL_ LE2 SG_ 1505 BCM1_Aussen_Temp_ungef 2000;
BA_REL_ "GenSigTimeoutTime" BU_SG_REL_ LE2 SG_ 168 MO_QBit_Drehzahl_01 500;
BA_REL_ "GenSigTimeoutTime" BU_SG_REL_ Motor_BEV SG_ 1452 HVEM_IstLeistungNA 1000;
BA_REL_ "GenSigTimeoutTime" BU_SG_REL_ Motor_BEV SG_ 1452 HVEM_HVK_Aktivitaet 1000;
BA_REL_ "GenSigTimeoutTime" BU_SG_REL_ Motor_BEV SG_ 1452 HVEM_Pruefpuls_Anf 1000;
BA_REL_ "GenSigTimeoutTime" BU_SG_REL_ Motor_BEV SG_ 1452 HVEM_HV_Anf 1000;
BA_REL_ "GenSigTimeoutTime" BU_SG_REL_ Motor_BEV SG_ 1385 HVEM_DCDC_Freigabe 5000;
BA_REL_ "GenSigTimeoutTime" BU_SG_REL_ Motor_BEV SG_ 2463978813 HVL_01_CRC 1000;
BA_REL_ "GenSigTimeoutTime" BU_SG_REL_ Motor_BEV SG_ 2463978813 HVL_01_BZ 1000;
BA_REL_ "GenSigTimeoutTime" BU_SG_REL_ Motor_BEV SG_ 2463978813 HVL_Steckerstatus 1000;
BA_REL_ "GenSigTimeoutTime" BU_SG_REL_ Motor_BEV SG_ 2463978813 HVL_LadeAnforderung 1000;
BA_REL_ "GenSigTimeoutTime" BU_SG_REL_ Motor_BEV SG_ 626 HVLM_AWC_VerbautStatus 1000;
BA_REL_ "GenSigTimeoutTime" BU_SG_REL_ Motor_BEV SG_ 626 HVLM_Steckerstatus_A 1000;
BA_REL_ "GenSigTimeoutTime" BU_SG_REL_ Motor_BEV SG_ 626 HVLM_ZustandLadeablauf 1000;
BA_REL_ "GenSigTimeoutTime" BU_SG_REL_ Motor_BEV SG_ 626 HVLM_DC_Aufstartmodus 1000;
BA_REL_ "GenSigTimeoutTime" BU_SG_REL_ Motor_BEV SG_ 626 HVLM_Ladevorgang_Anf 1000;
BA_REL_ "GenSigTimeoutTime" BU_SG_REL_ Motor_BEV SG_ 626 HVLM_Laden_ISO_Messung_Anf 1000;
BA_REL_ "GenSigTimeoutTime" BU_SG_REL_ Motor_BEV SG_ 960 Klemmen_Status_01_CRC 1000;
BA_REL_ "GenSigTimeoutTime" BU_SG_REL_ Motor_BEV SG_ 960 Klemmen_Status_01_BZ 1000;
BA_REL_ "GenSigTimeoutTime" BU_SG_REL_ Motor_BEV SG_ 960 ZAS_Kl_15 1000;
BA_REL_ "GenSigTimeoutTime" BU_SG_REL_ Motor_BEV SG_ 960 ZAS_Kl_50_Startanforderung 1000;
BA_REL_ "GenSigTimeoutTime" BU_SG_REL_ Motor_BEV SG_ 1420 KST_Anf_Klemme_50 5000;
BA_REL_ "GenSigTimeoutTime" BU_SG_REL_ Motor_BEV SG_ 949 KL_Thermomanagement 1000;
BA_REL_ "GenSigTimeoutTime" BU_SG_REL_ Motor_BEV SG_ 949 KL_Anf_KL 1000;
BA_REL_ "GenSigTimeoutTime" BU_SG_REL_ Motor_BEV SG_ 949 KL_Anf_KV 1000;
BA_REL_ "GenSigTimeoutTime" BU_SG_REL_ Motor_BEV SG_ 1511 KL_HV_Heizer_Strom 2000;
BA_REL_ "GenSigTimeoutTime" BU_SG_REL_ Motor_BEV SG_ 1511 KL_EKK_Strom 2000;
BA_REL_ "GenSigTimeoutTime" BU_SG_REL_ Motor_BEV SG_ 1511 KL_Pumpe_02_Soll 2000;
BA_REL_ "GenSigTimeoutTime" BU_SG_REL_ Motor_BEV SG_ 1511 KL_Status_EoHVL_EKK 2000;
BA_REL_ "GenSigTimeoutTime" BU_SG_REL_ Motor_BEV SG_ 1511 KL_Status_EoHVL_Heizer 2000;
BA_REL_ "GenSigTimeoutTime" BU_SG_REL_ Motor_BEV SG_ 1505 BCM1_Aussen_Temp_ungef 2000;
BA_REL_ "GenSigTimeoutTime" BU_SG_REL_ Motor_BEV SG_ 982 LH_3_Bremsl_def 1000;
BA_REL_ "GenSigTimeoutTime" BU_SG_REL_ Motor_BEV SG_ 982 LH_Bremsl_li_ges_def 1000;
BA_REL_ "GenSigTimeoutTime" BU_SG_REL_ Motor_BEV SG_ 982 LH_Bremsl_re_ges_def 1000;
BA_REL_ "GenSigTimeoutTime" BU_SG_REL_ Motor_BEV SG_ 134 LWI_01_CRC 500;
BA_REL_ "GenSigTimeoutTime" BU_SG_REL_ Motor_BEV SG_ 134 LWI_01_BZ 500;
BA_REL_ "GenSigTimeoutTime" BU_SG_REL_ Motor_BEV SG_ 134 LWI_Sensorstatus 500;
BA_REL_ "GenSigTimeoutTime" BU_SG_REL_ Motor_BEV SG_ 134 LWI_QBit_Lenkradwinkel 500;
BA_REL_ "GenSigTimeoutTime" BU_SG_REL_ Motor_BEV SG_ 134 LWI_Lenkradwinkel 500;
BA_REL_ "GenSigTimeoutTime" BU_SG_REL_ Motor_BEV SG_ 134 LWI_VZ_Lenkradwinkel 500;
BA_REL_ "GenSigTimeoutTime" BU_SG_REL_ Motor_BEV SG_ 817 MFL_Tip_Down 5000;
BA_REL_ "GenSigTimeoutTime" BU_SG_REL_ Motor_BEV SG_ 817 MFL_Tip_Up 5000;
BA_REL_ "GenSigTimeoutTime" BU_SG_REL_ Schaltbetaetigung SG_ 960 ZAS_Kl_15 1000;
VAL_ 1452 HVEM_IstStrom_HVVerbraucher 4094 "Init" 4095 "Fehler" ;
VAL_ 1452 HVEM_Energie_Klima_Vorgabe_HighR 6 "Init" 7 "Fehler" ;
VAL_ 1452 HVEM_IstLeistungNA 510 "Init" 511 "Fehler" ;
VAL_ 1452 HVEM_Leistung_Klima_Vorgabe 254 "Init" 255 "Fehler" ;
VAL_ 1452 HVEM_Nutzbare_Energie 2045 "Max" 2046 "Init" 2047 "Fehler" ;
VAL_ 1452 HVEM_Energie_Klima_Vorgabe 254 "Init" 255 "Fehler" ;
VAL_ 1452 HVEM_HVK_Aktivitaet 0 "keine_Aktivitaet" 1 "Aktivitaet" 2 "Init" ;
VAL_ 1452 HVEM_Pruefpuls_Anf 0 "Keine_Anforderung" 1 "Anforderung" 2 "Reserved" 3 "Init" ;
VAL_ 1452 HVEM_HV_Anf 0 "keine_Anforderung" 1 "HV_angefordert" ;
VAL_ 1452 HVEM_MO_MaxLeistungIgnoriert 0 "Max_Leistung_nicht_ignoriert" 1 "Max_Leistung_ignoriert" ;
VAL_ 1385 HVEM_DCDC_Freigabe 0 "keine_Freigabe" 1 "Freigabe" ;
VAL_ 1385 HVEM_Ladesteckerentr_Anf 0 "keine_Anforderung" 1 "Anf_Ladestecker_Entr" ;
VAL_ 1385 HVEM_LeistungsAnf 0 "nicht_angefordert" 1 "angefordert" ;
VAL_ 1385 HVEM_Nachlad_Status 0 "nicht_moeglich__Fehler" 1 "moeglich__begonnen" 2 "Beendet" 3 "Init" ;
VAL_ 1385 HVEM_Abschaltstatus 0 "100" 1 "75" 2 "50" 3 "25" 7 "Init" ;
VAL_ 1385 HVEM_Anf_ReichweiteNV 0 "keine_Massnahme_notwendig" 1 "Reduktion_Stufe_1" 2 "Reduktion_Stufe_2" 3 "Fehler" ;
VAL_ 1385 HVEM_LadeklappenVerr_Anf 0 "Init" 1 "Ladeklappe_verriegeln" 2 "Ladeklappe_entriegeln" ;
VAL_ 1385 HVEM_Max_VK_Betriebsdauer 62 "Init" 63 "Fehler" ;
VAL_ 1385 HVEM_HV_Anf 0 "keine_Anforderung" 1 "HV_angefordert" ;
VAL_ 1385 HVEM_Text_1 0 "kein_Text" 1 "Text" ;
VAL_ 1385 HVEM_Nachladen_Anf 0 "keine_Anforderung" 1 "Nachladen_angefordert" ;
VAL_ 1385 HVEM_FreigabeKlimatisierung 0 "keine_Freigabe" 1 "Freigabe" 2 "Init" 3 "Fehler" ;
VAL_ 1385 HVEM_Leistung_Bat_Kond_Vorgabe 254 "Init" ;
VAL_ 1283 HVK_Istmodus_Anf 0 "nicht_angefordert" 1 "angefordert" ;
VAL_ 1283 HVK_TN1_Sollmodus 0 "HV_Off" 1 "HV_On" 2 "reserviert" 3 "Initialisierung" ;
VAL_ 1283 HVK_Vorladung_aktiv 0 "Vorladung_nicht_aktiv" 1 "Vorladung_aktiv" ;
VAL_ 1283 HVK_BMS_Sollmodus 0 "HV_Off" 1 "HV_On" 3 "AC_Laden_erw" 4 "AC_Laden" 6 "DC_Laden" 7 "Init" ;
VAL_ 1283 HVK_DCDC_Sollmodus 0 "Standby" 1 "HV_On_Vorladen" 2 "Tiefsetzen" 3 "Hochsetzen" 4 "Pruefpuls_12V" 7 "Initialisierung" ;
VAL_ 1283 HVK_EKK_Sollmodus 0 "Keine_Freigabe" 1 "Freigabe" 2 "Freigabe_ausgesetzt" 7 "Init" ;
VAL_ 1283 HVK_HVPTC_Sollmodus 0 "Keine_Freigabe" 1 "Freigabe" 2 "Freigabe_ausgesetzt" 7 "Init" ;
VAL_ 1283 HVK_HVLM_Sollmodus 0 "keine_Freigabe" 1 "Freigabe_Lademanager" 7 "Init" ;
VAL_ 1283 HVK_HV_Netz_Warnungen 0 "Keine_Warnung" 1 "Warntext_HV_Netz_Anf" 2 "Fehlertext_HV_Netz_Anf" 3 "Warnung_Kein_Wiederstart_moeglich" ;
VAL_ 1283 HV_Bordnetz_aktiv 0 "inaktiv" 1 "aktiv" ;
VAL_ 1283 HV_Bordnetz_Fehler 0 "kein_Fehler" 1 "Fehler" ;
VAL_ 1283 HVK_Gesamtst_Spgfreiheit 0 "Funktion_Init__ohne_Funktion" 1 "HV_System_spannungsfrei" 2 "HV_System_nicht_spannungsfrei" 3 "Fehler" ;
VAL_ 1283 HVK_AktiveEntladung_Anf 0 "nicht_angefordert" 1 "angefordert" ;
VAL_ 1283 HVK_HVEM_Freigabe 0 "keine_Freigabe" 1 "Freigabe" 2 "Init" ;
VAL_ 1283 HVK_Notentladung_Anf 0 "keine_Anforderung_Notentladung" 1 "Anforderung_Notentladung" 2 "Reserve" 3 "INIT_keine_HV_Zuschaltung" ;
VAL_ 1283 HVK_Iso_Messung_Start 0 "keine_Messung" 1 "Messung_HV_Netz_1" 2 "Messung_HV_Netz_2" 4 "deaktiviert" ;
VAL_ 1283 HVK_Ladebereit 0 "Init_oder_nicht_Ladebereit" 1 "AC_Ladebereit" 2 "DC_Ladebereit" 3 "AC_und_DC_Ladebereit" 4 "Induktiv_Ladebereit" 5 "AC_und_Induktiv_Ladebereit" 6 "DC_und_Induktiv_Ladebereit" 7 "AC_DC_und_Induktiv_Ladebereit" ;
VAL_ 1283 HVK_PPulsFreigabe 0 "keine_Freigabe" 1 "Freigabe" 2 "Reserve" 3 "Init" ;
VAL_ 2463978813 HVL_Steckerstatus 0 "Init" 1 "kein_Stecker_erkannt" 2 "Stecker_erkannt" 3 "Fehler" ;
VAL_ 2463978813 HVL_LadeAnforderung 0 "Laden_nicht_angefordert" 1 "AC_Laden_Angefordert" 2 "DC_Laden_Angefordert" 3 "AC_und_DC_Angefordert" 4 "Induktiv_Laden_Angef" 5 "AC_und_Induktiv_Angef" 6 "DC_und_Induktiv_Angef" 7 "Fehler" ;
VAL_ 626 HVLM_Anforderung_HMS 0 "keine_Anforderung" 1 "halten" 2 "parken" 3 "halten_Standby" 4 "anfahren" 5 "Loesen_ueber_Rampe" ;
VAL_ 626 HVLM_Parken_beibehalten_HMS 0 "Parken_nicht_beibehalten" 1 "Parken_beibehalten" 2 "Init" 3 "Fehler" ;
VAL_ 626 HVLM_WakeUpZaehlerResetAnf 0 "keine_Anforderung" 1 "Reset_Zaehler" ;
VAL_ 626 HVLM_AWC_VerbautStatus 0 "Init" 1 "nicht_verbaut" 2 "verbaut" 3 "Fehler" ;
VAL_ 626 HVLM_Steckerstatus_A 0 "Init" 1 "kein_Stecker_erkannt" 2 "Stecker_steckt_nicht_verriegelt" 3 "Stecker_steckt_und_verriegelt" 7 "Fehler" ;
VAL_ 626 HVLM_Steckerstatus_B 0 "Init" 1 "kein_Stecker_erkannt" 2 "Stecker_steckt_nicht_verriegelt" 3 "Stecker_steckt_und_verriegelt" 7 "Fehler" ;
VAL_ 626 HVLM_Start_Pulserkennung 0 "keine_Anforderung" 1 "Pulserkennung_starten" ;
VAL_ 626 HVLM_ZustandLadeablauf 0 "Init" 1 "Stby_Ladevorbed_erfuellt" 2 "Stby_Ladevorbed_nicht_erfuellt" 4 "Laden_starten" 5 "Laden_beenden" 6 "HVBatterie_Laden" 7 "HVBatterie_Entladen" 8 "Erhaltungsladen" ;
VAL_ 626 HVLM_DC_Aufstartmodus 0 "keine_Anforderung" 1 "Angleich_Fahrzeug" 2 "Angleich_LS_1" 3 "Angleich_LS_2" ;
VAL_ 626 HVLM_Ladeszenario 0 "Aus" 1 "Timerladen_abgeschlossen" 2 "Sofortladen_abgeschlossen" 3 "Optimiertes_Laden_abgeschlossen" 4 "Timerladen_aktiv" 5 "Sofortladen_aktiv" 6 "Optimiertes_Laden_aktiv" 7 "Timerladen_warten" 8 "Optimiertes_Laden_warten" 9 "Keine_Netzspannung" 10 "Fehler_Verriegelung" 11 "Fehler_Ladesytem" 12 "Init_Ladekommunikation" 30 "Init" 31 "Fehler" ;
VAL_ 626 HVLM_Ladevorgang_Anf 0 "Laden_nicht_angefordert" 1 "AC_Laden_Angefordert" 2 "DC_Laden_Angefordert" 3 "AC_und_DC_Angefordert" 4 "Induktiv_Laden_Angef" 5 "AC_und_Induktiv_Angef" 6 "DC_und_Induktiv_Angef" 7 "AC_DC_und_Induktiv_Angef" ;
VAL_ 626 HVLM_Intensitaet 126 "Init" 127 "Fehler" ;
VAL_ 626 HVLM_Laden_ISO_Messung_Anf 0 "Anforderung" 1 "keine_Anforderung" ;
VAL_ 268 ImoCord_Auth_Aufforderung_WFS 0 "nicht_anfordern" 1 "anfordern" ;
VAL_ 2527679583 Parken_Seitenspiegel_Anf 0 "Keine_Anforderung" 1 "Seitenspiegel_anklappen" 2 "Seitenspiegel_abklappen" ;
VAL_ 2527679583 Parken_ZV_Schliessen 0 "Keine_Anforderung" 1 "ZV_verriegeln" 2 "ZV_safen" ;
VAL_ 2527679583 Parken_aktives_System_02 0 "Init" 1 "Keine_Aktivitaet" 2 "RPA" 3 "IPA" 4 "MA" 5 "TP" 6 "rTP" 7 "AAA" 8 "rAAA" 9 "ARA_1" 10 "PLA" 11 "RBF" 12 "PHP" ;
VAL_ 2527679583 Parken_ZR_Sondermodus_Anf 0 "Init" 1 "Keine_Anforderung" 2 "Anforderung_Sondermodus" ;
VAL_ 2527679583 Parken_Schluesselsuche_Anf 0 "keine_Anforderung" 1 "Anforderung_Schluesselsuche" ;
VAL_ 2527679583 Parken_FFB_LED_Anf 0 "keine_Anforderung" 1 "Abbruch_Fehler" 2 "Bereit_OK" 3 "Beendet" ;
VAL_ 2527679583 Parken_Wegfahrsperren_Anf 0 "keine_Anforderung" 1 "Anforderung_Fahreruebernahme" 2 "Anforderung_Fahreruebergabe" ;
VAL_ 2527679583 Parken_Aktivierungslicht_Anf 0 "keine_Anforderung" 1 "Aktivierungslicht" ;
VAL_ 2527679583 Parken_Fahrtrichtungslicht_Anf 0 "keine_Anforderung" 1 "Vorwaerts" 2 "Rueckwaerts" ;
VAL_ 2527679583 Parken_Lichtnachlauf_Anf 0 "keine_Anforderung" 1 "Anforderung_Lichtnachlauf" ;
VAL_ 2527679583 Parken_Fahrerhinweise_Anf 0 "keine_Anforderung" 1 "Fahrerhinweise_anzeigen" ;
VAL_ 2527679583 Parken_Bestaetigungsblinken_Anf 0 "keine_Anforderung" 1 "Erfolgsblinken_Einparken" 2 "Abbruchsblinken" 3 "Erfolgsblinken_Ausparken" ;
VAL_ 2527679583 Parken_Fahrbereitschaftlicht_Anf 0 "keine_Anforderung" 1 "Fahrbereitschaftslicht" ;
VAL_ 2527679583 Parken_Lichtsteuerung_Anf 0 "keine_Anforderung" 1 "Automatik_Lichtmodus_aktivieren" ;
VAL_ 2527679583 IPA_Anf_Meldungen 0 "keine Meldung" 1 "beendet" 2 "Fahrinf_Bremse_FT_betaetigen" 3 "Suche_fortsetzen_ESC_Eingriff" 4 "n_a_temp_ESC_deaktiviert" 5 "n_a_temp_Anhaengerbetrieb" 6 "Suche_Zeitlimit_ueberschritten" 8 "Fahrinf_PaLueSu_aufschalten" 9 "Stby_Bremse_u_FT_druecken" 10 "PosOK_Stillstandszeit" 11 "Stby_FT_druecken" 12 "AP_nicht_moeglich" 13 "Fahrinf_Bremse_loesen_Umfeld" 14 "n_a_temp_Tuer_Heckklappe_offen" 15 "Stby_Tuer_Heckklappe_schliessen" 16 "PP_aktiv_nur_aussen_bedienbar" 17 "PP_Fzg_verlassen" 18 "n_a_Offroad_Modus" 19 "PP_Schluessel_oder_App_bedienen" 20 "PP_App_bedienen" 21 "PP_Schluessel_bedienen" 22 "n_a_temp" 23 "Systemstoerung_Service" 24 "n_a_temp_Sensorsicht" 25 "n_a_temp_Spiegel_ausklappen" 26 "GP_Stoerung_Service" 27 "n_a_temp_FAS_aktiv" 28 "PP_BT_unterbrochen" 29 "Hindernis_in_Fahrtrichtung" 30 "Ausparken_Fahrtrichtung_vorgeben" 32 "Suche_Rangierflaeche_zu_klein" 33 "n_a_temp_Drive_Select" 34 "Fahrinf_Bremse_loesen" 35 "Fahrinf_Fahrtrichtungswechsel" 36 "Fahrinf_Bremse_FT_RT_betaetigen" 37 "GP_Fzgposition_vor_Garage" 38 "GP_RT_Garage_oeffnen" 39 "GP_Kein_Zuparken" 40 "Suche_Fahrinfo_beachten" 41 "GP_Fzgposition_freie_Parkflaeche" 42 "GP_n_a_temp_Laser" 43 "Geschwindigkeitsueberschreitung" 44 "Fahrinf_Weiter_vorfahren" 45 "Fahrinf_Bremsbetaetigug" 46 "Fahrinf_Anhalten" 47 "GP_AP_nicht_moeglich_Fahrweg" 48 "PP_Gang_Schluesselauthentifizier" 49 "Fahrhinweis_FT_betaetigen" 50 "PP_aktiv_Hinweis_FUEN" 128 "Disclaimer_LP_rechts" 129 "Disclaimer_LP_links" 130 "Disclaimer_RQ_rechts" 131 "Disclaimer_RQ_links" 132 "Disclaimer_VQ_rechts" 133 "Disclaimer_VQ_links" 134 "Disclaimer_AP_rechts" 135 "Disclaimer_AP_links" 136 "Disclaimer_Bremse_loesen" 137 "Abbruch_Lenkeingriff_Fahrer" 138 "Abbruch_Anhaenger_erkannt" 139 "Abbruch_max_Rangierzuege" 140 "Abbruch_Zeitlimit_ueberschritten" 141 "Beendet_Bitte_uebernehmen" 142 "Beendet" 143 "Abbruch_Fahrpedaleingriff" 144 "Abbruch_ESC_Eingriff" 145 "Stby_Verkehr_erkannt" 146 "Abbruch_Spiegel_ausklappen" 147 "Abbruch_Waehlhebeleingriff" 148 "Abbruch_AP_Luecke_zu_klein" 149 "Abbruch_Rangierflaeche_zu_klein" 150 "Abbruch_Sensorsicht" 151 "Beendet_Stoerung_Fzgverbindung" 152 "Beendet_selbst_bremsen" 153 "Abbruch_Hindernis_erkannt" 154 "Abbruch_bitte_uebernehmen" 155 "Beendet_Fortsetzung_moeglich" 156 "Stby_Hindernis_erkannt" 157 "FUEN_moeglich" 158 "Abbruch_FUEN_Motor_abgestellt" 159 "Abbruch_Drive_Select" 160 "Abbruch_AP_Seite_versperrt" 161 "PP_Fehler_Schluesselautorisier" 162 "PP_Hinweis_ZV" 163 "PP_Hinweis_Motorabschaltung" 164 "Stby_FT_oder_RT_betaetigen" 165 "Stby_Hindernis_Richtungswechsel" 166 "Stby_erhoehter_Fahrwiderstand" 167 "Abbruch_EPB_aktiviert" 168 "Abbruch_MO_nicht_bereit" 169 "Abbruch_Stoerung_Service" 170 "Abbruch_Gurtschloss_gesteckt" 171 "PP_Abbruch_Rangierbereich" 172 "PP_Abbruch_Verdeckaktivierung" 173 "Abbruch_Bremseingriff_FAS_System" 174 "PP_eingeschraenkt_verfuegbar" 175 "Abbruch" 176 "PosOK_Lenkrad_loslassen_Bremse" 177 "PosOK_Lenkrad_loslassen_FT" 178 "Wiederaufnahme_FT_betaetigen" 179 "PP_beendet_FUEN_moeglich" 180 "Lenkeingriff_beendet" 181 "PP_Abbruch_Zeitlimit" 192 "TPA_aborted_deviated_from_trajec" 193 "TPA_aborted_limited_visibility" 194 "TPA_aborted_localization_failure" 195 "TPA_aborted_System_error" 196 "TPA_aborted_TPA_canceled" 197 "TPA_DNH_Platzhalter" 198 "TPA_DNH_Platzhalter" 199 "TPA_DNH_Platzhalter" 200 "TPA_DNH_Platzhalter" 201 "TPA_DNH_Platzhalter" 202 "TPA_DNH_Platzhalter" 203 "TPA_DNH_Platzhalter" 204 "TPA_DNH_Platzhalter" 205 "TPA_DNH_Platzhalter" 206 "TPA_DNH_Platzhalter" 207 "TPA_DNH_Platzhalter" ;
VAL_ 2527679684 Kamera_ASM_Ereignis 0 "No_Event" 255 "ASM_Trigger" ;
VAL_ 2527679684 Kamera_ASM_Zeitstempel 255 "Init" ;
VAL_ 960 RSt_Fahrerhinweise 0 "Init" 1 "Fahreruebernahme_Hinweis_ZAT_Automat_ohne_Gong" 2 "Fahreruebernahme_Hinweis_ZAT_Automat_mit_Gong" 3 "Fahreruebernahme_Hinweis_ZAT_Handschalter_ohne_Gong" 4 "Fahreruebernahme_Hinweis_ZAT_Handschalter_mit_Gong" 5 "Fahreruebernahme_Hinweis_ZAS_Automat_ohne_Gong" 6 "Fahreruebernahme_Hinweis_ZAS_Automat_mit_Gong" 7 "Fahreruebernahme_Hinweis_ZAS_Handschalter_ohne_Gong" 8 "Fahreruebernahme_Hinweis_ZAS_Handschalter_mit_Gong" 9 "RemoteStart_aktiv_ohne_Gong" 10 "RemoteStart_aktiv_mit_Gong" 11 "void" 12 "void" 13 "void" 14 "void" 15 "void" ;
VAL_ 960 ZAS_Kl_S 0 "aus" 1 "S_Kontakt_ein" ;
VAL_ 960 ZAS_Kl_15 0 "aus" 1 "ein" ;
VAL_ 960 ZAS_Kl_X 0 "aus" 1 "ein" ;
VAL_ 960 ZAS_Kl_50_Startanforderung 0 "aus" 1 "KL50_ein_Startwunsch_Fahrer" ;
VAL_ 960 BCM_Remotestart_Betrieb 0 "kein_RS_Betrieb" 1 "RS_Betrieb" ;
VAL_ 960 ZAS_Kl_Infotainment 0 "inaktiv" 1 "aktiv" ;
VAL_ 960 BCM_Remotestart_KL15_Anf 0 "inaktiv" 1 "aktiv" ;
VAL_ 960 BCM_Remotestart_MO_Start 0 "nicht_angefordert" 1 "angefordert" ;
VAL_ 960 KST_Warn_P1_ZST_def 0 "nicht_defekt" 1 "defekt" ;
VAL_ 960 KST_Warn_P2_ZST_def 0 "nicht_defekt" 1 "defekt" ;
VAL_ 960 KST_Fahrerhinweis_1 0 "inaktiv" 1 "aktiv" ;
VAL_ 960 KST_Fahrerhinweis_2 0 "inaktiv" 1 "aktiv" ;
VAL_ 960 BCM_Ausparken_Betrieb 0 "kein_Betrieb" 1 "Ausparkvorgang_aktiv" ;
VAL_ 960 KST_Fahrerhinweis_4 0 "inaktiv" 1 "aktiv" ;
VAL_ 960 KST_Fahrerhinweis_5 0 "inaktiv" 1 "aktiv" ;
VAL_ 960 KST_Fahrerhinweis_6 0 "inaktiv" 1 "aktiv" ;
VAL_ 2463978753 KST_WFS_Fahrfreigabe_Anforderung 0 "Keine" 1 "Uneingeschraenkt" 2 "Eingeschraenkt" ;
VAL_ 2463978753 KST_Sonderzustand_Status 0 "Init" 1 "Uebergang_neue_Anforderung" 2 "Aktiv" 3 "Fehler" ;
VAL_ 2463978753 KST_Sonderzustand_Anforderung 0 "Init" 1 "RemoteStart" 2 "RemoteParkAssist" 3 "IntelligentParkAssist" 4 "TrainiertesParken" 5 "OnlineRemoteUpdate" 6 "Einfrierschutz" 7 "Klemme15ViaDiagnose" 8 "RueckwandklappenSicherungPDC" 9 "ParkHausPilot" 31 "Fehler" ;
VAL_ 1420 KST_Anf_Klemme_15 0 "nicht_angefordert" 1 "angefordert" ;
VAL_ 1420 KST_Anf_Klemme_50 0 "nicht_angefordert" 1 "angefordert" ;
VAL_ 1420 KST_Anf_Klemme_S 0 "nicht_angefordert" 1 "angefordert" ;
VAL_ 1420 KST_Txt_Werkstatt 0 "Aus" 1 "Ein" ;
VAL_ 1420 KST_Txt_P_Gang 0 "Aus" 1 "Ein" ;
VAL_ 1420 KST_Txt_Panikabschaltung 0 "Aus" 1 "Ein" ;
VAL_ 1420 KST_Anf_Klemmenfreigabe_ELV 0 "nicht_angefordert" 1 "angefordert" ;
VAL_ 1420 KST_Txt_Komfortabschaltung 0 "inaktiv" 1 "aktiv" ;
VAL_ 1420 KST_Unterdr_Zuendungsmeldung 0 "keine_Unterdr_der_Zuendungsmeldung" 1 "Unterdr_der_Zuendungsmeldung_aktiv" ;
VAL_ 1420 KST_aut_Abschaltung_Zuendung 0 "Zuendung_wird_bei_Verl_nicht_deaktiviert" 1 "Zuendung_wird_bei_Verl_deaktiviert" ;
VAL_ 1420 KST_Anf_Klemmenfreigabe_WFS 0 "nicht_angefordert" 1 "angefordert" ;
VAL_ 1420 KST_Anf_ZV_Verriegelung 0 "inaktiv" 1 "aktiv" ;
VAL_ 1420 Relais_VoKo_angesteuert 0 "nicht_angesteuert" 1 "angesteuert" ;
VAL_ 1420 RSt_Anforderung_HMS 0 "keine_Anforderung" 1 "halten" 2 "parken" 3 "halten_Standby" 4 "anfahren" 5 "Loesen_ueber_Rampe" 6 "Parken_mit_P" ;
VAL_ 1420 KST_Zuendungswarnung 0 "keine_Ausgabe_Zuendungswarnung" 1 "Ausg_Zuendungswarnung_Stillstand" 2 "Ausg_Zuendungswarnung_Fahrt" 3 "reserved" ;
VAL_ 1420 KST_Fahrer_Info_Text 0 "nicht_Aktiv" 1 "Fahrerhinweis_1" 2 "Fahrerhinweis_2" ;
VAL_ 949 KL_Drehz_Anh 0 "keine_Anhebung" 1 "Drehzahlanhebung_vom_Motor_angefordert" ;
VAL_ 949 KL_Vorwarn_Komp_ein 0 "Init" 1 "Vorwarnung_Kompressor_ein" ;
VAL_ 949 KL_AC_Schalter 0 "aus" 1 "ein" ;
VAL_ 949 KL_Komp_Moment_alt 1 "veraltet_bzw_Ermittlung_des_Moments_nicht_moeglich__zB_keine_Drehzahl_kein_Kaeltemitteldruck" ;
VAL_ 949 KL_Vorwarn_Zuheizer_ein 0 "keine_Vorwarnung" 1 "Vorwarnung_Zuheizer_ein" ;
VAL_ 949 KL_Zustand 0 "Aus" 1 "Ein" ;
VAL_ 949 KL_Kompressorkupplung_linear 253 "volle_Ansteuerung" 254 "Init__nicht_bedient" ;
VAL_ 949 KL_Charisma_FahrPr 0 "keine_Funktion" 1 "Programm_1" 2 "Programm_2" 3 "Programm_3" 4 "Programm_4" 5 "Programm_5" 6 "Programm_6" 7 "Programm_7" 8 "Programm_8" 9 "Programm_9" 10 "Programm_10" 11 "Programm_11" 12 "Programm_12" 13 "Programm_13" 14 "Programm_14" 15 "Programm_15" ;
VAL_ 949 KL_Charisma_Status 0 "Init" 1 "verfuegbar" 2 "nicht_verfuegbar" 3 "asynchron_durch_Fahrerwunsch" ;
VAL_ 949 KL_nachtr_Stopp_Anf 0 "nicht_angefordert" 1 "angefordert" ;
VAL_ 949 KL_T_Charge 0 "Taster_nicht_betaetigt" 1 "Taster_betaetigt" ;
VAL_ 949 KL_Last_Kompr 255 "Fehler" ;
VAL_ 949 KL_Spannungs_Anf 0 "keine_Anforderung" 1 "Anforderung_Stufe_1" 2 "Anforderung_Stufe_2" 3 "Anforderung_Stufe_3" ;
VAL_ 949 KL_Thermomanagement 0 "keine_Freigabe_TMM__max_Heizbedarf" 1 "kleine_Freigabe_TMM" 2 "mittlere_Freigabe_TMM" 3 "volle_Freigabe_TMM__kein_Heizbedarf" ;
VAL_ 949 KL_StartStopp_Info 0 "Motorlauf_nicht_notwendig_(Stoppfreigabe)" 1 "Motoranlauf_nicht_zwingend_notwendig_(Stoppverbot,keine_Startanforderung)" 2 "Motoranlauf_zwingend_notwendig_(Startanforderung)" 3 "Systemfehler" ;
VAL_ 949 KL_Freilauf_Info 0 "Freilauf_freigegeben" 1 "Uebergang_in_Freilauf_unzulaessig" 2 "Freilauf_nicht_freigegeben_Abbruch" 3 "Freilauf_Anforderung" ;
VAL_ 949 KL_Anf_KL 255 "Fehler" ;
VAL_ 949 KL_el_Zuheizer_Stufe 0 "Aus" 1 "Stufe_1" 2 "Stufe_2" 3 "Stufe_3" ;
VAL_ 949 KL_Ausstattung_Klima 0 "Heizung_elektrisch" 1 "Klimamanuell_elektrisch" 2 "Climatic__1_Zone" 3 "Climatronic__1_Zone" 4 "Climatronic__2_Zonen" 5 "Climatronic__3_Zonen" 6 "Climatronic__4_Zonen" 7 "reserviert" ;
VAL_ 949 KL_Variante_Standheizung 0 "Wasserstandheizung_60_min_Laufzeit" 1 "Luftstandheizung_120_min_Laufzeit" 2 "Wasserstandheizung_120_min_Laufzeit" 3 "Wasser_und_Luftstandheizung_120_min_Laufzeit" ;
VAL_ 949 KL_Anf_KV 126 "Init" ;
VAL_ 1511 KL_HV_Heizer_Strom 255 "Init" ;
VAL_ 1511 KL_EKK_Strom 255 "Init" ;
VAL_ 1511 KL_Pumpe_02_Soll 126 "Init" 127 "Fehler" ;
VAL_ 1511 KL_Ventil_03_Soll 0 "nicht_ansteuern" 1 "Ventil_ansteuern" ;
VAL_ 1511 KL_Ventil_10_Status 0 "Ventil_nicht_angesteuert" 1 "Ventil_angesteuert" 2 "reserviert" 3 "reserviert" 4 "reserviert" 5 "Ventil_nicht_verbaut" 6 "Init" 7 "Fehler" ;
VAL_ 1511 KL_Senderkennung 0 "Sender Climatronic SG" 1 "Sender Waermepumpen SG" ;
VAL_ 1511 WP_KJ_Soll 0 "Init_Keine_Anforderung" 1 "KJ_oeffnen" 2 "KJ_schliessen" 3 "Fehler" ;
VAL_ 1511 KL_Fehler_HV_EKK 0 "Init" 1 "Kein HV Fehler am EKK erkannt" 2 "HV Fehler am EKK erkannt" 3 "Fehler" ;
VAL_ 1511 KL_Fehler_HV_Heizer 0 "Init" 1 "Kein HV Fehler am HV Heizer erkannt" 2 "HV Fehler am HV Heizer erkannt" 3 "Fehler" ;
VAL_ 1511 KL_BattKond_WaPu_DZMax 62 "Init" 63 "Fehler" ;
VAL_ 1511 WP_Kuehlerluefter_Anf 255 "Fehler" ;
VAL_ 1511 KL_KM_ASV_01_Status 0 "Ventil nicht geschaltet" 1 "Ventil geschaltet" 2 "Ventil nicht verbaut" 3 "Fehler" ;
VAL_ 1511 KL_KM_ASV_02_Status 0 "Ventil nicht geschaltet" 1 "Ventil geschaltet" 2 "Ventil nicht verbaut" 3 "Fehler" ;
VAL_ 1511 KL_Vorwarn_HVHeizer_Leistung 0 "Init_Aus" 1 "500W" 2 "1000W" 3 "1500W" 4 "2000W" 5 "2500W" 6 "3000W" 7 "3500W" 8 "4000W" 9 "4500W" 10 "5000W" 11 "5500W" 12 "6000W" 13 "6500W" 14 "7000W" 15 "Fehler" ;
VAL_ 1511 KL_Status_EoHVL_EKK 0 "Init" 1 "Keine_offene_HV_Leitung_erkannt" 2 "offene_HV_Leitung_erkannt" 3 "Fehler" ;
VAL_ 1511 KL_Status_EoHVL_Heizer 0 "Init" 1 "Keine_offene_HV_Leitung_erkannt" 2 "offene_HV_Leitung_erkannt" 3 "Fehler" ;
VAL_ 1505 BCM1_Aussen_Temp_ungef 253 "nicht_verbaut" 254 "Initwert" 255 "Fehler" ;
VAL_ 1505 BCM_Heizungsabsperrventil_Status 0 "HAV_offen" 1 "HAV_geschlossen" 2 "Init_oder_nicht_verbaut" 3 "Fehler" ;
VAL_ 1505 BCM_Heizungspumpe_Status 0 "Pumpe_aus" 1 "Pumpe_aktiv_und_Stauts_iO" 2 "Init_oder_nicht_verbaut" 3 "Fehler" ;
VAL_ 1505 BCM_Kompressorkupplung_Status 0 "Kupplung_offen" 1 "Kupplung_geschlossen" 2 "Init_oder_nicht_verbaut" 3 "Fehler" ;
VAL_ 1505 BCM1_PTC_stufig_Status 0 "Aus" 1 "Stufe_1_aktiv" 2 "Stufe_2_aktiv" 3 "Stufe_3_aktiv" 6 "Init_oder_nicht_verbaut" 7 "Fehler" ;
VAL_ 1505 BCM1_FStatus_Aussentemp_ungef 0 "iO" 1 "niO" ;
VAL_ 1505 BCM1_Kompressorstrom_ist 254 "Init, bzw. nicht verfuegbar" 255 "Fehler" ;
VAL_ 1505 BCM1_OBD_FStatus_ATemp 0 "kein Fehler / Init / nicht verbaut" 1 "KS- (Kurzschluss nach minus)" 2 "KS+ (Kurzschluss nach plus)" 3 "OC (Leitungsunterbrechung)" 4 "OOR+ (Signal zu gross)" 5 "OOR- (Signal zu klein)" 6 "RC+ (Signal unplausibel zu gross)" 7 "RC- (Signal unplausibel zu klein)" 8 "KS+/OC (Kurzschluss nach plus/Unterbrechung)" 9 "KS-/OC  (Kurzschluss nach minus/Unterbrechung)" 10 "KS-/KS+  (Kurzschluss nach minus/plus)" 11 "KS-/KS+/OC (Kurzschluss nach minus/plus/Unterbrechung)" 12 "frei" 13 "frei" 14 "frei" 15 "frei" ;
VAL_ 2549088277 Airbag_01_KompSchutz 0 "inaktiv" 1 "aktiv" ;
VAL_ 2549088277 Airbag_01_Abschaltstufe 0 "keine_Einschraenkung" 1 "Funktionseinschraenkung" ;
VAL_ 2549088277 Airbag_01_Transport_Mode 0 "keine_Einschraenkung" 1 "Funktionseinschraenkung" ;
VAL_ 2549088277 Airbag_01_Nachlauftyp 0 "Komm_bei_KL15_EIN" 1 "Komm_nach_KL15_AUS" 2 "Komm_bei_KL15_AUS" ;
VAL_ 2549088277 NM_Airbag_01_Wakeup 0 "Peripherie_Wakeup__Ursache_nicht_bekannt" 1 "Bus_Wakeup" 2 "KL15_HW" ;
VAL_ 2549088277 KN_AB_DiagPfad 0 "aktiv" 1 "inaktiv" ;
VAL_ 2549088277 AB_KD_Fehler 0 "kein_KD_Fehler" 1 "KD_Fehler" ;
VAL_ 2549088380 EMotor_KompSchutz 0 "inaktiv" 1 "aktiv" ;
VAL_ 2549088380 EMotor_01_Abschaltstufe 0 "keine_Einschraenkung" 1 "Funktionseinschraenkung" ;
VAL_ 2549088380 EMotor_01_Transport_Mode 0 "keine_Einschraenkung" 1 "Funktionseinschraenkung" ;
VAL_ 2549088380 EMotor_Nachlauftyp 0 "Komm_bei_KL15_EIN" 1 "Komm_nach_KL15_AUS" 2 "Komm_bei_KL15_AUS" ;
VAL_ 2549088380 NM_EMotor_01_Wakeup 0 "Peripherie_Wakeup__Ursache_nicht_bekannt" 1 "Bus_Wakeup" 2 "KL15_HW" ;
VAL_ 2549088380 KN_EM_HYB_DiagPfad 0 "aktiv" 1 "inaktiv" ;
VAL_ 2549088380 EM_HYB_KD_Fehler 0 "kein_KD_Fehler" 1 "KD_Fehler" ;
VAL_ 2549088272 Gateway_KompSchutz 0 "inaktiv" 1 "aktiv" ;
VAL_ 2549088272 Gateway_Abschaltstufe 0 "keine_Einschraenkung" 1 "Funktionseinschraenkung" ;
VAL_ 2549088272 Gateway_Transport_Mode 0 "keine_Einschraenkung" 1 "Funktionseinschraenkung" ;
VAL_ 2549088272 Gateway_Nachlauftyp 0 "Komm_bei_KL15_EIN" 1 "Komm_nach_KL15_AUS" 2 "Komm_bei_KL15_AUS" ;
VAL_ 2549088272 NM_Gateway_Wakeup 0 "Peripherie_Wakeup__Ursache_nicht_bekannt" 1 "Bus_Wakeup" 2 "KL15_HW" 3 "ACAN_Wakeup" 4 "FCAN_Wakeup" 5 "KCAN_Wakeup" 6 "ICAN_Wakeup" 7 "DiagCAN_Wakeup" 8 "ECAN_Wakeup" 9 "Energie_LIN_Wakeup" 10 "Bedien_LIN_Wakeup" 11 "HybridCAN_Wakeup" 12 "Flexray_Wakeup" 13 "MFL_WakeUp" 14 "Ethernet" 15 "DCAN_Wakeup" 16 "K2CAN_Wakeup" 32 "FlexRay_Branch1_WakeUp" 33 "FlexRay_Branch2_WakeUp" 34 "FlexRay_Branch3_WakeUp" 35 "FlexRay_Branch4_WakeUp" 36 "FlexRay_Branch5_WakeUp" 37 "FlexRay_Branch6_WakeUp" 38 "FlexRay_Branch7_WakeUp" 39 "FlexRay_Branch8_WakeUp" 40 "FlexRay_Branch9_WakeUp" 41 "FlexRay_Branch10_WakeUp" 42 "FlexRay_Branch11_WakeUp" 43 "FlexRay_Branch12_WakeUp" 44 "FlexRay_Branch13_WakeUp" 45 "FlexRay_Branch14_WakeUp" 46 "FlexRay_Branch15_WakeUp" 47 "FlexRay_Branch16_WakeUp" 128 "Energiemanagement" 129 "Funktionswakeup_OBDC" 130 "Hochvoltenergiemanagement" 131 "CWU_empfangen" 132 "Fuer_Bus_relevanten_FC_empfangen" 133 "OnlineDienst_empfangen" 134 "HV_Aktivieren" 135 "HV_Deaktivieren" 136 "VTS_Suche_DriverCard" 137 "VTS_Hupen_Blinken" 138 "Remote_Vehicle_Status" 139 "Plug_and_Charge" 140 "VTS_Wakeup_Infotainment" 141 "CCAN_Wakeup" 142 "NFcGW_fordert_OTA_FC_an" ;
VAL_ 2549088272 KN_GW_DiagPfad 0 "aktiv" 1 "inaktiv" ;
VAL_ 2549088272 GW_KD_Fehler 0 "kein_KD_Fehler" 1 "KD_Fehler" ;
VAL_ 2549088440 LE2_KompSchutz 0 "inaktiv" 1 "aktiv" ;
VAL_ 2549088440 LE2_Abschaltstufe 0 "keine_Einschraenkung" 1 "Funktionseinschraenkung" ;
VAL_ 2549088440 LE2_Transport_Mode 0 "keine_Einschraenkung" 1 "Funktionseinschraenkung" ;
VAL_ 2549088440 LE2_Nachlauftyp 0 "Komm_bei_KL15_EIN" 1 "Komm_nach_KL15_AUS" 2 "Komm_bei_KL15_AUS" ;
VAL_ 2549088440 NM_LE2_Wakeup 0 "Peripherie_Wakeup__Ursache_nicht_bekannt" 1 "Bus_Wakeup" 2 "KL15_HW" 3 "KL_30__Reset" ;
VAL_ 2549088440 KN_LE2_DiagPfad 0 "aktiv" 1 "inaktiv" ;
VAL_ 2549088440 LE2_KD_Fehler 0 "kein_KD_Fehler" 1 "KD_Fehler" ;
VAL_ 2549088374 Motor_KompSchutz 0 "inaktiv" 1 "aktiv" ;
VAL_ 2549088374 MO_01_Abschaltstufe 0 "keine_Einschraenkung" 1 "Funktionseinschraenkung" ;
VAL_ 2549088374 MO_01_Transport_Mode 0 "keine_Einschraenkung" 1 "Funktionseinschraenkung" ;
VAL_ 2549088374 Motor_Nachlauftyp 0 "Komm_bei_KL15_EIN" 1 "Komm_nach_KL15_AUS" 2 "Komm_bei_KL15_AUS" ;
VAL_ 2549088374 KN_Motor_ECUKnockOutTimer 63 "ECUKnockOut_deaktiviert" ;
VAL_ 2549088374 KN_Motor_BusKnockOut 0 "Funktion_nicht_ausgeloest" 1 "Veto_aktiv" 2 "Funktion_ausgeloest" 3 "Funktion_deaktiviert" ;
VAL_ 2549088374 KN_Motor_BusKnockOutTimer 255 "BusKnockOut_deaktiviert" ;
VAL_ 2549088374 NM_MO_01_Wakeup 0 "Peripherie_Wakeup__Ursache_nicht_bekannt" 1 "Bus_Wakeup" 2 "KL15_HW" 3 "Oelstandsmessung" 4 "Evakuierung_SCR_System" 5 "Drucktankbetankung" 6 "KL50_HW" 7 "Fahrstufenwechsel" ;
VAL_ 2549088374 KN_Motor_ECUKnockOut 0 "Funktion_nicht_ausgeloest" 1 "Veto_war_aktiv" 2 "Funktion_ausgeloest" 3 "Funktion_deaktiviert" ;
VAL_ 2549088374 KN_MO_DiagPfad 0 "aktiv" 1 "inaktiv" ;
VAL_ 2549088374 MO_KD_Fehler 0 "kein_KD_Fehler" 1 "KD_Fehler" ;
VAL_ 982 LH_Aussenlicht_def 0 "OK" 1 "defekt" ;
VAL_ 982 LH_Standlicht_H_aktiv 1 "Standlicht hinten aktiv" ;
VAL_ 982 LH_Parklicht_HL_aktiv 0 "nicht aktiv" 1 "Parklicht hinten links aktiv" ;
VAL_ 982 LH_Parklicht_HR_aktiv 0 "nicht aktiv" 1 "Parklicht hinten rechts aktiv" ;
VAL_ 982 LH_Bremslicht_H_aktiv 1 "Bremslicht hinten aktiv" ;
VAL_ 982 LH_Nebelschluss_aktiv 0 "nicht aktiv" 1 "aktiv" ;
VAL_ 982 LH_Rueckfahrlicht_aktiv 0 "nicht aktiv" 1 "aktiv" ;
VAL_ 982 LH_Blinker_HL_akt 1 "Blinker hinten links aktiv" ;
VAL_ 982 LH_Blinker_HR_akt 1 "Blinker hinten rechts aktiv" ;
VAL_ 982 LH_Blinker_li_def 0 "OK" 1 "Blinker hinten links defekt" ;
VAL_ 982 LH_Bremsl_li_def 0 "OK" 1 "mindestens ein Bremslicht hinten links defekt" ;
VAL_ 982 LH_Schlusslicht_li_def 0 "OK" 1 "mindestens ein Schlusslicht hinten links defekt" ;
VAL_ 982 LH_Rueckf_li_def 0 "OK" 1 "Rückfahrlicht hinten links defekt" ;
VAL_ 982 LH_Nebel_li_def 0 "OK" 1 " Nebelschlusslicht hinten links defekt" ;
VAL_ 982 LH_Schluss_Brems_Nebel_li_def 0 "iO" 1 "defekt" ;
VAL_ 982 LH_Schluss_Brems_Nebel_re_def 0 "iO" 1 "defekt" ;
VAL_ 982 LH_Zusatzschlussl_def 0 "OK" 1 "mindestens_ein_Zusatzschlusslicht_defekt" ;
VAL_ 982 LH_Schluss_Brems_li_def 0 "OK" 1 "defekt" ;
VAL_ 982 LH_Schluss_Nebel_li_def 0 "OK" 1 "defekt" ;
VAL_ 982 LH_SL_BRL_BLK_li_def 0 "OK" 1 "defekt" ;
VAL_ 982 LH_Brems_Blk_li_def 0 "OK" 1 "defekt" ;
VAL_ 982 LH_Diag_Status_re_def 0 "OK" 1 "Aussenlict_Diagnose_Systemstoerung_rechts" ;
VAL_ 982 LH_Diag_Status_li_def 0 "OK" 1 "Aussenlicht_Diagnose_Systemstoerung_links" ;
VAL_ 982 LH_Diag_LED_li_def 0 "OK" 1 "Heckleuchte_links_defekt" ;
VAL_ 982 LH_Diag_LED_re_def 0 "OK" 1 "Heckleuchte_rechts_defekt" ;
VAL_ 982 LH_Blinker_re_def 0 "OK" 1 "Blinker hinten rechts defekt" ;
VAL_ 982 LH_Bremsl_re_def 0 "OK" 1 "mindestens ein Bremslicht hinten rechts defekt" ;
VAL_ 982 LH_Schlusslicht_re_def 0 "OK" 1 "mindestens ein Schlusslicht hinten rechts defekt" ;
VAL_ 982 LH_Rueckf_re_def 0 "OK" 1 "Rückfahrlicht hinten rechts defekt" ;
VAL_ 982 LH_Nebel_re_def 0 "OK" 1 "Nebelschlusslicht hinten rechts defekt" ;
VAL_ 982 LH_Schluss_Brems_mi_def 0 "OK" 1 "Defekt" ;
VAL_ 982 LH_Schluss_Brems_re_def 0 "OK" 1 "defekt" ;
VAL_ 982 LH_Schluss_Nebel_re_def 0 "OK" 1 "defekt" ;
VAL_ 982 LH_SL_BRL_BLK_re_def 0 "OK" 1 "defekt" ;
VAL_ 982 LH_Brems_Blk_re_def 0 "OK" 1 "defekt" ;
VAL_ 982 LH_Kennzl_def 0 "OK" 1 "Kennzeichenbeleuchtung hinten defekt" ;
VAL_ 982 LH_3_Bremsl_def 0 "OK" 1 "hochgesetzte  Bremsleuchte defekt" ;
VAL_ 982 LH_Nebel_mi_def 0 "OK" 1 " Nebelschlusslicht hinten Mitte defekt" ;
VAL_ 982 LH_Rueckf_mi_def 0 "OK" 1 "Rückfahllicht Mitte defekt" ;
VAL_ 982 LH_Schlusslicht_mi_def 0 "OK" 1 "defekt" ;
VAL_ 982 LH_Bremsl_li_ges_def 0 "OK" 1 "Alle Bremslichter hinten links defekt" ;
VAL_ 982 LH_Bremsl_re_ges_def 0 "OK" 1 "Alle Bremslichter hinten rechts defekt" ;
VAL_ 982 LH_Bremsl_mi_def 0 "OK" 1 "defekt" ;
VAL_ 982 BRL_als_SHL 0 "nicht_aktiv" 1 "aktiv" ;
VAL_ 134 LWI_Sensorstatus 0 "iO" 1 "nicht kalibriert" ;
VAL_ 134 LWI_QBit_Sub_Daten 0 "LWS-Subinfo 'real' (Lenkradwinkelinformation ADS-tauglich) " 1 "LWS-Subinfo 'simuliert' (Lenkradwinkelinformation nicht ADS-tauglich )" ;
VAL_ 134 LWI_QBit_Lenkradwinkel 0 "gültiger Wert" 1 "ausserhalb der Spezifikation" ;
VAL_ 134 LWI_Lenkradwinkel 8190 "Init" 8191 "Fehler" ;
VAL_ 134 LWI_VZ_Lenkradwinkel 0 "positiv_links_von_der_Nullstellung" 1 "negativ" ;
VAL_ 134 LWI_VZ_Lenkradw_Geschw 0 "positiv_links_von_der_Nullstellung" 1 "negativ" ;
VAL_ 134 LWI_Lenkradw_Geschw 510 "Init" 511 "Fehler" ;
VAL_ 817 MFL_Lokalaktiv 0 "war_nicht_lokal_aktiv" 1 "war_lokal_aktiv" ;
VAL_ 817 MFL_M_Taste 0 "nicht_betaetigt" 1 "betaetigt" ;
VAL_ 817 MFL_Paddle_Verbau 0 "verbaut" 1 "nicht_verbaut" ;
VAL_ 817 MFL_Tastencode_1 0 "Key_Released__No_Key" 1 "Context_Menu" 2 "Menu_Up__Next_Screen" 3 "Menu_Down__Previous_Screen" 4 "Up" 5 "Down" 6 "Up__Down_ThumbWheel" 7 "OK__ThumbWheel_Button" 8 "Cancel__Escape" 9 "Main_Menu" 10 "Side_Menu_left" 11 "Side_Menu_right" 12 "FAS_Menu" 13 "Left__Right_ThumbWheel" 16 "Volume_Up" 17 "Volume_Down" 18 "Volume_Up__Down_ThumbWheel" 19 "Volume_ThumbWheel_Button" 20 "Audio_Source" 21 "Arrow_A_Up__Right" 22 "Arrow_A_Down__Left" 23 "Arrow_B_Up__Right" 24 "Arrow_B_Down__Left" 25 "PTT__PushToTalk" 26 "PTT_Cancel" 27 "Route_Info" 28 "Hook" 29 "Hang_Up" 30 "Off_Hook" 31 "Light_On__Off" 32 "Mute" 33 "Joker1" 34 "Joker2" 35 "View" 36 "Arrow_A_Up__Down_ThumbWheel" 37 "Lenkradheizung" 38 "Rekuperation" 39 "Tube_Toggle" 100 "MAP" 101 "MAP_Boost" 102 "Turn_signal_left" 103 "Turn_signal_right" 104 "Turn_signal_off" 105 "Flashlight" 106 "Highbeam" 107 "Washer_button" 108 "Wiper_button_left" 109 "Wiper_button_right" 110 "Wiper_button_cancel" 111 "Exhaust_Sound" 112 "Drive_Select_button" 113 "Sport_button" 114 "ESP_Drift_Selection_ThumbWheel" 115 "PTT_special_vehicle" 116 "TravelAssist" 240 "Startup_Reset" 241 "Initialization" ;
VAL_ 817 MFL_Tastencode_2 0 "Key_Released__No_Key" 1 "Context_Menu" 2 "Menu_Up__Next_Screen" 3 "Menu_Down__Previous_Screen" 4 "Up" 5 "Down" 6 "Up__Down_ThumbWheel" 7 "OK__ThumbWheel_Button" 8 "Cancel__Escape" 9 "Main_Menu" 10 "Side_Menu_left" 11 "Side_Menu_right" 12 "FAS_Menu" 13 "Left__Right_ThumbWheel" 16 "Volume_Up" 17 "Volume_Down" 18 "Volume_Up__Down_ThumbWheel" 19 "Volume_ThumbWheel_Button" 20 "Audio_Source" 21 "Arrow_A_Up__Right" 22 "Arrow_A_Down__Left" 23 "Arrow_B_Up__Right" 24 "Arrow_B_Down__Left" 25 "PTT__PushToTalk" 26 "PTT_Cancel" 27 "Route_Info" 28 "Hook" 29 "Hang_Up" 30 "Off_Hook" 31 "Light_On__Off" 32 "Mute" 33 "Joker1" 34 "Joker2" 35 "View" 36 "Arrow_A_Up_Right_Down_Left_ThumbWheel" 37 "Lenkradheizung" 38 "Rekuperation" 39 "Tube_Toggle" 100 "MAP" 101 "MAP_Boost" 102 "Turn_signal_left" 103 "Turn_signal_right" 104 "Turn_signal_off" 105 "Flashlight" 106 "Highbeam" 107 "Washer_button" 108 "Wiper_button_left" 109 "Wiper_button_right" 110 "Wiper_button_cancel" 111 "Exhaust_Sound" 112 "Drive_Select_button" 113 "Sport_button" 114 "ESP_Drift_Selection_ThumbWheel" 115 "PTT_special_vehicle" 116 "TravelAssist" 240 "Startup_Reset" 241 "Initialization" ;
VAL_ 817 MFL_Eventcode_1 0 "W_no_event____T_no_event" 1 "W_1_Tick_up__T_pressed_normal" 2 "W_2_Ticks_up__T_touched" 3 "W_3_Ticks_up__T_double_click_nor" 4 "W_4_Ticks_up__T_long_press_nor_1" 5 "W_5_Ticks_up__T_long_press_nor_2" 6 "W_6_Ticks_up__T_long_press_nor_3" 7 "W_7_Ticks_up" 9 "W_7_Ticks_dn__T_pressed_strong" 10 "W_6_Ticks_dn" 11 "W_5_Ticks_dn__T_double_click_str" 12 "W_4_Ticks_dn__T_long_press_str_1" 13 "W_3_Ticks_dn__T_long_press_str_2" 14 "W_2_Ticks_dn__T_long_press_str_3" 15 "W_1_Tick_dn" ;
VAL_ 817 MFL_Eventcode_2 0 "W_no_event____T_no_event" 1 "W_1_Tick_up__T_pressed_normal" 2 "W_2_Ticks_up__T_touched" 3 "W_3_Ticks_up__T_double_click_nor" 4 "W_4_Ticks_up__T_long_press_nor_1" 5 "W_5_Ticks_up__T_long_press_nor_2" 6 "W_6_Ticks_up__T_long_press_nor_3" 7 "W_7_Ticks_up" 9 "W_7_Ticks_dn__T_pressed_strong" 10 "W_6_Ticks_dn" 11 "W_5_Ticks_dn__T_double_click_str" 12 "W_4_Ticks_dn__T_long_press_str_1" 13 "W_3_Ticks_dn__T_long_press_str_2" 14 "W_2_Ticks_dn__T_long_press_str_3" 15 "W_1_Tick_dn" ;
VAL_ 817 MFL_Marke 0 "VW" 1 "Audi" 2 "Seat" 3 "Skoda" 4 "VW_Nutzf" 5 "Bugatti" 6 "Lamborghini" 7 "Bentley" 8 "Rolls Royce" 9 "Quattro" 10 "kein_Hersteller_1" 11 "kein_Hersteller_2" 12 "kein_Hersteller_3" 13 "kein_Hersteller_4" 14 "Ford" 15 "Porsche" ;
VAL_ 817 MFL_Tip_Down 0 "nicht_betaetigt" 1 "betaetigt" ;
VAL_ 817 MFL_Tip_Up 0 "nicht_betaetigt" 1 "betaetigt" ;
VAL_ 817 MFL_SatModul_links_Err 0 "kein_Fehler" 1 "Fehler" ;
VAL_ 817 MFL_SatModul_rechts_Err 0 "kein_Fehler" 1 "Fehler" ;
VAL_ 817 MFL_LR_HZG_Status 0 "inaktiv" 1 "aktiv" ;
VAL_ 817 MFL_LR_HZG_Err 0 "normal" 1 "Fehler" ;
VAL_ 817 MFL_Signalhorn 0 "nicht_betaetigt" 1 "betaetigt" ;
VAL_ 817 MFL_Signalhorn_Err 0 "normal" 1 "Fehler" ;
VAL_ 817 MFL_Tip_links_Err 0 "normal" 1 "Fehler" ;
VAL_ 817 MFL_Tip_rechts_Err 0 "normal" 1 "Fehler" ;
VAL_ 817 MFL_Taste_links_Err 0 "normal" 1 "Fehler" ;
VAL_ 817 MFL_Taste_rechts_Err 0 "normal" 1 "Fehler" ;
VAL_ 817 MFL_ECU_Err 0 "normal" 1 "Fehler" ;
VAL_ 817 MFL_Response_Err 0 "normal" 1 "Fehler" ;
VAL_ 15 MO_SOPC 0 "kein_SOPC" 1 "SOPC" ;
VAL_ 1600 MO_QBit_Ansaugluft_Temp 0 "gueltiger_Wert" 1 "Ersatz_Init_oder_Fehlerwert" ;
VAL_ 1600 MO_QBit_Oel_Temp 0 "gueltiger_Wert" 1 "Ersatz_Init_oder_Fehlerwert" ;
VAL_ 1600 MO_QBit_Kuehlmittel_Temp 0 "gueltiger_Wert" 1 "Ersatz_Init_oder_Fehlerwert" ;
VAL_ 1600 MO_KL15_Abschaltempfehlung 0 "Keine Empfehlung" 1 "Abschaltempfehlung" ;
VAL_ 1600 MO_HYB_Fehler_HV_Netz 0 "i_O" 1 "kein_generatorischer_Betrieb_moeglich" ;
VAL_ 1600 MO_aktives_Getriebeheizen 0 "kein_Ventil_ansteuern" 1 "Ventil_muss_angesteuert_werden" ;
VAL_ 1600 MO_Absperrventil_oeffnen 0 "nicht_verfuegbar" 1 "Ansteuerung_Ventil_zulaessig" 2 "Ventil_oeffnen_oder_geoeffnet" 3 "Ventil_schliessen_oder_geschlossen" ;
VAL_ 1600 MO_Ansaugluft_Temp 254 "Init" 255 "Fehler" ;
VAL_ 1600 MO_Oel_Temp 253 "nicht_verbaut" 254 "Init" 255 "Fehler" ;
VAL_ 1600 MO_Kuehlmittel_Temp 254 "Init" 255 "Fehler" ;
VAL_ 1600 MO_Hoeheninfo 255 "Fehler" ;
VAL_ 1600 MO_Kennfeldk 0 "keine Kennfeldkühlung vorhanden" 1 "Kennfeldkühlung vorhanden" ;
VAL_ 1600 MO_Versionsinfo_02 0 "zum_Projektbeginn_aufgeraeumter_CAN" 1 "Motor_03_mit_10ms" 16 "MQB_mit_neuer_Momentenschnittstelle" ;
VAL_ 1600 MO_QBit_Hoeheninfo 0 "gueltiger_Wert" 1 "Ersatz_Init_oder_Fehlerwert" ;
VAL_ 1600 MO_Getriebe_kuehlen 0 "nicht_kuehlen" 1 "kuehlen" ;
VAL_ 1600 MO_Heizungspumpenansteuerung 13 "Fehler" 14 "Init" 15 "nicht_verbaut" ;
VAL_ 1600 MO_SpannungsAnf 0 "keine_Anforderung" 1 "Anforderung" ;
VAL_ 167 MO_Mom_Soll_Roh 1022 "Init" ;
VAL_ 167 MO_Mom_Ist_Summe 1022 "Init" ;
VAL_ 167 MO_Mom_Traegheit_Summe 1022 "Init" ;
VAL_ 167 MO_Mom_Soll_gefiltert 1022 "Init" ;
VAL_ 167 MO_Mom_Schub 510 "Init" ;
VAL_ 167 MO_Status_Normalbetrieb_01 0 "kein_Normalbetrieb" 1 "Normalbetrieb_erreicht" ;
VAL_ 167 MO_erste_Ungenauschwelle 0 "genau" 1 "Momente ungenauer >8%" ;
VAL_ 167 MO_QBit_Motormomente 0 "gueltiger_Wert" 1 "Ersatz_Init_oder_Fehlerwert" ;
VAL_ 168 MO_Mom_neg_verfuegbar 510 "Init" 511 "Fehler" ;
VAL_ 168 MO_Mom_Begr_Fahr 510 "Init" 511 "Fehler" ;
VAL_ 168 MO_Mom_Begr_Schalt 1022 "Init" ;
VAL_ 168 MO_QBit_Drehzahl_01 0 "gueltiger_Wert" 1 "Ersatz_Init_oder_Fehlerwert" ;
